VERSION ""

NS_ :

BS_:

BU_: AGSM BCM BSM CADM DMSM DTCM ECM EVCU2 GNMM HCP IPC RFHM SGW TCM
BO_ 1443 IPC_VEHICLE_SETUP: 48 IPC
 SG_ Act_Lane_Mgt : 91|2@0+ (1,0) [0|3] "-" BCM,CADM,SGW
 SG_ Act_Lane_Mgt_Strength : 123|2@0+ (1,0) [0|3] "-" BCM,CADM,SGW
 SG_ Active_Park_Mode : 219|1@0+ (1,0) [0|1] "" BCM,BSM,SGW
 SG_ Active_Park_Prox_Chime : 218|1@0+ (1,0) [0|1] "" BCM,SGW
 SG_ AmbientLightingLevel : 118|4@0+ (1,0) [0|15] "" SGW
 SG_ Auto_Fold_Mirr : 255|1@0+ (1,0) [0|1] "-" BCM,SGW
 SG_ AutoHighBeamEnable : 92|1@0+ (1,0) [0|1] "-" BCM,SGW
 SG_ AutoParkBrake : 103|1@0+ (1,0) [0|1] "" BCM,BSM,SGW
 SG_ AutoUnlockDoorExit : 162|1@0+ (1,0) [0|1] "-" BCM,SGW
 SG_ Backup_Cam_Delay : 173|1@0+ (1,0) [0|1] "-" BCM,SGW
 SG_ BSDEnable : 140|2@0+ (1,0) [0|3] "" BCM,CADM,SGW
 SG_ Consum_Unit : 238|3@0+ (1,0) [0|7] "" BCM,SGW
 SG_ CorneringEnable : 82|1@0+ (1,0) [0|1] "-" BCM,SGW
 SG_ CRC_IPCVS1 : 319|8@0+ (1,0) [0|255] "-" CADM
 SG_ Dist_Unit : 231|1@0+ (1,0) [0|1] "" BCM,ECM,SGW
 SG_ DRLEnable : 80|1@0+ (1,0) [0|1] "-" BCM,SGW
 SG_ Drowsy_Driver_Alert : 120|1@0+ (1,0) [0|1] "-" BCM,CADM,SGW
 SG_ DynamicGrid : 100|1@0+ (1,0) [0|1] "" BCM,SGW
 SG_ Easy_Exit_D : 174|1@0+ (1,0) [0|1] "-" BCM,SGW
 SG_ Eng_Off_Pwr_Delay : 187|2@0+ (1,0) [0|3] "-" BCM,SGW
 SG_ EPB_MaintenanceMode : 155|1@0+ (1,0) [0|1] "-" SGW
 SG_ FlashLightWLock : 159|1@0+ (1,0) [0|1] "-" BCM,SGW
 SG_ FOA_AppAlert_Disable_UserReq : 290|1@0+ (1,0) [0|1] "" BCM
 SG_ FSFCWPlusActivationMode : 149|2@0+ (1,0) [0|3] "-" BCM,CADM,SGW
 SG_ FSFCWPlusSetting : 143|3@0+ (1,0) [0|7] "-" BCM,CADM,SGW
 SG_ Fwrd_Cam_Guidelines : 189|1@0+ (1,0) [0|1] "-" BCM,SGW
 SG_ GreetingLightsEnable : 81|1@0+ (1,0) [0|1] "-" BCM,SGW
 SG_ HeadlightsOffDelay : 145|2@0+ (1,0) [0|3] "-" BCM,SGW
 SG_ HeadLightWipers : 167|1@0+ (1,0) [0|1] "-" BCM,SGW
 SG_ Hill_Start_Assist : 184|1@0+ (1,0) [0|1] "-" BCM,BSM,SGW
 SG_ HourMode : 87|1@0+ (1,0) [0|1] "-" BCM,SGW
 SG_ HP_Unit : 245|2@0+ (1,0) [0|3] "" BCM,SGW
 SG_ Illuminated_Approach : 68|2@0+ (1,0) [0|3] "-" BCM,SGW
 SG_ IPCProgrammed : 40|1@0+ (1,0) [0|1] "-" BCM,SGW
 SG_ LanguageSelection : 135|8@0+ (1,0) [0|255] "-" BCM,SGW
 SG_ LDW_Intensity : 154|2@0+ (1,0) [0|3] "-" BCM,CADM,SGW
 SG_ LDW_Sensibility : 147|2@0+ (1,0) [0|3] "-" BCM,CADM,SGW
 SG_ MessageCounter_IPCVS1 : 307|4@0+ (1,0) [0|15] "-" CADM
 SG_ NavRepetition : 105|1@0+ (1,0) [0|1] "" BCM,SGW
 SG_ New_Spd_Zone_Ind : 247|2@0+ (1,0) [0|3] "" BCM,SGW
 SG_ Paddle_Shifter : 188|1@0+ (1,0) [0|1] "-" BCM,SGW
 SG_ PamChimeVolumeFront : 107|2@0+ (1,0) [0|3] "" BCM,SGW
 SG_ PamChimeVolumeRear : 111|2@0+ (1,0) [0|3] "" BCM,SGW
 SG_ PassiveEntry : 101|1@0+ (1,0) [0|1] "" BCM,RFHM,SGW
 SG_ Ped_EM_Brk_Warn_Act : 175|1@0+ (1,0) [0|1] "-" BCM,SGW
 SG_ PhoneRepetition : 114|1@0+ (1,0) [0|1] "" BCM,SGW
 SG_ PLGAlert : 168|1@0+ (1,0) [0|1] "-" BCM,SGW
 SG_ Power_Side_Step : 220|1@0+ (1,0) [0|1] "" BCM,SGW
 SG_ Proximity_WU : 121|1@0+ (1,0) [0|1] "-" BCM,RFHM,SGW
 SG_ PwrLev : 7|3@0+ (1,0) [0|7] "" BCM,EVCU2,SGW
 SG_ RainSensorLevel : 93|1@0+ (1,0) [0|1] "-" BCM,SGW
 SG_ Rdy_To_Drive : 223|1@0+ (1,0) [0|1] "" SGW
 SG_ Rear_Brk_Asst : 190|1@0+ (1,0) [0|1] "" BCM,SGW
 SG_ RemoteDoorUnlock : 102|1@0+ (1,0) [0|1] "" BCM,SGW
 SG_ RemStNrmlStEnbl : 178|2@0+ (1,0) [0|3] "-" BCM,SGW
 SG_ RKEMemoryLinkEnable : 166|1@0+ (1,0) [0|1] "-" BCM,SGW
 SG_ SOC_Max_Lev : 308|1@0+ (1,0) [0|1] "" EVCU2
 SG_ SoundHornLock : 127|2@0+ (1,0) [0|3] "" BCM,SGW
 SG_ SoundHornRemoteStart : 104|1@0+ (1,0) [0|1] "" BCM,SGW
 SG_ Spaak : 289|1@0+ (1,0) [0|1] "-" BCM,RFHM,SGW
 SG_ Speed_Unit : 253|1@0+ (1,0) [0|1] "" BCM,CADM,SGW
 SG_ SpeedLockDoorEnable : 94|1@0+ (1,0) [0|1] "-" BCM,SGW
 SG_ StaticGrid : 99|1@0+ (1,0) [0|1] "" BCM,SGW
 SG_ Susp_Auto_Ent_Ext : 195|1@0+ (1,0) [0|1] "" BCM,SGW
 SG_ Susp_Aux_Mode : 212|2@0+ (1,0) [0|3] "" BCM,SGW
 SG_ Susp_Disp_Message : 207|1@0+ (1,0) [0|1] "" BCM,SGW
 SG_ Susp_Flsh_Lght_Low : 198|1@0+ (1,0) [0|1] "" BCM,SGW
 SG_ Susp_Sound_Hrn_Low : 199|1@0+ (1,0) [0|1] "" BCM,SGW
 SG_ Susp_Tire_Jack : 200|1@0+ (1,0) [0|1] "" BCM,SGW
 SG_ SVC_Delay : 192|1@0+ (1,0) [0|1] "" BCM,SGW
 SG_ SVC_Guidelines : 193|1@0+ (1,0) [0|1] "" BCM,SGW
 SG_ TelematicSetupACK : 97|2@0+ (1,0) [0|3] "-" BCM,SGW
 SG_ Temp_Unit : 239|1@0+ (1,0) [0|1] "" BCM,SGW
 SG_ Tilt_Mirr_Rev : 210|1@0+ (1,0) [0|1] "" BCM,SGW
 SG_ Tire_Fill_Alert : 215|1@0+ (1,0) [0|1] "" BCM,RFHM,SGW
 SG_ Torque_Unit : 254|1@0+ (1,0) [0|1] "" BCM,SGW
 SG_ Traffic_Sign_Info : 230|1@0+ (1,0) [0|1] "" BCM,CADM,SGW
 SG_ Traffic_Sign_Warn : 171|3@0+ (1,0) [0|3] "" BCM,SGW
 SG_ Trail_Brk_Type : 217|2@0+ (1,0) [0|3] "" BCM,SGW
 SG_ Trail_Name : 235|4@0+ (1,0) [0|16] "" BCM,SGW
 SG_ Trail_Num : 214|2@0+ (1,0) [0|3] "" BCM,SGW
 SG_ Trailer_detection_blind_spot : 310|1@0+ (1,0) [0|1] "-" BCM,CADM,SGW
 SG_ TyrePress_Unit : 243|2@0+ (1,0) [0|3] "" BCM,SGW

BO_ 1474 IPC_VEHICLE_SETUP2: 48 IPC
 SG_ AUX1_HLEnbl : 9|1@0+ (1,0) [0|1] "" BCM,SGW
 SG_ AUX1_PWRMD : 213|1@0+ (1,0) [0|1] "" BCM,SGW
 SG_ AUX1_TYPE : 13|1@0+ (1,0) [0|1] "" BCM,SGW
 SG_ AUX2_HLEnbl : 8|1@0+ (1,0) [0|1] "" BCM,SGW
 SG_ AUX2_PWRMD : 0|1@0+ (1,0) [0|1] "" BCM,SGW
 SG_ AUX2_TYPE : 12|1@0+ (1,0) [0|1] "" BCM,SGW
 SG_ AUX3_HLEnbl : 23|1@0+ (1,0) [0|1] "" BCM,SGW
 SG_ AUX3_PWRMD : 15|1@0+ (1,0) [0|1] "" BCM,SGW
 SG_ AUX3_TYPE : 11|1@0+ (1,0) [0|1] "" BCM,SGW
 SG_ AUX4_HLEnbl : 22|1@0+ (1,0) [0|1] "" BCM,SGW
 SG_ AUX4_PWRMD : 14|1@0+ (1,0) [0|1] "" BCM,SGW
 SG_ AUX4_TYPE : 10|1@0+ (1,0) [0|1] "" BCM,SGW
 SG_ AUX5_HLEnbl : 55|1@0+ (1,0) [0|1] "" BCM,SGW
 SG_ AUX5_PWRMD : 43|1@0+ (1,0) [0|1] "" BCM,SGW
 SG_ AUX5_TYPE : 41|1@0+ (1,0) [0|1] "" BCM,SGW
 SG_ AUX6_HLEnbl : 54|1@0+ (1,0) [0|1] "" BCM,SGW
 SG_ AUX6_PWRMD : 42|1@0+ (1,0) [0|1] "" BCM,SGW
 SG_ AUX6_TYPE : 40|1@0+ (1,0) [0|1] "" BCM,SGW
 SG_ Default_Ride_Height : 44|1@0+ (1,0) [0|1] "" BCM,SGW
 SG_ Display_Synch : 59|1@0+ (1,0) [0|1] "" SGW
 SG_ EPB_Service_Mode : 39|1@0+ (1,0) [0|1] "" BCM,SGW
 SG_ FOA_Alert_Type : 6|2@0+ (1,0) [0|3] "" BCM,SGW
 SG_ Fuel_Saver_Display : 26|1@0+ (1,0) [0|1] "" BCM,SGW
 SG_ ParkSenseSignalView : 37|1@0+ (1,0) [0|1] "" BCM,SGW
 SG_ PFTM_Alert : 95|1@0+ (1,0) [0|1] "" BCM,SGW
 SG_ PFTM_Enable : 94|1@0+ (1,0) [0|1] "" SGW
 SG_ Power_Tailgate_Enable : 53|1@0+ (1,0) [0|1] "" BCM,SGW
 SG_ Rear_G_LGT_with_Cargo_Lights : 47|1@0+ (1,0) [0|1] "" BCM,SGW
 SG_ Rear_Guidance_Light_Status : 62|1@0+ (1,0) [0|1] "" BCM,SGW
 SG_ Rear_Lights_with_Approach : 50|1@0+ (1,0) [0|1] "" BCM,SGW
 SG_ SignatureLightingEnable : 93|1@0+ (1,0) [0|1] "" BCM,SGW
 SG_ Trailer_Light_Check : 7|1@0+ (1,0) [0|1] "" BCM,SGW
 SG_ TSI_Offset_Kph : 31|4@0+ (1,0) [0|15] "" BCM,IPC,SGW
 SG_ TSI_Offset_Mph : 19|4@0+ (1,0) [0|15] "" BCM,IPC,SGW
 SG_ TurnSignalView : 34|2@0+ (1,0) [0|3] "" BCM,SGW
 SG_ WorksiteINVM_Audible_LFW : 61|1@0+ (1,0) [0|1] "" BCM,SGW
 SG_ WorksiteINVM_Visual_LFW : 60|1@0+ (1,0) [0|1] "" BCM,SGW

BO_ 753 LV_CHARGER1: 32 HCP
 SG_ CRC_LV_CHARGER1 : 191|8@0+ (1,0) [0|255] "-" ECM
 SG_ DCDC_OperationModeSts : 7|4@0+ (1,0) [0|0] "-" ECM,SGW
 SG_ HVDC_CurrentFeedback : 3|12@0+ (0.1,-149) [-149|150] "Amp" ECM
 SG_ HVDC_VoltageFeedback : 35|12@0+ (0.125,0) [0|510] "V" ECM
 SG_ LVDC_CurrentFeedback : 19|12@0+ (0.15,-299) [-299|299.5] "Amp" ECM
 SG_ MessageCounter_LV_CHARGER1 : 179|4@0+ (1,0) [0|15] "-" ECM

BO_ 125 MESS_TTPM1: 32 RFHM
 SG_ MESS_TTPM1 : 7|64@0+ (1,0) [0|0] "" SGW

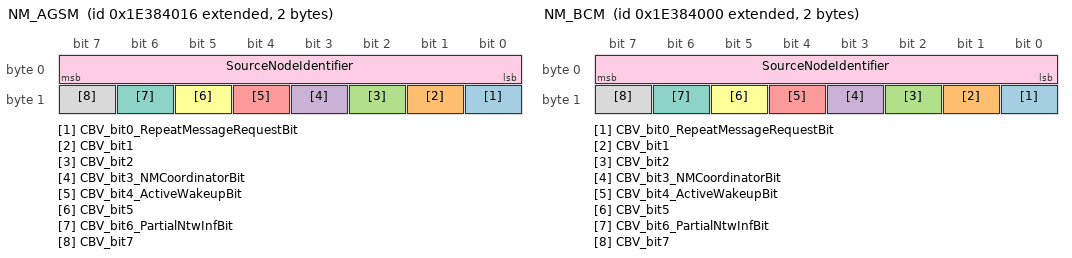
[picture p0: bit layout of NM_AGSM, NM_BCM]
BO_ 2654486550 NM_AGSM: 2 AGSM
 SG_ CBV_bit0_RepeatMessageRequestBit : 8|1@0+ (1,0) [0|1] "" BCM,BSM,CADM,DTCM,ECM,EVCU2,GNMM,HCP,IPC,RFHM,SGW,TCM
 SG_ CBV_bit1 : 9|1@0+ (1,0) [0|1] "" BCM,BSM,CADM,DTCM,ECM,EVCU2,GNMM,HCP,IPC,RFHM,SGW,TCM
 SG_ CBV_bit2 : 10|1@0+ (1,0) [0|1] "" BCM,BSM,CADM,DTCM,ECM,EVCU2,GNMM,HCP,IPC,RFHM,SGW,TCM
 SG_ CBV_bit3_NMCoordinatorBit : 11|1@0+ (1,0) [0|1] "" BCM,BSM,CADM,DTCM,ECM,EVCU2,GNMM,HCP,IPC,RFHM,SGW,TCM
 SG_ CBV_bit4_ActiveWakeupBit : 12|1@0+ (1,0) [0|1] "" BCM,BSM,CADM,DTCM,ECM,EVCU2,GNMM,HCP,IPC,RFHM,SGW,TCM
 SG_ CBV_bit5 : 13|1@0+ (1,0) [0|1] "" BCM,BSM,CADM,DTCM,ECM,EVCU2,GNMM,HCP,IPC,RFHM,SGW,TCM
 SG_ CBV_bit6_PartialNtwInfBit : 14|1@0+ (1,0) [0|1] "" BCM,BSM,CADM,DTCM,ECM,EVCU2,GNMM,HCP,IPC,RFHM,SGW,TCM
 SG_ CBV_bit7 : 15|1@0+ (1,0) [0|1] "" BCM,BSM,CADM,DTCM,ECM,EVCU2,GNMM,HCP,IPC,RFHM,SGW,TCM
 SG_ SourceNodeIdentifier : 7|8@0+ (1,0) [0|63] "-" BCM,BSM,CADM,DTCM,ECM,EVCU2,GNMM,HCP,IPC,RFHM,SGW,TCM

BO_ 2654486528 NM_BCM: 2 BCM
 SG_ CBV_bit0_RepeatMessageRequestBit : 8|1@0+ (1,0) [0|1] "" AGSM,BSM,CADM,DTCM,ECM,EVCU2,GNMM,HCP,IPC,RFHM,SGW,TCM
 SG_ CBV_bit1 : 9|1@0+ (1,0) [0|1] "" AGSM,BSM,CADM,DTCM,ECM,EVCU2,GNMM,HCP,IPC,RFHM,SGW,TCM
 SG_ CBV_bit2 : 10|1@0+ (1,0) [0|1] "" AGSM,BSM,CADM,DTCM,ECM,EVCU2,GNMM,HCP,IPC,RFHM,SGW,TCM
 SG_ CBV_bit3_NMCoordinatorBit : 11|1@0+ (1,0) [0|1] "" AGSM,BSM,CADM,DTCM,ECM,EVCU2,GNMM,HCP,IPC,RFHM,SGW,TCM
 SG_ CBV_bit4_ActiveWakeupBit : 12|1@0+ (1,0) [0|1] "" AGSM,BSM,CADM,DTCM,ECM,EVCU2,GNMM,HCP,IPC,RFHM,SGW,TCM
 SG_ CBV_bit5 : 13|1@0+ (1,0) [0|1] "" AGSM,BSM,CADM,DTCM,ECM,EVCU2,GNMM,HCP,IPC,RFHM,SGW,TCM
 SG_ CBV_bit6_PartialNtwInfBit : 14|1@0+ (1,0) [0|1] "" AGSM,BSM,CADM,DTCM,ECM,EVCU2,GNMM,HCP,IPC,RFHM,SGW,TCM
 SG_ CBV_bit7 : 15|1@0+ (1,0) [0|1] "" AGSM,BSM,CADM,DTCM,ECM,EVCU2,GNMM,HCP,IPC,RFHM,SGW,TCM
 SG_ SourceNodeIdentifier : 7|8@0+ (1,0) [0|255] "-" AGSM,BSM,CADM,DTCM,ECM,EVCU2,GNMM,HCP,IPC,RFHM,SGW,TCM

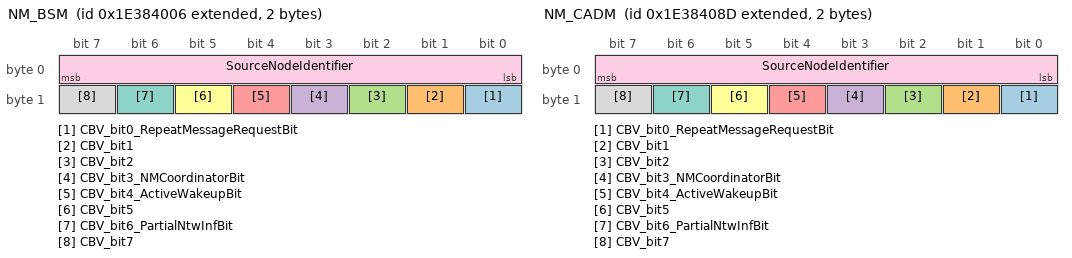
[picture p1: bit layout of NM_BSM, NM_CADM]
BO_ 2654486534 NM_BSM: 2 BSM
 SG_ CBV_bit0_RepeatMessageRequestBit : 8|1@0+ (1,0) [0|1] "" AGSM,BCM,CADM,DTCM,ECM,EVCU2,GNMM,HCP,IPC,RFHM,SGW,TCM
 SG_ CBV_bit1 : 9|1@0+ (1,0) [0|1] "" AGSM,BCM,CADM,DTCM,ECM,EVCU2,GNMM,HCP,IPC,RFHM,SGW,TCM
 SG_ CBV_bit2 : 10|1@0+ (1,0) [0|1] "" AGSM,BCM,CADM,DTCM,ECM,EVCU2,GNMM,HCP,IPC,RFHM,SGW,TCM
 SG_ CBV_bit3_NMCoordinatorBit : 11|1@0+ (1,0) [0|1] "" AGSM,BCM,CADM,DTCM,ECM,EVCU2,GNMM,HCP,IPC,RFHM,SGW,TCM
 SG_ CBV_bit4_ActiveWakeupBit : 12|1@0+ (1,0) [0|1] "" AGSM,BCM,CADM,DTCM,ECM,EVCU2,GNMM,HCP,IPC,RFHM,SGW,TCM
 SG_ CBV_bit5 : 13|1@0+ (1,0) [0|1] "" AGSM,BCM,CADM,DTCM,ECM,EVCU2,GNMM,HCP,IPC,RFHM,SGW,TCM
 SG_ CBV_bit6_PartialNtwInfBit : 14|1@0+ (1,0) [0|1] "" AGSM,BCM,CADM,DTCM,ECM,EVCU2,GNMM,HCP,IPC,RFHM,SGW,TCM
 SG_ CBV_bit7 : 15|1@0+ (1,0) [0|1] "" AGSM,BCM,CADM,DTCM,ECM,EVCU2,GNMM,HCP,IPC,RFHM,SGW,TCM
 SG_ SourceNodeIdentifier : 7|8@0+ (1,0) [0|255] "-" AGSM,BCM,CADM,DTCM,ECM,EVCU2,GNMM,HCP,IPC,RFHM,SGW,TCM

BO_ 2654486669 NM_CADM: 2 CADM
 SG_ CBV_bit0_RepeatMessageRequestBit : 8|1@0+ (1,0) [0|1] "" AGSM,BCM,BSM,DTCM,ECM,EVCU2,GNMM,HCP,IPC,RFHM,SGW,TCM
 SG_ CBV_bit1 : 9|1@0+ (1,0) [0|1] "" AGSM,BCM,BSM,DTCM,ECM,EVCU2,GNMM,HCP,IPC,RFHM,SGW,TCM
 SG_ CBV_bit2 : 10|1@0+ (1,0) [0|1] "" AGSM,BCM,BSM,DTCM,ECM,EVCU2,GNMM,HCP,IPC,RFHM,SGW,TCM
 SG_ CBV_bit3_NMCoordinatorBit : 11|1@0+ (1,0) [0|1] "" AGSM,BCM,BSM,DTCM,ECM,EVCU2,GNMM,HCP,IPC,RFHM,SGW,TCM
 SG_ CBV_bit4_ActiveWakeupBit : 12|1@0+ (1,0) [0|1] "" AGSM,BCM,BSM,DTCM,ECM,EVCU2,GNMM,HCP,IPC,RFHM,SGW,TCM
 SG_ CBV_bit5 : 13|1@0+ (1,0) [0|1] "" AGSM,BCM,BSM,DTCM,ECM,EVCU2,GNMM,HCP,IPC,RFHM,SGW,TCM
 SG_ CBV_bit6_PartialNtwInfBit : 14|1@0+ (1,0) [0|1] "" AGSM,BCM,BSM,DTCM,ECM,EVCU2,GNMM,HCP,IPC,RFHM,SGW,TCM
 SG_ CBV_bit7 : 15|1@0+ (1,0) [0|1] "" AGSM,BCM,BSM,DTCM,ECM,EVCU2,GNMM,HCP,IPC,RFHM,SGW,TCM
 SG_ SourceNodeIdentifier : 7|8@0+ (1,0) [0|255] "-" AGSM,BCM,BSM,DTCM,ECM,EVCU2,GNMM,HCP,IPC,RFHM,SGW,TCM

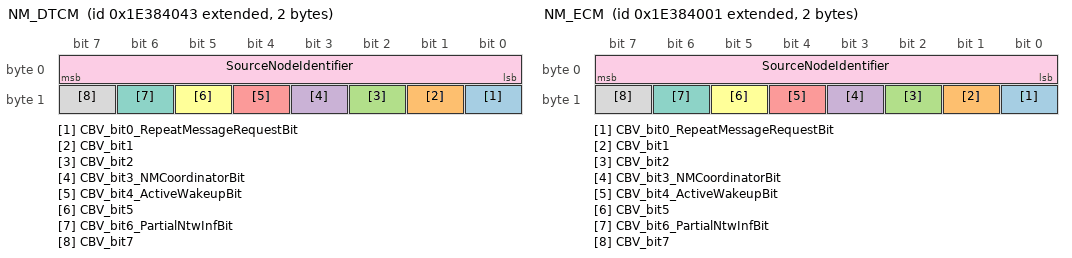
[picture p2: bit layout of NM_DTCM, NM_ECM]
BO_ 2654486595 NM_DTCM: 2 DTCM
 SG_ CBV_bit0_RepeatMessageRequestBit : 8|1@0+ (1,0) [0|1] "" AGSM,BCM,BSM,CADM,ECM,EVCU2,GNMM,HCP,IPC,RFHM,SGW,TCM
 SG_ CBV_bit1 : 9|1@0+ (1,0) [0|1] "" AGSM,BCM,BSM,CADM,ECM,EVCU2,GNMM,HCP,IPC,RFHM,SGW,TCM
 SG_ CBV_bit2 : 10|1@0+ (1,0) [0|1] "" AGSM,BCM,BSM,CADM,ECM,EVCU2,GNMM,HCP,IPC,RFHM,SGW,TCM
 SG_ CBV_bit3_NMCoordinatorBit : 11|1@0+ (1,0) [0|1] "" AGSM,BCM,BSM,CADM,ECM,EVCU2,GNMM,HCP,IPC,RFHM,SGW,TCM
 SG_ CBV_bit4_ActiveWakeupBit : 12|1@0+ (1,0) [0|1] "" AGSM,BCM,BSM,CADM,ECM,EVCU2,GNMM,HCP,IPC,RFHM,SGW,TCM
 SG_ CBV_bit5 : 13|1@0+ (1,0) [0|1] "" AGSM,BCM,BSM,CADM,ECM,EVCU2,GNMM,HCP,IPC,RFHM,SGW,TCM
 SG_ CBV_bit6_PartialNtwInfBit : 14|1@0+ (1,0) [0|1] "" AGSM,BCM,BSM,CADM,ECM,EVCU2,GNMM,HCP,IPC,RFHM,SGW,TCM
 SG_ CBV_bit7 : 15|1@0+ (1,0) [0|1] "" AGSM,BCM,BSM,CADM,ECM,EVCU2,GNMM,HCP,IPC,RFHM,SGW,TCM
 SG_ SourceNodeIdentifier : 7|8@0+ (1,0) [0|255] "-" AGSM,BCM,BSM,CADM,ECM,EVCU2,GNMM,HCP,IPC,RFHM,SGW,TCM

BO_ 2654486529 NM_ECM: 2 ECM
 SG_ CBV_bit0_RepeatMessageRequestBit : 8|1@0+ (1,0) [0|1] "" AGSM,BCM,BSM,CADM,DTCM,EVCU2,GNMM,HCP,IPC,RFHM,SGW,TCM
 SG_ CBV_bit1 : 9|1@0+ (1,0) [0|1] "" AGSM,BCM,BSM,CADM,DTCM,EVCU2,GNMM,HCP,IPC,RFHM,SGW,TCM
 SG_ CBV_bit2 : 10|1@0+ (1,0) [0|1] "" AGSM,BCM,BSM,CADM,DTCM,EVCU2,GNMM,HCP,IPC,RFHM,SGW,TCM
 SG_ CBV_bit3_NMCoordinatorBit : 11|1@0+ (1,0) [0|1] "" AGSM,BCM,BSM,CADM,DTCM,EVCU2,GNMM,HCP,IPC,RFHM,SGW,TCM
 SG_ CBV_bit4_ActiveWakeupBit : 12|1@0+ (1,0) [0|1] "" AGSM,BCM,BSM,CADM,DTCM,EVCU2,GNMM,HCP,IPC,RFHM,SGW,TCM
 SG_ CBV_bit5 : 13|1@0+ (1,0) [0|1] "" AGSM,BCM,BSM,CADM,DTCM,EVCU2,GNMM,HCP,IPC,RFHM,SGW,TCM
 SG_ CBV_bit6_PartialNtwInfBit : 14|1@0+ (1,0) [0|1] "" AGSM,BCM,BSM,CADM,DTCM,EVCU2,GNMM,HCP,IPC,RFHM,SGW,TCM
 SG_ CBV_bit7 : 15|1@0+ (1,0) [0|1] "" AGSM,BCM,BSM,CADM,DTCM,EVCU2,GNMM,HCP,IPC,RFHM,SGW,TCM
 SG_ SourceNodeIdentifier : 7|8@0+ (1,0) [0|255] "-" AGSM,BCM,BSM,CADM,DTCM,EVCU2,GNMM,HCP,IPC,RFHM,SGW,TCM

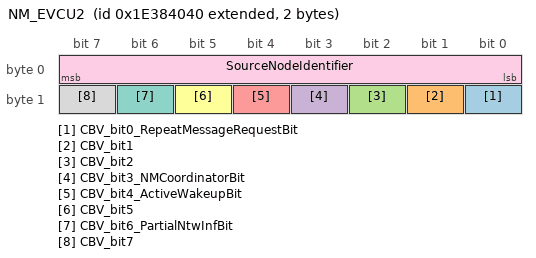
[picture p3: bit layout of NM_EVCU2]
BO_ 2654486592 NM_EVCU2: 2 EVCU2
 SG_ CBV_bit0_RepeatMessageRequestBit : 8|1@0+ (1,0) [0|1] "" AGSM,BCM,BSM,CADM,DTCM,ECM,GNMM,HCP,IPC,RFHM,SGW,TCM
 SG_ CBV_bit1 : 9|1@0+ (1,0) [0|1] "" AGSM,BCM,BSM,CADM,DTCM,ECM,GNMM,HCP,IPC,RFHM,SGW,TCM
 SG_ CBV_bit2 : 10|1@0+ (1,0) [0|1] "" AGSM,BCM,BSM,CADM,DTCM,ECM,GNMM,HCP,IPC,RFHM,SGW,TCM
 SG_ CBV_bit3_NMCoordinatorBit : 11|1@0+ (1,0) [0|1] "" AGSM,BCM,BSM,CADM,DTCM,ECM,GNMM,HCP,IPC,RFHM,SGW,TCM
 SG_ CBV_bit4_ActiveWakeupBit : 12|1@0+ (1,0) [0|1] "" AGSM,BCM,BSM,CADM,DTCM,ECM,GNMM,HCP,IPC,RFHM,SGW,TCM
 SG_ CBV_bit5 : 13|1@0+ (1,0) [0|1] "" AGSM,BCM,BSM,CADM,DTCM,ECM,GNMM,HCP,IPC,RFHM,SGW,TCM
 SG_ CBV_bit6_PartialNtwInfBit : 14|1@0+ (1,0) [0|1] "" AGSM,BCM,BSM,CADM,DTCM,ECM,GNMM,HCP,IPC,RFHM,SGW,TCM
 SG_ CBV_bit7 : 15|1@0+ (1,0) [0|1] "" AGSM,BCM,BSM,CADM,DTCM,ECM,GNMM,HCP,IPC,RFHM,SGW,TCM
 SG_ SourceNodeIdentifier : 7|8@0+ (1,0) [0|255] "-" AGSM,BCM,BSM,CADM,DTCM,ECM,GNMM,HCP,IPC,RFHM,SGW,TCM

CM_ SG_ 1443 Act_Lane_Mgt "Act Lane Mgt setting";
CM_ SG_ 1443 Act_Lane_Mgt_Strength "Act Lane Mgt Strength setting";
CM_ SG_ 1443 Active_Park_Mode "Active Parksense Mode setting";
CM_ SG_ 1443 Active_Park_Prox_Chime "Active Parksense Proximity Chime setting";
CM_ SG_ 1443 AmbientLightingLevel "This signal is used to give information about the Ambient Lighting Level selected";
CM_ SG_ 1443 Auto_Fold_Mirr "Auto Folding Mirror setting";
CM_ SG_ 1443 AutoHighBeamEnable "This signal is used to give information about the Auto High Beam feature selected";
CM_ SG_ 1443 AutoParkBrake "This signal is used to give information about the Auto Park Brake selected";
CM_ SG_ 1443 AutoUnlockDoorExit "This signal is used to give information about the Auto Unlock Door on Exit feature selected";
CM_ SG_ 1443 Backup_Cam_Delay "Backup Camera Delay setting";
CM_ SG_ 1443 BSDEnable "This signal is used to give information about the Blind Spot Alert feature selected";
CM_ SG_ 1443 Consum_Unit "Consumption Unit setting";
CM_ SG_ 1443 CorneringEnable "This signal is used to give information about the Cornering Lights selected";
CM_ SG_ 1443 CRC_IPCVS1 "CRC according to SAE J1850 standard at each frame transmission.";
CM_ SG_ 1443 Dist_Unit "Distance Unit setting";
CM_ SG_ 1443 DRLEnable "This signal is used to give information about the DRL feature selected";
CM_ SG_ 1443 Drowsy_Driver_Alert "Drowsy Driver Alert setting";
CM_ SG_ 1443 DynamicGrid "Rear View Camera Dynamic Gridlines request";
CM_ SG_ 1443 Easy_Exit_D "Driver Easy Exit Seat setting";
CM_ SG_ 1443 Eng_Off_Pwr_Delay "Engine Off Power Delay setting";
CM_ SG_ 1443 EPB_MaintenanceMode "This signal is used to give information about the Maintenance Mode feature selected";
CM_ SG_ 1443 FlashLightWLock "This signal is used to give information about the Flash Light With Lock selected";
CM_ SG_ 1443 FOA_AppAlert_Disable_UserReq "Forgotten Object Alert IPC disable request";
CM_ SG_ 1443 FSFCWPlusActivationMode "This signal is used to give information about the FSFCW Activation Mode setting";
CM_ SG_ 1443 FSFCWPlusSetting "This signal is used to give information about the FSFCW setting";
CM_ SG_ 1443 Fwrd_Cam_Guidelines "Forward Facing Camera Guidelines setting";
CM_ SG_ 1443 GreetingLightsEnable "This signal is used to give information about the Greeting Lights selected";
CM_ SG_ 1443 HeadlightsOffDelay "This signal is used to give information about the Headlights Off Delay selected";
CM_ SG_ 1443 HeadLightWipers "Setting to turn on/off headlights with wipers";
CM_ SG_ 1443 Hill_Start_Assist "Hill Start Assist setting";
CM_ SG_ 1443 HourMode "This signal is used to give information about the Hour Mode selected.";
CM_ SG_ 1443 HP_Unit "Horsepower Unit setting";
CM_ SG_ 1443 Illuminated_Approach "Illuminated Approach setting";
CM_ SG_ 1443 IPCProgrammed "IPC Settings Defaults Programmed Status";
CM_ SG_ 1443 LanguageSelection "This signal is used to give information about the Language selected";
CM_ SG_ 1443 LDW_Intensity "This signal is used to give information about the LDW Intensity selected";
CM_ SG_ 1443 LDW_Sensibility "This signal is used to give information about the LDW Sensibility selected";
CM_ SG_ 1443 MessageCounter_IPCVS1 "This signal is a counter used for safety checks strategies. This counter is incremented of 1 (one) unit at each frame transmission.";
CM_ SG_ 1443 NavRepetition "This signal is used to give information about the Navigation Repetition selected";
CM_ SG_ 1443 New_Spd_Zone_Ind "New Speed Zone Indication setting";
CM_ SG_ 1443 Paddle_Shifter "Paddle Shifter setting";
CM_ SG_ 1443 PamChimeVolumeFront "This signal is used to give information about the PAM  Chime Volume selected";
CM_ SG_ 1443 PamChimeVolumeRear "This signal is used to give information about the PAM 8Ch Chime Volume selected";
CM_ SG_ 1443 PassiveEntry "This signal is used to give information about the Passive Entry selected";
CM_ SG_ 1443 Ped_EM_Brk_Warn_Act "Pedestrian Emergency Braking Warning & Active Braking setting";
CM_ SG_ 1443 PhoneRepetition "This signal is used to give information about the Phone Repetition selected";
CM_ SG_ 1443 PLGAlert "Setting to turn on/off the power liftgate chime";
CM_ SG_ 1443 Power_Side_Step "Power side step setting";
CM_ SG_ 1443 Proximity_WU "Proximity Wakeup setting";
CM_ SG_ 1443 PwrLev "This signal is used to give information about the Power Level selected.";
CM_ SG_ 1443 RainSensorLevel "This signal is used to give information about the Rain Sensor Level selected";
CM_ SG_ 1443 Rdy_To_Drive "Ready to Driver Pop Up setting";
CM_ SG_ 1443 Rear_Brk_Asst "Rear Braking Assist setting";
CM_ SG_ 1443 RemoteDoorUnlock "This signal is used to give information about the Remote Door Unlock selected";
CM_ SG_ 1443 RemStNrmlStEnbl "Setting to allow seat heating and venting for all starts, remote starts, or none";
CM_ SG_ 1443 RKEMemoryLinkEnable "To enable or disable RKE linked to memory";
CM_ SG_ 1443 SOC_Max_Lev "Customer top of SOC selection.";
CM_ SG_ 1443 SoundHornLock "This signal is used to give information about the Sound Horn with Lock selected";
CM_ SG_ 1443 SoundHornRemoteStart "This signal is used to give information about the Sound Horn with Remote Start selected";
CM_ SG_ 1443 Spaak "Spaak";
CM_ SG_ 1443 Speed_Unit "Speed Unit setting";
CM_ SG_ 1443 SpeedLockDoorEnable "This signal is used to give information about the Autoclose feature selected";
CM_ SG_ 1443 StaticGrid "Rear View Camera Static Gridlines request";
CM_ SG_ 1443 Susp_Auto_Ent_Ext "Suspension Auto Entry/Exit setting";
CM_ SG_ 1443 Susp_Aux_Mode "Suspension Auxiliary Modes setting";
CM_ SG_ 1443 Susp_Disp_Message "Suspension Display Messages setting";
CM_ SG_ 1443 Susp_Flsh_Lght_Low "Suspension Flash Lights with Lower setting";
CM_ SG_ 1443 Susp_Sound_Hrn_Low "Suspension Sound Horn with Lower setting";
CM_ SG_ 1443 Susp_Tire_Jack "Suspension Tire/Jack Mode setting";
CM_ SG_ 1443 SVC_Delay "Surround View Camera Delay setting";
CM_ SG_ 1443 SVC_Guidelines "Surround View Camera Guidelines setting";
CM_ SG_ 1443 TelematicSetupACK "Used to give information about the acknowledge of the requested setup changes by telematic module.";
CM_ SG_ 1443 Temp_Unit "Temperature Unit setting";
CM_ SG_ 1443 Tilt_Mirr_Rev "Tilt Mirrors in Reverse setting";
CM_ SG_ 1443 Tire_Fill_Alert "Tire Fill Alert setting";
CM_ SG_ 1443 Torque_Unit "Torque Unit setting";
CM_ SG_ 1443 Traffic_Sign_Info "Traffic Sign Information setting";
CM_ SG_ 1443 Traffic_Sign_Warn "Traffic Sign Warning setting";
CM_ SG_ 1443 Trail_Brk_Type "Trailer Brake Type setting";
CM_ SG_ 1443 Trail_Name "Trailer Name setting";
CM_ SG_ 1443 Trail_Num "Trailer Number setting";
CM_ SG_ 1443 Trailer_detection_blind_spot "Trailer_detection_blind_spot";
CM_ SG_ 1443 TyrePress_Unit "Tyre Pressure setting";
CM_ SG_ 1474 AUX1_HLEnbl "AUX Switch 1 Hold Last State";
CM_ SG_ 1474 AUX1_PWRMD "AUX Switch 1 Power Mode";
CM_ SG_ 1474 AUX1_TYPE "AUX Switch 1 Switch Type";
CM_ SG_ 1474 AUX2_HLEnbl "AUX Switch 2 Hold Last State";
CM_ SG_ 1474 AUX2_PWRMD "AUX Switch 2 Power Mode";
CM_ SG_ 1474 AUX2_TYPE "AUX Switch 2 Switch Type";
CM_ SG_ 1474 AUX3_HLEnbl "AUX Switch 3 Hold Last State";
CM_ SG_ 1474 AUX3_PWRMD "AUX Switch 3 Power Mode";
CM_ SG_ 1474 AUX3_TYPE "AUX Switch 3 Switch Type";
CM_ SG_ 1474 AUX4_HLEnbl "AUX Switch 4 Hold Last State";
CM_ SG_ 1474 AUX4_PWRMD "AUX Switch 4 Power Mode";
CM_ SG_ 1474 AUX4_TYPE "AUX Switch 4 Switch Type";
CM_ SG_ 1474 AUX5_HLEnbl "Aux switch 5 enable holding last state; enabled = [1]";
CM_ SG_ 1474 AUX5_PWRMD "Aux switch 5 power mode; ignition = [0], battery = [1]";
CM_ SG_ 1474 AUX5_TYPE "Aux switch 5 behavior; Latching = [0], Momentary = [1]";
CM_ SG_ 1474 AUX6_HLEnbl "Aux switch 6 enable holding last state; enabled = [1]";
CM_ SG_ 1474 AUX6_PWRMD "Aux switch 6 power mode; ignition = [0], battery = [1]";
CM_ SG_ 1474 AUX6_TYPE "Aux switch 6 behavior; Latching = [0], Momentary = [1]";
CM_ SG_ 1474 Default_Ride_Height "Default Ride Height setting; Enable Default Ride Height mode = [1]";
CM_ SG_ 1474 Display_Synch "Display Synch Customer Setting; ON = [1]";
CM_ SG_ 1474 EPB_Service_Mode "EPB service mode; Service mode = [1";
CM_ SG_ 1474 FOA_Alert_Type "Forgotten Object Alert Type";
CM_ SG_ 1474 Fuel_Saver_Display "Fuel saver display indicator status (1=enabled)";
CM_ SG_ 1474 ParkSenseSignalView "ParkSense Based Camera Activation settings";
CM_ SG_ 1474 PFTM_Alert "Power Front Trunk Audible Alert Enable status, enabled =[1]";
CM_ SG_ 1474 PFTM_Enable "Power Front Trunk Enable status, enabled =[1]";
CM_ SG_ 1474 Power_Tailgate_Enable "Tailgate enable status; enabled = [1]";
CM_ SG_ 1474 Rear_G_LGT_with_Cargo_Lights "Rear Guidance Lights status information, Enable= 1";
CM_ SG_ 1474 Rear_Guidance_Light_Status "Rear Guidance Light Status Setting; ON = [1]";
CM_ SG_ 1474 Rear_Lights_with_Approach "Rear Guidance Lighting with approach setting; On with Approach = [1]";
CM_ SG_ 1474 SignatureLightingEnable "Signature Lighting Enable/Disable";
CM_ SG_ 1474 Trailer_Light_Check "Automatic trailer light sequence activation on connect";
CM_ SG_ 1474 TSI_Offset_Kph "TSI_Offset_Kph";
CM_ SG_ 1474 TSI_Offset_Mph "TSI_Offset_Mph";
CM_ SG_ 1474 TurnSignalView "Turn Signal Activated Blind Spot Camera View with and without Trailer Options";
CM_ SG_ 1474 WorksiteINVM_Audible_LFW "Worksite Inverter Low Fuel Warning audible setting; ON = [1]";
CM_ SG_ 1474 WorksiteINVM_Visual_LFW "Worksite Inverter Low Fuel Warning visual setting; ON = [1]";
CM_ SG_ 753 CRC_LV_CHARGER1 "CRC according to SAE J1850 standard at each frame transmission.";
CM_ SG_ 753 DCDC_OperationModeSts "APM Operation  mode  Status";
CM_ SG_ 753 HVDC_CurrentFeedback "High side current feedback";
CM_ SG_ 753 HVDC_VoltageFeedback "High side  voltage feedback";
CM_ SG_ 753 LVDC_CurrentFeedback "Low side current feedback";
CM_ SG_ 753 MessageCounter_LV_CHARGER1 "This signal is a counter used for safety checks strategies. This counter is incremented of 1 (one) unit at each frame transmission.";
CM_ SG_ 125 MESS_TTPM1 "Measurement data";
CM_ SG_ 2654486550 CBV_bit0_RepeatMessageRequestBit "Repeat Message Request Bit";
CM_ SG_ 2654486550 CBV_bit3_NMCoordinatorBit "NM Coordinator Sleep Bit";
CM_ SG_ 2654486550 CBV_bit4_ActiveWakeupBit "Active Wakeup Bit";
CM_ SG_ 2654486550 CBV_bit6_PartialNtwInfBit "Partial Network Information Bit (PNI)";
CM_ SG_ 2654486550 SourceNodeIdentifier "Source Node Identifier";
CM_ SG_ 2654486528 CBV_bit0_RepeatMessageRequestBit "Repeat Message Request Bit";
CM_ SG_ 2654486528 CBV_bit3_NMCoordinatorBit "NM Coordinator Sleep Bit";
CM_ SG_ 2654486528 CBV_bit4_ActiveWakeupBit "Active Wakeup Bit";
CM_ SG_ 2654486528 CBV_bit6_PartialNtwInfBit "Partial Network Information Bit (PNI)";
CM_ SG_ 2654486528 SourceNodeIdentifier "Source Node Identifier";
CM_ SG_ 2654486534 CBV_bit0_RepeatMessageRequestBit "Repeat Message Request Bit";
CM_ SG_ 2654486534 CBV_bit3_NMCoordinatorBit "NM Coordinator Sleep Bit";
CM_ SG_ 2654486534 CBV_bit4_ActiveWakeupBit "Active Wakeup Bit";
CM_ SG_ 2654486534 CBV_bit6_PartialNtwInfBit "Partial Network Information Bit (PNI)";
CM_ SG_ 2654486534 SourceNodeIdentifier "Source Node Identifier";
CM_ SG_ 2654486669 CBV_bit0_RepeatMessageRequestBit "Repeat Message Request Bit";
CM_ SG_ 2654486669 CBV_bit3_NMCoordinatorBit "NM Coordinator Sleep Bit";
CM_ SG_ 2654486669 CBV_bit4_ActiveWakeupBit "Active Wakeup Bit";
CM_ SG_ 2654486669 CBV_bit6_PartialNtwInfBit "Partial Network Information Bit (PNI)";
CM_ SG_ 2654486669 SourceNodeIdentifier "Source Node Identifier";
CM_ SG_ 2654486595 CBV_bit0_RepeatMessageRequestBit "Repeat Message Request Bit";
CM_ SG_ 2654486595 CBV_bit3_NMCoordinatorBit "NM Coordinator Sleep Bit";
CM_ SG_ 2654486595 CBV_bit4_ActiveWakeupBit "Active Wakeup Bit";
CM_ SG_ 2654486595 CBV_bit6_PartialNtwInfBit "Partial Network Information Bit (PNI)";
CM_ SG_ 2654486595 SourceNodeIdentifier "Source Node Identifier";
CM_ SG_ 2654486529 CBV_bit0_RepeatMessageRequestBit "Repeat Message Request Bit";
CM_ SG_ 2654486529 CBV_bit3_NMCoordinatorBit "NM Coordinator Sleep Bit";
CM_ SG_ 2654486529 CBV_bit4_ActiveWakeupBit "Active Wakeup Bit";
CM_ SG_ 2654486529 CBV_bit6_PartialNtwInfBit "Partial Network Information Bit (PNI)";
CM_ SG_ 2654486529 SourceNodeIdentifier "Source Node Identifier";

BA_DEF_ SG_ "GenSigStartValue" INT 0 2147483647;
BA_DEF_ SG_ "GenSigInactiveValue" INT 0 2147483647;
BA_DEF_ SG_ "GenSigSendType" ENUM "NotUsed","OnWrite","OnWriteWithRepetition","OnChange","OnChangeWithRepetition","IfActive","IfActiveWithRepetition","NoSigSendType";
BA_DEF_ SG_ "SystemSignalLongSymbol" STRING ;
BA_DEF_ SG_ "GenSigTimeoutTime_AGSM" INT 0 65535;
BA_DEF_ SG_ "GenSigTimeoutTime_BCM" INT 0 65535;
BA_DEF_ SG_ "GenSigTimeoutTime_BSM" INT 0 65535;
BA_DEF_ SG_ "GenSigTimeoutTime_CADM" INT 0 65535;
BA_DEF_ SG_ "GenSigTimeoutTime_DMSM" INT 0 65535;
BA_DEF_ SG_ "GenSigTimeoutTime_DTCM" INT 0 65535;
BA_DEF_ SG_ "GenSigTimeoutTime_ECM" INT 0 65535;
BA_DEF_ SG_ "GenSigTimeoutTime_EVCU2" INT 0 65535;
BA_DEF_ SG_ "GenSigTimeoutTime_GNMM" INT 0 65535;
BA_DEF_ SG_ "GenSigTimeoutTime_HCP" INT 0 65535;
BA_DEF_ SG_ "GenSigTimeoutTime_IPC" INT 0 65535;
BA_DEF_ SG_ "GenSigTimeoutTime_RFHM" INT 0 65535;
BA_DEF_ SG_ "GenSigTimeoutTime_SGW" INT 0 65535;
BA_DEF_ SG_ "GenSigTimeoutTime_TCM" INT 0 65535;
BA_DEF_ BO_ "DiagRequest" ENUM "No","Yes";
BA_DEF_ BO_ "Type" ENUM "P","C","PE","COC","PE_Cntrl","E","E_Cntrl","OC","S","BAF","DC","EM","MM","ISO-TP","-";
BA_DEF_ BO_ "DiagResponse" ENUM "No","Yes";
BA_DEF_ BO_ "NmMessage" ENUM "No","Yes";
BA_DEF_ BO_ "GenMsgSendType" ENUM "Cyclic","NotUsed","NotUsed","NotUsed","NotUsed","NotUsed","NotUsed","NotUsed","NoMsgSendType";
BA_DEF_ BO_ "GenMsgNrOfRepetition" INT 0 255;
BA_DEF_ BO_ "GenMsgILSupport" ENUM "No","Yes";
BA_DEF_ BO_ "GenMsgStartDelayTime" INT 0 65535;
BA_DEF_ BO_ "GenMsgCycleTimeFast" INT 0 65535;
BA_DEF_ BO_ "GenMsgCycleTime" INT 0 65535;
BA_DEF_ BO_ "GenMsgDelayTime" INT 0 65535;
BA_DEF_ BO_ "NmAsrMessage" ENUM "No","Yes";
BA_DEF_ BO_ "DiagState" ENUM "No","Yes";
BA_DEF_ BO_ "DiagConnection" HEX 0 65535;
BA_DEF_ BO_ "VFrameFormat" ENUM "StandardCAN","ExtendedCAN","reserved","reserved","reserved","reserved","reserved","reserved","reserved","reserved","reserved","reserved","reserved","reserved","StandardCAN_FD","ExtendedCAN_FD";
BA_DEF_ BO_ "CANFD_BRS" ENUM "No","Yes";
BA_DEF_DEF_ "DiagRequest" "No";
BA_DEF_DEF_ "Type" "-";
BA_DEF_DEF_ "DiagResponse" "No";
BA_DEF_DEF_ "NmMessage" "No";
BA_DEF_DEF_ "GenMsgSendType" "NoMsgSendType";
BA_DEF_DEF_ "GenMsgNrOfRepetition" 0;
BA_DEF_DEF_ "GenMsgILSupport" "No";
BA_DEF_DEF_ "GenMsgStartDelayTime" 0;
BA_DEF_DEF_ "GenMsgCycleTimeFast" 0;
BA_DEF_DEF_ "GenMsgCycleTime" 0;
BA_DEF_DEF_ "GenMsgDelayTime" 0;
BA_DEF_DEF_ "NmAsrMessage" "No";
BA_DEF_DEF_ "DiagState" "No";
BA_DEF_DEF_ "DiagConnection" 0;
BA_DEF_DEF_ "VFrameFormat" "StandardCAN_FD";
BA_DEF_DEF_ "CANFD_BRS" "No";
BA_DEF_DEF_ "GenSigStartValue" 0;
BA_DEF_DEF_ "GenSigInactiveValue" 0;
BA_DEF_DEF_ "GenSigSendType" "NoSigSendType";
BA_DEF_DEF_ "SystemSignalLongSymbol" "";
BA_DEF_DEF_ "GenSigTimeoutTime_AGSM" 2500;
BA_DEF_DEF_ "GenSigTimeoutTime_BCM" 2500;
BA_DEF_DEF_ "GenSigTimeoutTime_BSM" 2500;
BA_DEF_DEF_ "GenSigTimeoutTime_CADM" 2500;
BA_DEF_DEF_ "GenSigTimeoutTime_DMSM" 2500;
BA_DEF_DEF_ "GenSigTimeoutTime_DTCM" 2500;
BA_DEF_DEF_ "GenSigTimeoutTime_ECM" 2500;
BA_DEF_DEF_ "GenSigTimeoutTime_EVCU2" 2500;
BA_DEF_DEF_ "GenSigTimeoutTime_GNMM" 2500;
BA_DEF_DEF_ "GenSigTimeoutTime_HCP" 2500;
BA_DEF_DEF_ "GenSigTimeoutTime_IPC" 2500;
BA_DEF_DEF_ "GenSigTimeoutTime_RFHM" 2500;
BA_DEF_DEF_ "GenSigTimeoutTime_SGW" 2500;
BA_DEF_DEF_ "GenSigTimeoutTime_TCM" 2500;
BA_ "Type" BO_ 1443 3;
BA_ "GenMsgSendType" BO_ 1443 0;
BA_ "GenMsgNrOfRepetition" BO_ 1443 2;
BA_ "GenMsgILSupport" BO_ 1443 1;
BA_ "GenMsgCycleTimeFast" BO_ 1443 20;
BA_ "GenMsgCycleTime" BO_ 1443 1000;
BA_ "GenMsgDelayTime" BO_ 1443 20;
BA_ "CANFD_BRS" BO_ 1443 1;
BA_ "Type" BO_ 1474 3;
BA_ "GenMsgSendType" BO_ 1474 0;
BA_ "GenMsgNrOfRepetition" BO_ 1474 2;
BA_ "GenMsgILSupport" BO_ 1474 1;
BA_ "GenMsgCycleTimeFast" BO_ 1474 20;
BA_ "GenMsgCycleTime" BO_ 1474 1000;
BA_ "GenMsgDelayTime" BO_ 1474 20;
BA_ "CANFD_BRS" BO_ 1474 1;
BA_ "Type" BO_ 753 1;
BA_ "GenMsgSendType" BO_ 753 0;
BA_ "GenMsgILSupport" BO_ 753 1;
BA_ "GenMsgCycleTime" BO_ 753 50;
BA_ "CANFD_BRS" BO_ 753 1;
BA_ "Type" BO_ 125 8;
BA_ "GenMsgNrOfRepetition" BO_ 125 2;
BA_ "GenMsgILSupport" BO_ 125 1;
BA_ "GenMsgCycleTimeFast" BO_ 125 20;
BA_ "GenMsgDelayTime" BO_ 125 20;
BA_ "CANFD_BRS" BO_ 125 1;
BA_ "Type" BO_ 2654486550 8;
BA_ "NmMessage" BO_ 2654486550 1;
BA_ "NmAsrMessage" BO_ 2654486550 1;
BA_ "VFrameFormat" BO_ 2654486550 15;
BA_ "CANFD_BRS" BO_ 2654486550 1;
BA_ "Type" BO_ 2654486528 8;
BA_ "NmMessage" BO_ 2654486528 1;
BA_ "NmAsrMessage" BO_ 2654486528 1;
BA_ "VFrameFormat" BO_ 2654486528 15;
BA_ "CANFD_BRS" BO_ 2654486528 1;
BA_ "Type" BO_ 2654486534 8;
BA_ "NmMessage" BO_ 2654486534 1;
BA_ "NmAsrMessage" BO_ 2654486534 1;
BA_ "VFrameFormat" BO_ 2654486534 15;
BA_ "CANFD_BRS" BO_ 2654486534 1;
BA_ "Type" BO_ 2654486669 8;
BA_ "NmMessage" BO_ 2654486669 1;
BA_ "NmAsrMessage" BO_ 2654486669 1;
BA_ "VFrameFormat" BO_ 2654486669 15;
BA_ "CANFD_BRS" BO_ 2654486669 1;
BA_ "Type" BO_ 2654486595 8;
BA_ "NmMessage" BO_ 2654486595 1;
BA_ "NmAsrMessage" BO_ 2654486595 1;
BA_ "VFrameFormat" BO_ 2654486595 15;
BA_ "CANFD_BRS" BO_ 2654486595 1;
BA_ "Type" BO_ 2654486529 8;
BA_ "NmMessage" BO_ 2654486529 1;
BA_ "NmAsrMessage" BO_ 2654486529 1;
BA_ "VFrameFormat" BO_ 2654486529 15;
BA_ "CANFD_BRS" BO_ 2654486529 1;
BA_ "Type" BO_ 2654486592 8;
BA_ "NmMessage" BO_ 2654486592 1;
BA_ "NmAsrMessage" BO_ 2654486592 1;
BA_ "VFrameFormat" BO_ 2654486592 15;
BA_ "CANFD_BRS" BO_ 2654486592 1;
BA_ "GenSigSendType" SG_ 1443 Act_Lane_Mgt 3;
BA_ "GenSigTimeoutTime_AGSM" SG_ 1443 Act_Lane_Mgt 0;
BA_ "GenSigTimeoutTime_BSM" SG_ 1443 Act_Lane_Mgt 0;
BA_ "GenSigTimeoutTime_DMSM" SG_ 1443 Act_Lane_Mgt 0;
BA_ "GenSigTimeoutTime_DTCM" SG_ 1443 Act_Lane_Mgt 0;
BA_ "GenSigTimeoutTime_ECM" SG_ 1443 Act_Lane_Mgt 0;
BA_ "GenSigTimeoutTime_EVCU2" SG_ 1443 Act_Lane_Mgt 0;
BA_ "GenSigTimeoutTime_GNMM" SG_ 1443 Act_Lane_Mgt 0;
BA_ "GenSigTimeoutTime_HCP" SG_ 1443 Act_Lane_Mgt 0;
BA_ "GenSigTimeoutTime_IPC" SG_ 1443 Act_Lane_Mgt 0;
BA_ "GenSigTimeoutTime_RFHM" SG_ 1443 Act_Lane_Mgt 0;
BA_ "GenSigTimeoutTime_TCM" SG_ 1443 Act_Lane_Mgt 0;
BA_ "GenSigSendType" SG_ 1443 Act_Lane_Mgt_Strength 3;
BA_ "GenSigTimeoutTime_AGSM" SG_ 1443 Act_Lane_Mgt_Strength 0;
BA_ "GenSigTimeoutTime_BSM" SG_ 1443 Act_Lane_Mgt_Strength 0;
BA_ "GenSigTimeoutTime_DMSM" SG_ 1443 Act_Lane_Mgt_Strength 0;
BA_ "GenSigTimeoutTime_DTCM" SG_ 1443 Act_Lane_Mgt_Strength 0;
BA_ "GenSigTimeoutTime_ECM" SG_ 1443 Act_Lane_Mgt_Strength 0;
BA_ "GenSigTimeoutTime_EVCU2" SG_ 1443 Act_Lane_Mgt_Strength 0;
BA_ "GenSigTimeoutTime_GNMM" SG_ 1443 Act_Lane_Mgt_Strength 0;
BA_ "GenSigTimeoutTime_HCP" SG_ 1443 Act_Lane_Mgt_Strength 0;
BA_ "GenSigTimeoutTime_IPC" SG_ 1443 Act_Lane_Mgt_Strength 0;
BA_ "GenSigTimeoutTime_RFHM" SG_ 1443 Act_Lane_Mgt_Strength 0;
BA_ "GenSigTimeoutTime_TCM" SG_ 1443 Act_Lane_Mgt_Strength 0;
BA_ "GenSigSendType" SG_ 1443 Active_Park_Mode 3;
BA_ "GenSigTimeoutTime_AGSM" SG_ 1443 Active_Park_Mode 0;
BA_ "GenSigTimeoutTime_CADM" SG_ 1443 Active_Park_Mode 0;
BA_ "GenSigTimeoutTime_DMSM" SG_ 1443 Active_Park_Mode 0;
BA_ "GenSigTimeoutTime_DTCM" SG_ 1443 Active_Park_Mode 0;
BA_ "GenSigTimeoutTime_ECM" SG_ 1443 Active_Park_Mode 0;
BA_ "GenSigTimeoutTime_EVCU2" SG_ 1443 Active_Park_Mode 0;
BA_ "GenSigTimeoutTime_GNMM" SG_ 1443 Active_Park_Mode 0;
BA_ "GenSigTimeoutTime_HCP" SG_ 1443 Active_Park_Mode 0;
BA_ "GenSigTimeoutTime_IPC" SG_ 1443 Active_Park_Mode 0;
BA_ "GenSigTimeoutTime_RFHM" SG_ 1443 Active_Park_Mode 0;
BA_ "GenSigTimeoutTime_TCM" SG_ 1443 Active_Park_Mode 0;
BA_ "GenSigSendType" SG_ 1443 Active_Park_Prox_Chime 3;
BA_ "GenSigTimeoutTime_AGSM" SG_ 1443 Active_Park_Prox_Chime 0;
BA_ "GenSigTimeoutTime_BSM" SG_ 1443 Active_Park_Prox_Chime 0;
BA_ "GenSigTimeoutTime_CADM" SG_ 1443 Active_Park_Prox_Chime 0;
BA_ "GenSigTimeoutTime_DMSM" SG_ 1443 Active_Park_Prox_Chime 0;
BA_ "GenSigTimeoutTime_DTCM" SG_ 1443 Active_Park_Prox_Chime 0;
BA_ "GenSigTimeoutTime_ECM" SG_ 1443 Active_Park_Prox_Chime 0;
BA_ "GenSigTimeoutTime_EVCU2" SG_ 1443 Active_Park_Prox_Chime 0;
BA_ "GenSigTimeoutTime_GNMM" SG_ 1443 Active_Park_Prox_Chime 0;
BA_ "GenSigTimeoutTime_HCP" SG_ 1443 Active_Park_Prox_Chime 0;
BA_ "GenSigTimeoutTime_IPC" SG_ 1443 Active_Park_Prox_Chime 0;
BA_ "GenSigTimeoutTime_RFHM" SG_ 1443 Active_Park_Prox_Chime 0;
BA_ "GenSigTimeoutTime_TCM" SG_ 1443 Active_Park_Prox_Chime 0;
BA_ "GenSigStartValue" SG_ 1443 AmbientLightingLevel 4;
BA_ "GenSigSendType" SG_ 1443 AmbientLightingLevel 3;
BA_ "GenSigTimeoutTime_AGSM" SG_ 1443 AmbientLightingLevel 0;
BA_ "GenSigTimeoutTime_BCM" SG_ 1443 AmbientLightingLevel 0;
BA_ "GenSigTimeoutTime_BSM" SG_ 1443 AmbientLightingLevel 0;
BA_ "GenSigTimeoutTime_CADM" SG_ 1443 AmbientLightingLevel 0;
BA_ "GenSigTimeoutTime_DMSM" SG_ 1443 AmbientLightingLevel 0;
BA_ "GenSigTimeoutTime_DTCM" SG_ 1443 AmbientLightingLevel 0;
BA_ "GenSigTimeoutTime_ECM" SG_ 1443 AmbientLightingLevel 0;
BA_ "GenSigTimeoutTime_EVCU2" SG_ 1443 AmbientLightingLevel 0;
BA_ "GenSigTimeoutTime_GNMM" SG_ 1443 AmbientLightingLevel 0;
BA_ "GenSigTimeoutTime_HCP" SG_ 1443 AmbientLightingLevel 0;
BA_ "GenSigTimeoutTime_IPC" SG_ 1443 AmbientLightingLevel 0;
BA_ "GenSigTimeoutTime_RFHM" SG_ 1443 AmbientLightingLevel 0;
BA_ "GenSigTimeoutTime_TCM" SG_ 1443 AmbientLightingLevel 0;
BA_ "GenSigSendType" SG_ 1443 Auto_Fold_Mirr 3;
BA_ "GenSigTimeoutTime_AGSM" SG_ 1443 Auto_Fold_Mirr 0;
BA_ "GenSigTimeoutTime_BSM" SG_ 1443 Auto_Fold_Mirr 0;
BA_ "GenSigTimeoutTime_CADM" SG_ 1443 Auto_Fold_Mirr 0;
BA_ "GenSigTimeoutTime_DMSM" SG_ 1443 Auto_Fold_Mirr 0;
BA_ "GenSigTimeoutTime_DTCM" SG_ 1443 Auto_Fold_Mirr 0;
BA_ "GenSigTimeoutTime_ECM" SG_ 1443 Auto_Fold_Mirr 0;
BA_ "GenSigTimeoutTime_EVCU2" SG_ 1443 Auto_Fold_Mirr 0;
BA_ "GenSigTimeoutTime_GNMM" SG_ 1443 Auto_Fold_Mirr 0;
BA_ "GenSigTimeoutTime_HCP" SG_ 1443 Auto_Fold_Mirr 0;
BA_ "GenSigTimeoutTime_IPC" SG_ 1443 Auto_Fold_Mirr 0;
BA_ "GenSigTimeoutTime_RFHM" SG_ 1443 Auto_Fold_Mirr 0;
BA_ "GenSigTimeoutTime_TCM" SG_ 1443 Auto_Fold_Mirr 0;
BA_ "GenSigStartValue" SG_ 1443 AutoHighBeamEnable 1;
BA_ "GenSigSendType" SG_ 1443 AutoHighBeamEnable 3;
BA_ "GenSigTimeoutTime_AGSM" SG_ 1443 AutoHighBeamEnable 0;
BA_ "GenSigTimeoutTime_BSM" SG_ 1443 AutoHighBeamEnable 0;
BA_ "GenSigTimeoutTime_CADM" SG_ 1443 AutoHighBeamEnable 0;
BA_ "GenSigTimeoutTime_DMSM" SG_ 1443 AutoHighBeamEnable 0;
BA_ "GenSigTimeoutTime_DTCM" SG_ 1443 AutoHighBeamEnable 0;
BA_ "GenSigTimeoutTime_ECM" SG_ 1443 AutoHighBeamEnable 0;
BA_ "GenSigTimeoutTime_EVCU2" SG_ 1443 AutoHighBeamEnable 0;
BA_ "GenSigTimeoutTime_GNMM" SG_ 1443 AutoHighBeamEnable 0;
BA_ "GenSigTimeoutTime_HCP" SG_ 1443 AutoHighBeamEnable 0;
BA_ "GenSigTimeoutTime_IPC" SG_ 1443 AutoHighBeamEnable 0;
BA_ "GenSigTimeoutTime_RFHM" SG_ 1443 AutoHighBeamEnable 0;
BA_ "GenSigTimeoutTime_TCM" SG_ 1443 AutoHighBeamEnable 0;
BA_ "GenSigSendType" SG_ 1443 AutoParkBrake 3;
BA_ "GenSigTimeoutTime_AGSM" SG_ 1443 AutoParkBrake 0;
BA_ "GenSigTimeoutTime_CADM" SG_ 1443 AutoParkBrake 0;
BA_ "GenSigTimeoutTime_DMSM" SG_ 1443 AutoParkBrake 0;
BA_ "GenSigTimeoutTime_DTCM" SG_ 1443 AutoParkBrake 0;
BA_ "GenSigTimeoutTime_ECM" SG_ 1443 AutoParkBrake 0;
BA_ "GenSigTimeoutTime_EVCU2" SG_ 1443 AutoParkBrake 0;
BA_ "GenSigTimeoutTime_GNMM" SG_ 1443 AutoParkBrake 0;
BA_ "GenSigTimeoutTime_HCP" SG_ 1443 AutoParkBrake 0;
BA_ "GenSigTimeoutTime_IPC" SG_ 1443 AutoParkBrake 0;
BA_ "GenSigTimeoutTime_RFHM" SG_ 1443 AutoParkBrake 0;
BA_ "GenSigTimeoutTime_TCM" SG_ 1443 AutoParkBrake 0;
BA_ "GenSigStartValue" SG_ 1443 AutoUnlockDoorExit 1;
BA_ "GenSigSendType" SG_ 1443 AutoUnlockDoorExit 3;
BA_ "GenSigTimeoutTime_AGSM" SG_ 1443 AutoUnlockDoorExit 0;
BA_ "GenSigTimeoutTime_BSM" SG_ 1443 AutoUnlockDoorExit 0;
BA_ "GenSigTimeoutTime_CADM" SG_ 1443 AutoUnlockDoorExit 0;
BA_ "GenSigTimeoutTime_DMSM" SG_ 1443 AutoUnlockDoorExit 0;
BA_ "GenSigTimeoutTime_DTCM" SG_ 1443 AutoUnlockDoorExit 0;
BA_ "GenSigTimeoutTime_ECM" SG_ 1443 AutoUnlockDoorExit 0;
BA_ "GenSigTimeoutTime_EVCU2" SG_ 1443 AutoUnlockDoorExit 0;
BA_ "GenSigTimeoutTime_GNMM" SG_ 1443 AutoUnlockDoorExit 0;
BA_ "GenSigTimeoutTime_HCP" SG_ 1443 AutoUnlockDoorExit 0;
BA_ "GenSigTimeoutTime_IPC" SG_ 1443 AutoUnlockDoorExit 0;
BA_ "GenSigTimeoutTime_RFHM" SG_ 1443 AutoUnlockDoorExit 0;
BA_ "GenSigTimeoutTime_TCM" SG_ 1443 AutoUnlockDoorExit 0;
BA_ "GenSigSendType" SG_ 1443 Backup_Cam_Delay 3;
BA_ "GenSigTimeoutTime_AGSM" SG_ 1443 Backup_Cam_Delay 0;
BA_ "GenSigTimeoutTime_BSM" SG_ 1443 Backup_Cam_Delay 0;
BA_ "GenSigTimeoutTime_CADM" SG_ 1443 Backup_Cam_Delay 0;
BA_ "GenSigTimeoutTime_DMSM" SG_ 1443 Backup_Cam_Delay 0;
BA_ "GenSigTimeoutTime_DTCM" SG_ 1443 Backup_Cam_Delay 0;
BA_ "GenSigTimeoutTime_ECM" SG_ 1443 Backup_Cam_Delay 0;
BA_ "GenSigTimeoutTime_EVCU2" SG_ 1443 Backup_Cam_Delay 0;
BA_ "GenSigTimeoutTime_GNMM" SG_ 1443 Backup_Cam_Delay 0;
BA_ "GenSigTimeoutTime_HCP" SG_ 1443 Backup_Cam_Delay 0;
BA_ "GenSigTimeoutTime_IPC" SG_ 1443 Backup_Cam_Delay 0;
BA_ "GenSigTimeoutTime_RFHM" SG_ 1443 Backup_Cam_Delay 0;
BA_ "GenSigTimeoutTime_TCM" SG_ 1443 Backup_Cam_Delay 0;
BA_ "GenSigStartValue" SG_ 1443 BSDEnable 2;
BA_ "GenSigSendType" SG_ 1443 BSDEnable 3;
BA_ "GenSigTimeoutTime_AGSM" SG_ 1443 BSDEnable 0;
BA_ "GenSigTimeoutTime_BSM" SG_ 1443 BSDEnable 0;
BA_ "GenSigTimeoutTime_DMSM" SG_ 1443 BSDEnable 0;
BA_ "GenSigTimeoutTime_DTCM" SG_ 1443 BSDEnable 0;
BA_ "GenSigTimeoutTime_ECM" SG_ 1443 BSDEnable 0;
BA_ "GenSigTimeoutTime_EVCU2" SG_ 1443 BSDEnable 0;
BA_ "GenSigTimeoutTime_GNMM" SG_ 1443 BSDEnable 0;
BA_ "GenSigTimeoutTime_HCP" SG_ 1443 BSDEnable 0;
BA_ "GenSigTimeoutTime_IPC" SG_ 1443 BSDEnable 0;
BA_ "GenSigTimeoutTime_RFHM" SG_ 1443 BSDEnable 0;
BA_ "GenSigTimeoutTime_TCM" SG_ 1443 BSDEnable 0;
BA_ "GenSigSendType" SG_ 1443 Consum_Unit 3;
BA_ "GenSigTimeoutTime_AGSM" SG_ 1443 Consum_Unit 0;
BA_ "GenSigTimeoutTime_BSM" SG_ 1443 Consum_Unit 0;
BA_ "GenSigTimeoutTime_CADM" SG_ 1443 Consum_Unit 0;
BA_ "GenSigTimeoutTime_DMSM" SG_ 1443 Consum_Unit 0;
BA_ "GenSigTimeoutTime_DTCM" SG_ 1443 Consum_Unit 0;
BA_ "GenSigTimeoutTime_ECM" SG_ 1443 Consum_Unit 0;
BA_ "GenSigTimeoutTime_EVCU2" SG_ 1443 Consum_Unit 0;
BA_ "GenSigTimeoutTime_GNMM" SG_ 1443 Consum_Unit 0;
BA_ "GenSigTimeoutTime_HCP" SG_ 1443 Consum_Unit 0;
BA_ "GenSigTimeoutTime_IPC" SG_ 1443 Consum_Unit 0;
BA_ "GenSigTimeoutTime_RFHM" SG_ 1443 Consum_Unit 0;
BA_ "GenSigTimeoutTime_TCM" SG_ 1443 Consum_Unit 0;
BA_ "GenSigSendType" SG_ 1443 CorneringEnable 3;
BA_ "GenSigTimeoutTime_AGSM" SG_ 1443 CorneringEnable 0;
BA_ "GenSigTimeoutTime_BSM" SG_ 1443 CorneringEnable 0;
BA_ "GenSigTimeoutTime_CADM" SG_ 1443 CorneringEnable 0;
BA_ "GenSigTimeoutTime_DMSM" SG_ 1443 CorneringEnable 0;
BA_ "GenSigTimeoutTime_DTCM" SG_ 1443 CorneringEnable 0;
BA_ "GenSigTimeoutTime_ECM" SG_ 1443 CorneringEnable 0;
BA_ "GenSigTimeoutTime_EVCU2" SG_ 1443 CorneringEnable 0;
BA_ "GenSigTimeoutTime_GNMM" SG_ 1443 CorneringEnable 0;
BA_ "GenSigTimeoutTime_HCP" SG_ 1443 CorneringEnable 0;
BA_ "GenSigTimeoutTime_IPC" SG_ 1443 CorneringEnable 0;
BA_ "GenSigTimeoutTime_RFHM" SG_ 1443 CorneringEnable 0;
BA_ "GenSigTimeoutTime_TCM" SG_ 1443 CorneringEnable 0;
BA_ "GenSigTimeoutTime_AGSM" SG_ 1443 CRC_IPCVS1 0;
BA_ "GenSigTimeoutTime_BCM" SG_ 1443 CRC_IPCVS1 0;
BA_ "GenSigTimeoutTime_BSM" SG_ 1443 CRC_IPCVS1 0;
BA_ "GenSigTimeoutTime_DMSM" SG_ 1443 CRC_IPCVS1 0;
BA_ "GenSigTimeoutTime_DTCM" SG_ 1443 CRC_IPCVS1 0;
BA_ "GenSigTimeoutTime_ECM" SG_ 1443 CRC_IPCVS1 0;
BA_ "GenSigTimeoutTime_EVCU2" SG_ 1443 CRC_IPCVS1 0;
BA_ "GenSigTimeoutTime_GNMM" SG_ 1443 CRC_IPCVS1 0;
BA_ "GenSigTimeoutTime_HCP" SG_ 1443 CRC_IPCVS1 0;
BA_ "GenSigTimeoutTime_IPC" SG_ 1443 CRC_IPCVS1 0;
BA_ "GenSigTimeoutTime_RFHM" SG_ 1443 CRC_IPCVS1 0;
BA_ "GenSigTimeoutTime_SGW" SG_ 1443 CRC_IPCVS1 0;
BA_ "GenSigTimeoutTime_TCM" SG_ 1443 CRC_IPCVS1 0;
BA_ "GenSigSendType" SG_ 1443 Dist_Unit 3;
BA_ "GenSigTimeoutTime_AGSM" SG_ 1443 Dist_Unit 0;
BA_ "GenSigTimeoutTime_BSM" SG_ 1443 Dist_Unit 0;
BA_ "GenSigTimeoutTime_CADM" SG_ 1443 Dist_Unit 0;
BA_ "GenSigTimeoutTime_DMSM" SG_ 1443 Dist_Unit 0;
BA_ "GenSigTimeoutTime_DTCM" SG_ 1443 Dist_Unit 0;
BA_ "GenSigTimeoutTime_EVCU2" SG_ 1443 Dist_Unit 0;
BA_ "GenSigTimeoutTime_GNMM" SG_ 1443 Dist_Unit 0;
BA_ "GenSigTimeoutTime_HCP" SG_ 1443 Dist_Unit 0;
BA_ "GenSigTimeoutTime_IPC" SG_ 1443 Dist_Unit 0;
BA_ "GenSigTimeoutTime_RFHM" SG_ 1443 Dist_Unit 0;
BA_ "GenSigTimeoutTime_TCM" SG_ 1443 Dist_Unit 0;
BA_ "GenSigSendType" SG_ 1443 DRLEnable 3;
BA_ "GenSigTimeoutTime_AGSM" SG_ 1443 DRLEnable 0;
BA_ "GenSigTimeoutTime_BSM" SG_ 1443 DRLEnable 0;
BA_ "GenSigTimeoutTime_CADM" SG_ 1443 DRLEnable 0;
BA_ "GenSigTimeoutTime_DMSM" SG_ 1443 DRLEnable 0;
BA_ "GenSigTimeoutTime_DTCM" SG_ 1443 DRLEnable 0;
BA_ "GenSigTimeoutTime_ECM" SG_ 1443 DRLEnable 0;
BA_ "GenSigTimeoutTime_EVCU2" SG_ 1443 DRLEnable 0;
BA_ "GenSigTimeoutTime_GNMM" SG_ 1443 DRLEnable 0;
BA_ "GenSigTimeoutTime_HCP" SG_ 1443 DRLEnable 0;
BA_ "GenSigTimeoutTime_IPC" SG_ 1443 DRLEnable 0;
BA_ "GenSigTimeoutTime_RFHM" SG_ 1443 DRLEnable 0;
BA_ "GenSigTimeoutTime_TCM" SG_ 1443 DRLEnable 0;
BA_ "GenSigSendType" SG_ 1443 Drowsy_Driver_Alert 3;
BA_ "GenSigTimeoutTime_AGSM" SG_ 1443 Drowsy_Driver_Alert 0;
BA_ "GenSigTimeoutTime_BSM" SG_ 1443 Drowsy_Driver_Alert 0;
BA_ "GenSigTimeoutTime_DMSM" SG_ 1443 Drowsy_Driver_Alert 0;
BA_ "GenSigTimeoutTime_DTCM" SG_ 1443 Drowsy_Driver_Alert 0;
BA_ "GenSigTimeoutTime_ECM" SG_ 1443 Drowsy_Driver_Alert 0;
BA_ "GenSigTimeoutTime_EVCU2" SG_ 1443 Drowsy_Driver_Alert 0;
BA_ "GenSigTimeoutTime_GNMM" SG_ 1443 Drowsy_Driver_Alert 0;
BA_ "GenSigTimeoutTime_HCP" SG_ 1443 Drowsy_Driver_Alert 0;
BA_ "GenSigTimeoutTime_IPC" SG_ 1443 Drowsy_Driver_Alert 0;
BA_ "GenSigTimeoutTime_RFHM" SG_ 1443 Drowsy_Driver_Alert 0;
BA_ "GenSigTimeoutTime_TCM" SG_ 1443 Drowsy_Driver_Alert 0;
BA_ "GenSigStartValue" SG_ 1443 DynamicGrid 1;
BA_ "GenSigSendType" SG_ 1443 DynamicGrid 1;
BA_ "GenSigTimeoutTime_AGSM" SG_ 1443 DynamicGrid 0;
BA_ "GenSigTimeoutTime_BSM" SG_ 1443 DynamicGrid 0;
BA_ "GenSigTimeoutTime_CADM" SG_ 1443 DynamicGrid 0;
BA_ "GenSigTimeoutTime_DMSM" SG_ 1443 DynamicGrid 0;
BA_ "GenSigTimeoutTime_DTCM" SG_ 1443 DynamicGrid 0;
BA_ "GenSigTimeoutTime_ECM" SG_ 1443 DynamicGrid 0;
BA_ "GenSigTimeoutTime_EVCU2" SG_ 1443 DynamicGrid 0;
BA_ "GenSigTimeoutTime_GNMM" SG_ 1443 DynamicGrid 0;
BA_ "GenSigTimeoutTime_HCP" SG_ 1443 DynamicGrid 0;
BA_ "GenSigTimeoutTime_IPC" SG_ 1443 DynamicGrid 0;
BA_ "GenSigTimeoutTime_RFHM" SG_ 1443 DynamicGrid 0;
BA_ "GenSigTimeoutTime_TCM" SG_ 1443 DynamicGrid 0;
BA_ "GenSigSendType" SG_ 1443 Easy_Exit_D 3;
BA_ "GenSigTimeoutTime_AGSM" SG_ 1443 Easy_Exit_D 0;
BA_ "GenSigTimeoutTime_BSM" SG_ 1443 Easy_Exit_D 0;
BA_ "GenSigTimeoutTime_CADM" SG_ 1443 Easy_Exit_D 0;
BA_ "GenSigTimeoutTime_DMSM" SG_ 1443 Easy_Exit_D 0;
BA_ "GenSigTimeoutTime_DTCM" SG_ 1443 Easy_Exit_D 0;
BA_ "GenSigTimeoutTime_ECM" SG_ 1443 Easy_Exit_D 0;
BA_ "GenSigTimeoutTime_EVCU2" SG_ 1443 Easy_Exit_D 0;
BA_ "GenSigTimeoutTime_GNMM" SG_ 1443 Easy_Exit_D 0;
BA_ "GenSigTimeoutTime_HCP" SG_ 1443 Easy_Exit_D 0;
BA_ "GenSigTimeoutTime_IPC" SG_ 1443 Easy_Exit_D 0;
BA_ "GenSigTimeoutTime_RFHM" SG_ 1443 Easy_Exit_D 0;
BA_ "GenSigTimeoutTime_TCM" SG_ 1443 Easy_Exit_D 0;
BA_ "GenSigSendType" SG_ 1443 Eng_Off_Pwr_Delay 3;
BA_ "GenSigTimeoutTime_AGSM" SG_ 1443 Eng_Off_Pwr_Delay 0;
BA_ "GenSigTimeoutTime_BSM" SG_ 1443 Eng_Off_Pwr_Delay 0;
BA_ "GenSigTimeoutTime_CADM" SG_ 1443 Eng_Off_Pwr_Delay 0;
BA_ "GenSigTimeoutTime_DMSM" SG_ 1443 Eng_Off_Pwr_Delay 0;
BA_ "GenSigTimeoutTime_DTCM" SG_ 1443 Eng_Off_Pwr_Delay 0;
BA_ "GenSigTimeoutTime_ECM" SG_ 1443 Eng_Off_Pwr_Delay 0;
BA_ "GenSigTimeoutTime_EVCU2" SG_ 1443 Eng_Off_Pwr_Delay 0;
BA_ "GenSigTimeoutTime_GNMM" SG_ 1443 Eng_Off_Pwr_Delay 0;
BA_ "GenSigTimeoutTime_HCP" SG_ 1443 Eng_Off_Pwr_Delay 0;
BA_ "GenSigTimeoutTime_IPC" SG_ 1443 Eng_Off_Pwr_Delay 0;
BA_ "GenSigTimeoutTime_RFHM" SG_ 1443 Eng_Off_Pwr_Delay 0;
BA_ "GenSigTimeoutTime_TCM" SG_ 1443 Eng_Off_Pwr_Delay 0;
BA_ "GenSigSendType" SG_ 1443 EPB_MaintenanceMode 3;
BA_ "GenSigTimeoutTime_AGSM" SG_ 1443 EPB_MaintenanceMode 0;
BA_ "GenSigTimeoutTime_BCM" SG_ 1443 EPB_MaintenanceMode 0;
BA_ "GenSigTimeoutTime_BSM" SG_ 1443 EPB_MaintenanceMode 0;
BA_ "GenSigTimeoutTime_CADM" SG_ 1443 EPB_MaintenanceMode 0;
BA_ "GenSigTimeoutTime_DMSM" SG_ 1443 EPB_MaintenanceMode 0;
BA_ "GenSigTimeoutTime_DTCM" SG_ 1443 EPB_MaintenanceMode 0;
BA_ "GenSigTimeoutTime_ECM" SG_ 1443 EPB_MaintenanceMode 0;
BA_ "GenSigTimeoutTime_EVCU2" SG_ 1443 EPB_MaintenanceMode 0;
BA_ "GenSigTimeoutTime_GNMM" SG_ 1443 EPB_MaintenanceMode 0;
BA_ "GenSigTimeoutTime_HCP" SG_ 1443 EPB_MaintenanceMode 0;
BA_ "GenSigTimeoutTime_IPC" SG_ 1443 EPB_MaintenanceMode 0;
BA_ "GenSigTimeoutTime_RFHM" SG_ 1443 EPB_MaintenanceMode 0;
BA_ "GenSigTimeoutTime_TCM" SG_ 1443 EPB_MaintenanceMode 0;
BA_ "GenSigStartValue" SG_ 1443 FlashLightWLock 1;
BA_ "GenSigSendType" SG_ 1443 FlashLightWLock 3;
BA_ "GenSigTimeoutTime_AGSM" SG_ 1443 FlashLightWLock 0;
BA_ "GenSigTimeoutTime_BSM" SG_ 1443 FlashLightWLock 0;
BA_ "GenSigTimeoutTime_CADM" SG_ 1443 FlashLightWLock 0;
BA_ "GenSigTimeoutTime_DMSM" SG_ 1443 FlashLightWLock 0;
BA_ "GenSigTimeoutTime_DTCM" SG_ 1443 FlashLightWLock 0;
BA_ "GenSigTimeoutTime_ECM" SG_ 1443 FlashLightWLock 0;
BA_ "GenSigTimeoutTime_EVCU2" SG_ 1443 FlashLightWLock 0;
BA_ "GenSigTimeoutTime_GNMM" SG_ 1443 FlashLightWLock 0;
BA_ "GenSigTimeoutTime_HCP" SG_ 1443 FlashLightWLock 0;
BA_ "GenSigTimeoutTime_IPC" SG_ 1443 FlashLightWLock 0;
BA_ "GenSigTimeoutTime_RFHM" SG_ 1443 FlashLightWLock 0;
BA_ "GenSigTimeoutTime_TCM" SG_ 1443 FlashLightWLock 0;
BA_ "GenSigSendType" SG_ 1443 FOA_AppAlert_Disable_UserReq 3;
BA_ "GenSigTimeoutTime_AGSM" SG_ 1443 FOA_AppAlert_Disable_UserReq 0;
BA_ "GenSigTimeoutTime_BSM" SG_ 1443 FOA_AppAlert_Disable_UserReq 0;
BA_ "GenSigTimeoutTime_CADM" SG_ 1443 FOA_AppAlert_Disable_UserReq 0;
BA_ "GenSigTimeoutTime_DMSM" SG_ 1443 FOA_AppAlert_Disable_UserReq 0;
BA_ "GenSigTimeoutTime_DTCM" SG_ 1443 FOA_AppAlert_Disable_UserReq 0;
BA_ "GenSigTimeoutTime_ECM" SG_ 1443 FOA_AppAlert_Disable_UserReq 0;
BA_ "GenSigTimeoutTime_EVCU2" SG_ 1443 FOA_AppAlert_Disable_UserReq 0;
BA_ "GenSigTimeoutTime_GNMM" SG_ 1443 FOA_AppAlert_Disable_UserReq 0;
BA_ "GenSigTimeoutTime_HCP" SG_ 1443 FOA_AppAlert_Disable_UserReq 0;
BA_ "GenSigTimeoutTime_IPC" SG_ 1443 FOA_AppAlert_Disable_UserReq 0;
BA_ "GenSigTimeoutTime_RFHM" SG_ 1443 FOA_AppAlert_Disable_UserReq 0;
BA_ "GenSigTimeoutTime_SGW" SG_ 1443 FOA_AppAlert_Disable_UserReq 0;
BA_ "GenSigTimeoutTime_TCM" SG_ 1443 FOA_AppAlert_Disable_UserReq 0;
BA_ "GenSigStartValue" SG_ 1443 FSFCWPlusActivationMode 1;
BA_ "GenSigSendType" SG_ 1443 FSFCWPlusActivationMode 3;
BA_ "GenSigTimeoutTime_AGSM" SG_ 1443 FSFCWPlusActivationMode 0;
BA_ "GenSigTimeoutTime_BSM" SG_ 1443 FSFCWPlusActivationMode 0;
BA_ "GenSigTimeoutTime_DMSM" SG_ 1443 FSFCWPlusActivationMode 0;
BA_ "GenSigTimeoutTime_DTCM" SG_ 1443 FSFCWPlusActivationMode 0;
BA_ "GenSigTimeoutTime_ECM" SG_ 1443 FSFCWPlusActivationMode 0;
BA_ "GenSigTimeoutTime_EVCU2" SG_ 1443 FSFCWPlusActivationMode 0;
BA_ "GenSigTimeoutTime_GNMM" SG_ 1443 FSFCWPlusActivationMode 0;
BA_ "GenSigTimeoutTime_HCP" SG_ 1443 FSFCWPlusActivationMode 0;
BA_ "GenSigTimeoutTime_IPC" SG_ 1443 FSFCWPlusActivationMode 0;
BA_ "GenSigTimeoutTime_RFHM" SG_ 1443 FSFCWPlusActivationMode 0;
BA_ "GenSigTimeoutTime_TCM" SG_ 1443 FSFCWPlusActivationMode 0;
BA_ "GenSigStartValue" SG_ 1443 FSFCWPlusSetting 3;
BA_ "GenSigSendType" SG_ 1443 FSFCWPlusSetting 3;
BA_ "GenSigTimeoutTime_AGSM" SG_ 1443 FSFCWPlusSetting 0;
BA_ "GenSigTimeoutTime_BSM" SG_ 1443 FSFCWPlusSetting 0;
BA_ "GenSigTimeoutTime_DMSM" SG_ 1443 FSFCWPlusSetting 0;
BA_ "GenSigTimeoutTime_DTCM" SG_ 1443 FSFCWPlusSetting 0;
BA_ "GenSigTimeoutTime_ECM" SG_ 1443 FSFCWPlusSetting 0;
BA_ "GenSigTimeoutTime_EVCU2" SG_ 1443 FSFCWPlusSetting 0;
BA_ "GenSigTimeoutTime_GNMM" SG_ 1443 FSFCWPlusSetting 0;
BA_ "GenSigTimeoutTime_HCP" SG_ 1443 FSFCWPlusSetting 0;
BA_ "GenSigTimeoutTime_IPC" SG_ 1443 FSFCWPlusSetting 0;
BA_ "GenSigTimeoutTime_RFHM" SG_ 1443 FSFCWPlusSetting 0;
BA_ "GenSigTimeoutTime_TCM" SG_ 1443 FSFCWPlusSetting 0;
BA_ "GenSigSendType" SG_ 1443 Fwrd_Cam_Guidelines 3;
BA_ "GenSigTimeoutTime_AGSM" SG_ 1443 Fwrd_Cam_Guidelines 0;
BA_ "GenSigTimeoutTime_BSM" SG_ 1443 Fwrd_Cam_Guidelines 0;
BA_ "GenSigTimeoutTime_CADM" SG_ 1443 Fwrd_Cam_Guidelines 0;
BA_ "GenSigTimeoutTime_DMSM" SG_ 1443 Fwrd_Cam_Guidelines 0;
BA_ "GenSigTimeoutTime_DTCM" SG_ 1443 Fwrd_Cam_Guidelines 0;
BA_ "GenSigTimeoutTime_ECM" SG_ 1443 Fwrd_Cam_Guidelines 0;
BA_ "GenSigTimeoutTime_EVCU2" SG_ 1443 Fwrd_Cam_Guidelines 0;
BA_ "GenSigTimeoutTime_GNMM" SG_ 1443 Fwrd_Cam_Guidelines 0;
BA_ "GenSigTimeoutTime_HCP" SG_ 1443 Fwrd_Cam_Guidelines 0;
BA_ "GenSigTimeoutTime_IPC" SG_ 1443 Fwrd_Cam_Guidelines 0;
BA_ "GenSigTimeoutTime_RFHM" SG_ 1443 Fwrd_Cam_Guidelines 0;
BA_ "GenSigTimeoutTime_TCM" SG_ 1443 Fwrd_Cam_Guidelines 0;
BA_ "GenSigSendType" SG_ 1443 GreetingLightsEnable 3;
BA_ "GenSigTimeoutTime_AGSM" SG_ 1443 GreetingLightsEnable 0;
BA_ "GenSigTimeoutTime_BSM" SG_ 1443 GreetingLightsEnable 0;
BA_ "GenSigTimeoutTime_CADM" SG_ 1443 GreetingLightsEnable 0;
BA_ "GenSigTimeoutTime_DMSM" SG_ 1443 GreetingLightsEnable 0;
BA_ "GenSigTimeoutTime_DTCM" SG_ 1443 GreetingLightsEnable 0;
BA_ "GenSigTimeoutTime_ECM" SG_ 1443 GreetingLightsEnable 0;
BA_ "GenSigTimeoutTime_EVCU2" SG_ 1443 GreetingLightsEnable 0;
BA_ "GenSigTimeoutTime_GNMM" SG_ 1443 GreetingLightsEnable 0;
BA_ "GenSigTimeoutTime_HCP" SG_ 1443 GreetingLightsEnable 0;
BA_ "GenSigTimeoutTime_IPC" SG_ 1443 GreetingLightsEnable 0;
BA_ "GenSigTimeoutTime_RFHM" SG_ 1443 GreetingLightsEnable 0;
BA_ "GenSigTimeoutTime_TCM" SG_ 1443 GreetingLightsEnable 0;
BA_ "GenSigSendType" SG_ 1443 HeadlightsOffDelay 3;
BA_ "GenSigTimeoutTime_AGSM" SG_ 1443 HeadlightsOffDelay 0;
BA_ "GenSigTimeoutTime_BSM" SG_ 1443 HeadlightsOffDelay 0;
BA_ "GenSigTimeoutTime_CADM" SG_ 1443 HeadlightsOffDelay 0;
BA_ "GenSigTimeoutTime_DMSM" SG_ 1443 HeadlightsOffDelay 0;
BA_ "GenSigTimeoutTime_DTCM" SG_ 1443 HeadlightsOffDelay 0;
BA_ "GenSigTimeoutTime_ECM" SG_ 1443 HeadlightsOffDelay 0;
BA_ "GenSigTimeoutTime_EVCU2" SG_ 1443 HeadlightsOffDelay 0;
BA_ "GenSigTimeoutTime_GNMM" SG_ 1443 HeadlightsOffDelay 0;
BA_ "GenSigTimeoutTime_HCP" SG_ 1443 HeadlightsOffDelay 0;
BA_ "GenSigTimeoutTime_IPC" SG_ 1443 HeadlightsOffDelay 0;
BA_ "GenSigTimeoutTime_RFHM" SG_ 1443 HeadlightsOffDelay 0;
BA_ "GenSigTimeoutTime_TCM" SG_ 1443 HeadlightsOffDelay 0;
BA_ "GenSigStartValue" SG_ 1443 HeadLightWipers 1;
BA_ "GenSigSendType" SG_ 1443 HeadLightWipers 3;
BA_ "GenSigTimeoutTime_AGSM" SG_ 1443 HeadLightWipers 0;
BA_ "GenSigTimeoutTime_BSM" SG_ 1443 HeadLightWipers 0;
BA_ "GenSigTimeoutTime_CADM" SG_ 1443 HeadLightWipers 0;
BA_ "GenSigTimeoutTime_DMSM" SG_ 1443 HeadLightWipers 0;
BA_ "GenSigTimeoutTime_DTCM" SG_ 1443 HeadLightWipers 0;
BA_ "GenSigTimeoutTime_ECM" SG_ 1443 HeadLightWipers 0;
BA_ "GenSigTimeoutTime_EVCU2" SG_ 1443 HeadLightWipers 0;
BA_ "GenSigTimeoutTime_GNMM" SG_ 1443 HeadLightWipers 0;
BA_ "GenSigTimeoutTime_HCP" SG_ 1443 HeadLightWipers 0;
BA_ "GenSigTimeoutTime_IPC" SG_ 1443 HeadLightWipers 0;
BA_ "GenSigTimeoutTime_RFHM" SG_ 1443 HeadLightWipers 0;
BA_ "GenSigTimeoutTime_TCM" SG_ 1443 HeadLightWipers 0;
BA_ "GenSigSendType" SG_ 1443 Hill_Start_Assist 3;
BA_ "GenSigTimeoutTime_AGSM" SG_ 1443 Hill_Start_Assist 0;
BA_ "GenSigTimeoutTime_CADM" SG_ 1443 Hill_Start_Assist 0;
BA_ "GenSigTimeoutTime_DMSM" SG_ 1443 Hill_Start_Assist 0;
BA_ "GenSigTimeoutTime_DTCM" SG_ 1443 Hill_Start_Assist 0;
BA_ "GenSigTimeoutTime_ECM" SG_ 1443 Hill_Start_Assist 0;
BA_ "GenSigTimeoutTime_EVCU2" SG_ 1443 Hill_Start_Assist 0;
BA_ "GenSigTimeoutTime_GNMM" SG_ 1443 Hill_Start_Assist 0;
BA_ "GenSigTimeoutTime_HCP" SG_ 1443 Hill_Start_Assist 0;
BA_ "GenSigTimeoutTime_IPC" SG_ 1443 Hill_Start_Assist 0;
BA_ "GenSigTimeoutTime_RFHM" SG_ 1443 Hill_Start_Assist 0;
BA_ "GenSigTimeoutTime_TCM" SG_ 1443 Hill_Start_Assist 0;
BA_ "GenSigSendType" SG_ 1443 HourMode 3;
BA_ "GenSigTimeoutTime_AGSM" SG_ 1443 HourMode 0;
BA_ "GenSigTimeoutTime_BSM" SG_ 1443 HourMode 0;
BA_ "GenSigTimeoutTime_CADM" SG_ 1443 HourMode 0;
BA_ "GenSigTimeoutTime_DMSM" SG_ 1443 HourMode 0;
BA_ "GenSigTimeoutTime_DTCM" SG_ 1443 HourMode 0;
BA_ "GenSigTimeoutTime_ECM" SG_ 1443 HourMode 0;
BA_ "GenSigTimeoutTime_EVCU2" SG_ 1443 HourMode 0;
BA_ "GenSigTimeoutTime_GNMM" SG_ 1443 HourMode 0;
BA_ "GenSigTimeoutTime_HCP" SG_ 1443 HourMode 0;
BA_ "GenSigTimeoutTime_IPC" SG_ 1443 HourMode 0;
BA_ "GenSigTimeoutTime_RFHM" SG_ 1443 HourMode 0;
BA_ "GenSigTimeoutTime_TCM" SG_ 1443 HourMode 0;
BA_ "GenSigSendType" SG_ 1443 HP_Unit 3;
BA_ "GenSigTimeoutTime_AGSM" SG_ 1443 HP_Unit 0;
BA_ "GenSigTimeoutTime_BSM" SG_ 1443 HP_Unit 0;
BA_ "GenSigTimeoutTime_CADM" SG_ 1443 HP_Unit 0;
BA_ "GenSigTimeoutTime_DMSM" SG_ 1443 HP_Unit 0;
BA_ "GenSigTimeoutTime_DTCM" SG_ 1443 HP_Unit 0;
BA_ "GenSigTimeoutTime_ECM" SG_ 1443 HP_Unit 0;
BA_ "GenSigTimeoutTime_EVCU2" SG_ 1443 HP_Unit 0;
BA_ "GenSigTimeoutTime_GNMM" SG_ 1443 HP_Unit 0;
BA_ "GenSigTimeoutTime_HCP" SG_ 1443 HP_Unit 0;
BA_ "GenSigTimeoutTime_IPC" SG_ 1443 HP_Unit 0;
BA_ "GenSigTimeoutTime_RFHM" SG_ 1443 HP_Unit 0;
BA_ "GenSigTimeoutTime_TCM" SG_ 1443 HP_Unit 0;
BA_ "GenSigSendType" SG_ 1443 Illuminated_Approach 3;
BA_ "GenSigTimeoutTime_AGSM" SG_ 1443 Illuminated_Approach 0;
BA_ "GenSigTimeoutTime_BSM" SG_ 1443 Illuminated_Approach 0;
BA_ "GenSigTimeoutTime_CADM" SG_ 1443 Illuminated_Approach 0;
BA_ "GenSigTimeoutTime_DMSM" SG_ 1443 Illuminated_Approach 0;
BA_ "GenSigTimeoutTime_DTCM" SG_ 1443 Illuminated_Approach 0;
BA_ "GenSigTimeoutTime_ECM" SG_ 1443 Illuminated_Approach 0;
BA_ "GenSigTimeoutTime_EVCU2" SG_ 1443 Illuminated_Approach 0;
BA_ "GenSigTimeoutTime_GNMM" SG_ 1443 Illuminated_Approach 0;
BA_ "GenSigTimeoutTime_HCP" SG_ 1443 Illuminated_Approach 0;
BA_ "GenSigTimeoutTime_IPC" SG_ 1443 Illuminated_Approach 0;
BA_ "GenSigTimeoutTime_RFHM" SG_ 1443 Illuminated_Approach 0;
BA_ "GenSigTimeoutTime_TCM" SG_ 1443 Illuminated_Approach 0;
BA_ "GenSigSendType" SG_ 1443 IPCProgrammed 3;
BA_ "GenSigTimeoutTime_AGSM" SG_ 1443 IPCProgrammed 0;
BA_ "GenSigTimeoutTime_BSM" SG_ 1443 IPCProgrammed 0;
BA_ "GenSigTimeoutTime_CADM" SG_ 1443 IPCProgrammed 0;
BA_ "GenSigTimeoutTime_DMSM" SG_ 1443 IPCProgrammed 0;
BA_ "GenSigTimeoutTime_DTCM" SG_ 1443 IPCProgrammed 0;
BA_ "GenSigTimeoutTime_ECM" SG_ 1443 IPCProgrammed 0;
BA_ "GenSigTimeoutTime_EVCU2" SG_ 1443 IPCProgrammed 0;
BA_ "GenSigTimeoutTime_GNMM" SG_ 1443 IPCProgrammed 0;
BA_ "GenSigTimeoutTime_HCP" SG_ 1443 IPCProgrammed 0;
BA_ "GenSigTimeoutTime_IPC" SG_ 1443 IPCProgrammed 0;
BA_ "GenSigTimeoutTime_RFHM" SG_ 1443 IPCProgrammed 0;
BA_ "GenSigTimeoutTime_TCM" SG_ 1443 IPCProgrammed 0;
BA_ "GenSigSendType" SG_ 1443 LanguageSelection 3;
BA_ "GenSigTimeoutTime_AGSM" SG_ 1443 LanguageSelection 0;
BA_ "GenSigTimeoutTime_BSM" SG_ 1443 LanguageSelection 0;
BA_ "GenSigTimeoutTime_CADM" SG_ 1443 LanguageSelection 0;
BA_ "GenSigTimeoutTime_DMSM" SG_ 1443 LanguageSelection 0;
BA_ "GenSigTimeoutTime_DTCM" SG_ 1443 LanguageSelection 0;
BA_ "GenSigTimeoutTime_ECM" SG_ 1443 LanguageSelection 0;
BA_ "GenSigTimeoutTime_EVCU2" SG_ 1443 LanguageSelection 0;
BA_ "GenSigTimeoutTime_GNMM" SG_ 1443 LanguageSelection 0;
BA_ "GenSigTimeoutTime_HCP" SG_ 1443 LanguageSelection 0;
BA_ "GenSigTimeoutTime_IPC" SG_ 1443 LanguageSelection 0;
BA_ "GenSigTimeoutTime_RFHM" SG_ 1443 LanguageSelection 0;
BA_ "GenSigTimeoutTime_TCM" SG_ 1443 LanguageSelection 0;
BA_ "GenSigStartValue" SG_ 1443 LDW_Intensity 2;
BA_ "GenSigSendType" SG_ 1443 LDW_Intensity 3;
BA_ "GenSigTimeoutTime_AGSM" SG_ 1443 LDW_Intensity 0;
BA_ "GenSigTimeoutTime_BSM" SG_ 1443 LDW_Intensity 0;
BA_ "GenSigTimeoutTime_DMSM" SG_ 1443 LDW_Intensity 0;
BA_ "GenSigTimeoutTime_DTCM" SG_ 1443 LDW_Intensity 0;
BA_ "GenSigTimeoutTime_ECM" SG_ 1443 LDW_Intensity 0;
BA_ "GenSigTimeoutTime_EVCU2" SG_ 1443 LDW_Intensity 0;
BA_ "GenSigTimeoutTime_GNMM" SG_ 1443 LDW_Intensity 0;
BA_ "GenSigTimeoutTime_HCP" SG_ 1443 LDW_Intensity 0;
BA_ "GenSigTimeoutTime_IPC" SG_ 1443 LDW_Intensity 0;
BA_ "GenSigTimeoutTime_RFHM" SG_ 1443 LDW_Intensity 0;
BA_ "GenSigTimeoutTime_TCM" SG_ 1443 LDW_Intensity 0;
BA_ "GenSigStartValue" SG_ 1443 LDW_Sensibility 2;
BA_ "GenSigSendType" SG_ 1443 LDW_Sensibility 3;
BA_ "GenSigTimeoutTime_AGSM" SG_ 1443 LDW_Sensibility 0;
BA_ "GenSigTimeoutTime_BSM" SG_ 1443 LDW_Sensibility 0;
BA_ "GenSigTimeoutTime_DMSM" SG_ 1443 LDW_Sensibility 0;
BA_ "GenSigTimeoutTime_DTCM" SG_ 1443 LDW_Sensibility 0;
BA_ "GenSigTimeoutTime_ECM" SG_ 1443 LDW_Sensibility 0;
BA_ "GenSigTimeoutTime_EVCU2" SG_ 1443 LDW_Sensibility 0;
BA_ "GenSigTimeoutTime_GNMM" SG_ 1443 LDW_Sensibility 0;
BA_ "GenSigTimeoutTime_HCP" SG_ 1443 LDW_Sensibility 0;
BA_ "GenSigTimeoutTime_IPC" SG_ 1443 LDW_Sensibility 0;
BA_ "GenSigTimeoutTime_RFHM" SG_ 1443 LDW_Sensibility 0;
BA_ "GenSigTimeoutTime_TCM" SG_ 1443 LDW_Sensibility 0;
BA_ "GenSigTimeoutTime_AGSM" SG_ 1443 MessageCounter_IPCVS1 0;
BA_ "GenSigTimeoutTime_BCM" SG_ 1443 MessageCounter_IPCVS1 0;
BA_ "GenSigTimeoutTime_BSM" SG_ 1443 MessageCounter_IPCVS1 0;
BA_ "GenSigTimeoutTime_DMSM" SG_ 1443 MessageCounter_IPCVS1 0;
BA_ "GenSigTimeoutTime_DTCM" SG_ 1443 MessageCounter_IPCVS1 0;
BA_ "GenSigTimeoutTime_ECM" SG_ 1443 MessageCounter_IPCVS1 0;
BA_ "GenSigTimeoutTime_EVCU2" SG_ 1443 MessageCounter_IPCVS1 0;
BA_ "GenSigTimeoutTime_GNMM" SG_ 1443 MessageCounter_IPCVS1 0;
BA_ "GenSigTimeoutTime_HCP" SG_ 1443 MessageCounter_IPCVS1 0;
BA_ "GenSigTimeoutTime_IPC" SG_ 1443 MessageCounter_IPCVS1 0;
BA_ "GenSigTimeoutTime_RFHM" SG_ 1443 MessageCounter_IPCVS1 0;
BA_ "GenSigTimeoutTime_SGW" SG_ 1443 MessageCounter_IPCVS1 0;
BA_ "GenSigTimeoutTime_TCM" SG_ 1443 MessageCounter_IPCVS1 0;
BA_ "GenSigSendType" SG_ 1443 NavRepetition 3;
BA_ "GenSigTimeoutTime_AGSM" SG_ 1443 NavRepetition 0;
BA_ "GenSigTimeoutTime_BSM" SG_ 1443 NavRepetition 0;
BA_ "GenSigTimeoutTime_CADM" SG_ 1443 NavRepetition 0;
BA_ "GenSigTimeoutTime_DMSM" SG_ 1443 NavRepetition 0;
BA_ "GenSigTimeoutTime_DTCM" SG_ 1443 NavRepetition 0;
BA_ "GenSigTimeoutTime_ECM" SG_ 1443 NavRepetition 0;
BA_ "GenSigTimeoutTime_EVCU2" SG_ 1443 NavRepetition 0;
BA_ "GenSigTimeoutTime_GNMM" SG_ 1443 NavRepetition 0;
BA_ "GenSigTimeoutTime_HCP" SG_ 1443 NavRepetition 0;
BA_ "GenSigTimeoutTime_IPC" SG_ 1443 NavRepetition 0;
BA_ "GenSigTimeoutTime_RFHM" SG_ 1443 NavRepetition 0;
BA_ "GenSigTimeoutTime_TCM" SG_ 1443 NavRepetition 0;
BA_ "GenSigSendType" SG_ 1443 New_Spd_Zone_Ind 3;
BA_ "GenSigTimeoutTime_AGSM" SG_ 1443 New_Spd_Zone_Ind 0;
BA_ "GenSigTimeoutTime_BSM" SG_ 1443 New_Spd_Zone_Ind 0;
BA_ "GenSigTimeoutTime_CADM" SG_ 1443 New_Spd_Zone_Ind 0;
BA_ "GenSigTimeoutTime_DMSM" SG_ 1443 New_Spd_Zone_Ind 0;
BA_ "GenSigTimeoutTime_DTCM" SG_ 1443 New_Spd_Zone_Ind 0;
BA_ "GenSigTimeoutTime_ECM" SG_ 1443 New_Spd_Zone_Ind 0;
BA_ "GenSigTimeoutTime_EVCU2" SG_ 1443 New_Spd_Zone_Ind 0;
BA_ "GenSigTimeoutTime_GNMM" SG_ 1443 New_Spd_Zone_Ind 0;
BA_ "GenSigTimeoutTime_HCP" SG_ 1443 New_Spd_Zone_Ind 0;
BA_ "GenSigTimeoutTime_IPC" SG_ 1443 New_Spd_Zone_Ind 0;
BA_ "GenSigTimeoutTime_RFHM" SG_ 1443 New_Spd_Zone_Ind 0;
BA_ "GenSigTimeoutTime_TCM" SG_ 1443 New_Spd_Zone_Ind 0;
BA_ "GenSigSendType" SG_ 1443 Paddle_Shifter 3;
BA_ "GenSigTimeoutTime_AGSM" SG_ 1443 Paddle_Shifter 0;
BA_ "GenSigTimeoutTime_BSM" SG_ 1443 Paddle_Shifter 0;
BA_ "GenSigTimeoutTime_CADM" SG_ 1443 Paddle_Shifter 0;
BA_ "GenSigTimeoutTime_DMSM" SG_ 1443 Paddle_Shifter 0;
BA_ "GenSigTimeoutTime_DTCM" SG_ 1443 Paddle_Shifter 0;
BA_ "GenSigTimeoutTime_ECM" SG_ 1443 Paddle_Shifter 0;
BA_ "GenSigTimeoutTime_EVCU2" SG_ 1443 Paddle_Shifter 0;
BA_ "GenSigTimeoutTime_GNMM" SG_ 1443 Paddle_Shifter 0;
BA_ "GenSigTimeoutTime_HCP" SG_ 1443 Paddle_Shifter 0;
BA_ "GenSigTimeoutTime_IPC" SG_ 1443 Paddle_Shifter 0;
BA_ "GenSigTimeoutTime_RFHM" SG_ 1443 Paddle_Shifter 0;
BA_ "GenSigTimeoutTime_TCM" SG_ 1443 Paddle_Shifter 0;
BA_ "GenSigStartValue" SG_ 1443 PamChimeVolumeFront 1;
BA_ "GenSigSendType" SG_ 1443 PamChimeVolumeFront 3;
BA_ "GenSigTimeoutTime_AGSM" SG_ 1443 PamChimeVolumeFront 0;
BA_ "GenSigTimeoutTime_BSM" SG_ 1443 PamChimeVolumeFront 0;
BA_ "GenSigTimeoutTime_CADM" SG_ 1443 PamChimeVolumeFront 0;
BA_ "GenSigTimeoutTime_DMSM" SG_ 1443 PamChimeVolumeFront 0;
BA_ "GenSigTimeoutTime_DTCM" SG_ 1443 PamChimeVolumeFront 0;
BA_ "GenSigTimeoutTime_ECM" SG_ 1443 PamChimeVolumeFront 0;
BA_ "GenSigTimeoutTime_EVCU2" SG_ 1443 PamChimeVolumeFront 0;
BA_ "GenSigTimeoutTime_GNMM" SG_ 1443 PamChimeVolumeFront 0;
BA_ "GenSigTimeoutTime_HCP" SG_ 1443 PamChimeVolumeFront 0;
BA_ "GenSigTimeoutTime_IPC" SG_ 1443 PamChimeVolumeFront 0;
BA_ "GenSigTimeoutTime_RFHM" SG_ 1443 PamChimeVolumeFront 0;
BA_ "GenSigTimeoutTime_TCM" SG_ 1443 PamChimeVolumeFront 0;
BA_ "GenSigStartValue" SG_ 1443 PamChimeVolumeRear 1;
BA_ "GenSigSendType" SG_ 1443 PamChimeVolumeRear 3;
BA_ "GenSigTimeoutTime_AGSM" SG_ 1443 PamChimeVolumeRear 0;
BA_ "GenSigTimeoutTime_BSM" SG_ 1443 PamChimeVolumeRear 0;
BA_ "GenSigTimeoutTime_CADM" SG_ 1443 PamChimeVolumeRear 0;
BA_ "GenSigTimeoutTime_DMSM" SG_ 1443 PamChimeVolumeRear 0;
BA_ "GenSigTimeoutTime_DTCM" SG_ 1443 PamChimeVolumeRear 0;
BA_ "GenSigTimeoutTime_ECM" SG_ 1443 PamChimeVolumeRear 0;
BA_ "GenSigTimeoutTime_EVCU2" SG_ 1443 PamChimeVolumeRear 0;
BA_ "GenSigTimeoutTime_GNMM" SG_ 1443 PamChimeVolumeRear 0;
BA_ "GenSigTimeoutTime_HCP" SG_ 1443 PamChimeVolumeRear 0;
BA_ "GenSigTimeoutTime_IPC" SG_ 1443 PamChimeVolumeRear 0;
BA_ "GenSigTimeoutTime_RFHM" SG_ 1443 PamChimeVolumeRear 0;
BA_ "GenSigTimeoutTime_TCM" SG_ 1443 PamChimeVolumeRear 0;
BA_ "GenSigSendType" SG_ 1443 PassiveEntry 3;
BA_ "GenSigTimeoutTime_AGSM" SG_ 1443 PassiveEntry 0;
BA_ "GenSigTimeoutTime_BSM" SG_ 1443 PassiveEntry 0;
BA_ "GenSigTimeoutTime_CADM" SG_ 1443 PassiveEntry 0;
BA_ "GenSigTimeoutTime_DMSM" SG_ 1443 PassiveEntry 0;
BA_ "GenSigTimeoutTime_DTCM" SG_ 1443 PassiveEntry 0;
BA_ "GenSigTimeoutTime_ECM" SG_ 1443 PassiveEntry 0;
BA_ "GenSigTimeoutTime_EVCU2" SG_ 1443 PassiveEntry 0;
BA_ "GenSigTimeoutTime_GNMM" SG_ 1443 PassiveEntry 0;
BA_ "GenSigTimeoutTime_HCP" SG_ 1443 PassiveEntry 0;
BA_ "GenSigTimeoutTime_IPC" SG_ 1443 PassiveEntry 0;
BA_ "GenSigTimeoutTime_TCM" SG_ 1443 PassiveEntry 0;
BA_ "GenSigSendType" SG_ 1443 Ped_EM_Brk_Warn_Act 3;
BA_ "GenSigTimeoutTime_AGSM" SG_ 1443 Ped_EM_Brk_Warn_Act 0;
BA_ "GenSigTimeoutTime_BSM" SG_ 1443 Ped_EM_Brk_Warn_Act 0;
BA_ "GenSigTimeoutTime_CADM" SG_ 1443 Ped_EM_Brk_Warn_Act 0;
BA_ "GenSigTimeoutTime_DMSM" SG_ 1443 Ped_EM_Brk_Warn_Act 0;
BA_ "GenSigTimeoutTime_DTCM" SG_ 1443 Ped_EM_Brk_Warn_Act 0;
BA_ "GenSigTimeoutTime_ECM" SG_ 1443 Ped_EM_Brk_Warn_Act 0;
BA_ "GenSigTimeoutTime_EVCU2" SG_ 1443 Ped_EM_Brk_Warn_Act 0;
BA_ "GenSigTimeoutTime_GNMM" SG_ 1443 Ped_EM_Brk_Warn_Act 0;
BA_ "GenSigTimeoutTime_HCP" SG_ 1443 Ped_EM_Brk_Warn_Act 0;
BA_ "GenSigTimeoutTime_IPC" SG_ 1443 Ped_EM_Brk_Warn_Act 0;
BA_ "GenSigTimeoutTime_RFHM" SG_ 1443 Ped_EM_Brk_Warn_Act 0;
BA_ "GenSigTimeoutTime_TCM" SG_ 1443 Ped_EM_Brk_Warn_Act 0;
BA_ "GenSigSendType" SG_ 1443 PhoneRepetition 3;
BA_ "GenSigTimeoutTime_AGSM" SG_ 1443 PhoneRepetition 0;
BA_ "GenSigTimeoutTime_BSM" SG_ 1443 PhoneRepetition 0;
BA_ "GenSigTimeoutTime_CADM" SG_ 1443 PhoneRepetition 0;
BA_ "GenSigTimeoutTime_DMSM" SG_ 1443 PhoneRepetition 0;
BA_ "GenSigTimeoutTime_DTCM" SG_ 1443 PhoneRepetition 0;
BA_ "GenSigTimeoutTime_ECM" SG_ 1443 PhoneRepetition 0;
BA_ "GenSigTimeoutTime_EVCU2" SG_ 1443 PhoneRepetition 0;
BA_ "GenSigTimeoutTime_GNMM" SG_ 1443 PhoneRepetition 0;
BA_ "GenSigTimeoutTime_HCP" SG_ 1443 PhoneRepetition 0;
BA_ "GenSigTimeoutTime_IPC" SG_ 1443 PhoneRepetition 0;
BA_ "GenSigTimeoutTime_RFHM" SG_ 1443 PhoneRepetition 0;
BA_ "GenSigTimeoutTime_TCM" SG_ 1443 PhoneRepetition 0;
BA_ "GenSigStartValue" SG_ 1443 PLGAlert 1;
BA_ "GenSigSendType" SG_ 1443 PLGAlert 3;
BA_ "GenSigTimeoutTime_AGSM" SG_ 1443 PLGAlert 0;
BA_ "GenSigTimeoutTime_BSM" SG_ 1443 PLGAlert 0;
BA_ "GenSigTimeoutTime_CADM" SG_ 1443 PLGAlert 0;
BA_ "GenSigTimeoutTime_DMSM" SG_ 1443 PLGAlert 0;
BA_ "GenSigTimeoutTime_DTCM" SG_ 1443 PLGAlert 0;
BA_ "GenSigTimeoutTime_ECM" SG_ 1443 PLGAlert 0;
BA_ "GenSigTimeoutTime_EVCU2" SG_ 1443 PLGAlert 0;
BA_ "GenSigTimeoutTime_GNMM" SG_ 1443 PLGAlert 0;
BA_ "GenSigTimeoutTime_HCP" SG_ 1443 PLGAlert 0;
BA_ "GenSigTimeoutTime_IPC" SG_ 1443 PLGAlert 0;
BA_ "GenSigTimeoutTime_RFHM" SG_ 1443 PLGAlert 0;
BA_ "GenSigTimeoutTime_TCM" SG_ 1443 PLGAlert 0;
BA_ "GenSigSendType" SG_ 1443 Power_Side_Step 3;
BA_ "GenSigTimeoutTime_AGSM" SG_ 1443 Power_Side_Step 0;
BA_ "GenSigTimeoutTime_BSM" SG_ 1443 Power_Side_Step 0;
BA_ "GenSigTimeoutTime_CADM" SG_ 1443 Power_Side_Step 0;
BA_ "GenSigTimeoutTime_DMSM" SG_ 1443 Power_Side_Step 0;
BA_ "GenSigTimeoutTime_DTCM" SG_ 1443 Power_Side_Step 0;
BA_ "GenSigTimeoutTime_ECM" SG_ 1443 Power_Side_Step 0;
BA_ "GenSigTimeoutTime_EVCU2" SG_ 1443 Power_Side_Step 0;
BA_ "GenSigTimeoutTime_GNMM" SG_ 1443 Power_Side_Step 0;
BA_ "GenSigTimeoutTime_HCP" SG_ 1443 Power_Side_Step 0;
BA_ "GenSigTimeoutTime_IPC" SG_ 1443 Power_Side_Step 0;
BA_ "GenSigTimeoutTime_RFHM" SG_ 1443 Power_Side_Step 0;
BA_ "GenSigTimeoutTime_TCM" SG_ 1443 Power_Side_Step 0;
BA_ "GenSigSendType" SG_ 1443 Proximity_WU 3;
BA_ "GenSigTimeoutTime_AGSM" SG_ 1443 Proximity_WU 0;
BA_ "GenSigTimeoutTime_BSM" SG_ 1443 Proximity_WU 0;
BA_ "GenSigTimeoutTime_CADM" SG_ 1443 Proximity_WU 0;
BA_ "GenSigTimeoutTime_DMSM" SG_ 1443 Proximity_WU 0;
BA_ "GenSigTimeoutTime_DTCM" SG_ 1443 Proximity_WU 0;
BA_ "GenSigTimeoutTime_ECM" SG_ 1443 Proximity_WU 0;
BA_ "GenSigTimeoutTime_EVCU2" SG_ 1443 Proximity_WU 0;
BA_ "GenSigTimeoutTime_GNMM" SG_ 1443 Proximity_WU 0;
BA_ "GenSigTimeoutTime_HCP" SG_ 1443 Proximity_WU 0;
BA_ "GenSigTimeoutTime_IPC" SG_ 1443 Proximity_WU 0;
BA_ "GenSigTimeoutTime_TCM" SG_ 1443 Proximity_WU 0;
BA_ "GenSigStartValue" SG_ 1443 PwrLev 2;
BA_ "GenSigSendType" SG_ 1443 PwrLev 3;
BA_ "GenSigTimeoutTime_AGSM" SG_ 1443 PwrLev 0;
BA_ "GenSigTimeoutTime_BSM" SG_ 1443 PwrLev 0;
BA_ "GenSigTimeoutTime_CADM" SG_ 1443 PwrLev 0;
BA_ "GenSigTimeoutTime_DMSM" SG_ 1443 PwrLev 0;
BA_ "GenSigTimeoutTime_DTCM" SG_ 1443 PwrLev 0;
BA_ "GenSigTimeoutTime_ECM" SG_ 1443 PwrLev 0;
BA_ "GenSigTimeoutTime_GNMM" SG_ 1443 PwrLev 0;
BA_ "GenSigTimeoutTime_HCP" SG_ 1443 PwrLev 0;
BA_ "GenSigTimeoutTime_IPC" SG_ 1443 PwrLev 0;
BA_ "GenSigTimeoutTime_RFHM" SG_ 1443 PwrLev 0;
BA_ "GenSigTimeoutTime_TCM" SG_ 1443 PwrLev 0;
BA_ "GenSigStartValue" SG_ 1443 RainSensorLevel 1;
BA_ "GenSigSendType" SG_ 1443 RainSensorLevel 3;
BA_ "GenSigTimeoutTime_AGSM" SG_ 1443 RainSensorLevel 0;
BA_ "GenSigTimeoutTime_BSM" SG_ 1443 RainSensorLevel 0;
BA_ "GenSigTimeoutTime_CADM" SG_ 1443 RainSensorLevel 0;
BA_ "GenSigTimeoutTime_DMSM" SG_ 1443 RainSensorLevel 0;
BA_ "GenSigTimeoutTime_DTCM" SG_ 1443 RainSensorLevel 0;
BA_ "GenSigTimeoutTime_ECM" SG_ 1443 RainSensorLevel 0;
BA_ "GenSigTimeoutTime_EVCU2" SG_ 1443 RainSensorLevel 0;
BA_ "GenSigTimeoutTime_GNMM" SG_ 1443 RainSensorLevel 0;
BA_ "GenSigTimeoutTime_HCP" SG_ 1443 RainSensorLevel 0;
BA_ "GenSigTimeoutTime_IPC" SG_ 1443 RainSensorLevel 0;
BA_ "GenSigTimeoutTime_RFHM" SG_ 1443 RainSensorLevel 0;
BA_ "GenSigTimeoutTime_TCM" SG_ 1443 RainSensorLevel 0;
BA_ "GenSigSendType" SG_ 1443 Rdy_To_Drive 3;
BA_ "GenSigTimeoutTime_AGSM" SG_ 1443 Rdy_To_Drive 0;
BA_ "GenSigTimeoutTime_BCM" SG_ 1443 Rdy_To_Drive 0;
BA_ "GenSigTimeoutTime_BSM" SG_ 1443 Rdy_To_Drive 0;
BA_ "GenSigTimeoutTime_CADM" SG_ 1443 Rdy_To_Drive 0;
BA_ "GenSigTimeoutTime_DMSM" SG_ 1443 Rdy_To_Drive 0;
BA_ "GenSigTimeoutTime_DTCM" SG_ 1443 Rdy_To_Drive 0;
BA_ "GenSigTimeoutTime_ECM" SG_ 1443 Rdy_To_Drive 0;
BA_ "GenSigTimeoutTime_EVCU2" SG_ 1443 Rdy_To_Drive 0;
BA_ "GenSigTimeoutTime_GNMM" SG_ 1443 Rdy_To_Drive 0;
BA_ "GenSigTimeoutTime_HCP" SG_ 1443 Rdy_To_Drive 0;
BA_ "GenSigTimeoutTime_IPC" SG_ 1443 Rdy_To_Drive 0;
BA_ "GenSigTimeoutTime_RFHM" SG_ 1443 Rdy_To_Drive 0;
BA_ "GenSigTimeoutTime_TCM" SG_ 1443 Rdy_To_Drive 0;
BA_ "GenSigSendType" SG_ 1443 Rear_Brk_Asst 3;
BA_ "GenSigTimeoutTime_AGSM" SG_ 1443 Rear_Brk_Asst 0;
BA_ "GenSigTimeoutTime_BSM" SG_ 1443 Rear_Brk_Asst 0;
BA_ "GenSigTimeoutTime_CADM" SG_ 1443 Rear_Brk_Asst 0;
BA_ "GenSigTimeoutTime_DMSM" SG_ 1443 Rear_Brk_Asst 0;
BA_ "GenSigTimeoutTime_DTCM" SG_ 1443 Rear_Brk_Asst 0;
BA_ "GenSigTimeoutTime_ECM" SG_ 1443 Rear_Brk_Asst 0;
BA_ "GenSigTimeoutTime_EVCU2" SG_ 1443 Rear_Brk_Asst 0;
BA_ "GenSigTimeoutTime_GNMM" SG_ 1443 Rear_Brk_Asst 0;
BA_ "GenSigTimeoutTime_HCP" SG_ 1443 Rear_Brk_Asst 0;
BA_ "GenSigTimeoutTime_IPC" SG_ 1443 Rear_Brk_Asst 0;
BA_ "GenSigTimeoutTime_RFHM" SG_ 1443 Rear_Brk_Asst 0;
BA_ "GenSigTimeoutTime_TCM" SG_ 1443 Rear_Brk_Asst 0;
BA_ "GenSigStartValue" SG_ 1443 RemoteDoorUnlock 1;
BA_ "GenSigSendType" SG_ 1443 RemoteDoorUnlock 3;
BA_ "GenSigTimeoutTime_AGSM" SG_ 1443 RemoteDoorUnlock 0;
BA_ "GenSigTimeoutTime_BSM" SG_ 1443 RemoteDoorUnlock 0;
BA_ "GenSigTimeoutTime_CADM" SG_ 1443 RemoteDoorUnlock 0;
BA_ "GenSigTimeoutTime_DMSM" SG_ 1443 RemoteDoorUnlock 0;
BA_ "GenSigTimeoutTime_DTCM" SG_ 1443 RemoteDoorUnlock 0;
BA_ "GenSigTimeoutTime_ECM" SG_ 1443 RemoteDoorUnlock 0;
BA_ "GenSigTimeoutTime_EVCU2" SG_ 1443 RemoteDoorUnlock 0;
BA_ "GenSigTimeoutTime_GNMM" SG_ 1443 RemoteDoorUnlock 0;
BA_ "GenSigTimeoutTime_HCP" SG_ 1443 RemoteDoorUnlock 0;
BA_ "GenSigTimeoutTime_IPC" SG_ 1443 RemoteDoorUnlock 0;
BA_ "GenSigTimeoutTime_RFHM" SG_ 1443 RemoteDoorUnlock 0;
BA_ "GenSigTimeoutTime_TCM" SG_ 1443 RemoteDoorUnlock 0;
BA_ "GenSigStartValue" SG_ 1443 RemStNrmlStEnbl 2;
BA_ "GenSigSendType" SG_ 1443 RemStNrmlStEnbl 3;
BA_ "GenSigTimeoutTime_AGSM" SG_ 1443 RemStNrmlStEnbl 0;
BA_ "GenSigTimeoutTime_BSM" SG_ 1443 RemStNrmlStEnbl 0;
BA_ "GenSigTimeoutTime_CADM" SG_ 1443 RemStNrmlStEnbl 0;
BA_ "GenSigTimeoutTime_DMSM" SG_ 1443 RemStNrmlStEnbl 0;
BA_ "GenSigTimeoutTime_DTCM" SG_ 1443 RemStNrmlStEnbl 0;
BA_ "GenSigTimeoutTime_ECM" SG_ 1443 RemStNrmlStEnbl 0;
BA_ "GenSigTimeoutTime_EVCU2" SG_ 1443 RemStNrmlStEnbl 0;
BA_ "GenSigTimeoutTime_GNMM" SG_ 1443 RemStNrmlStEnbl 0;
BA_ "GenSigTimeoutTime_HCP" SG_ 1443 RemStNrmlStEnbl 0;
BA_ "GenSigTimeoutTime_IPC" SG_ 1443 RemStNrmlStEnbl 0;
BA_ "GenSigTimeoutTime_RFHM" SG_ 1443 RemStNrmlStEnbl 0;
BA_ "GenSigTimeoutTime_TCM" SG_ 1443 RemStNrmlStEnbl 0;
BA_ "GenSigStartValue" SG_ 1443 RKEMemoryLinkEnable 1;
BA_ "GenSigSendType" SG_ 1443 RKEMemoryLinkEnable 3;
BA_ "GenSigTimeoutTime_AGSM" SG_ 1443 RKEMemoryLinkEnable 0;
BA_ "GenSigTimeoutTime_BSM" SG_ 1443 RKEMemoryLinkEnable 0;
BA_ "GenSigTimeoutTime_CADM" SG_ 1443 RKEMemoryLinkEnable 0;
BA_ "GenSigTimeoutTime_DMSM" SG_ 1443 RKEMemoryLinkEnable 0;
BA_ "GenSigTimeoutTime_DTCM" SG_ 1443 RKEMemoryLinkEnable 0;
BA_ "GenSigTimeoutTime_ECM" SG_ 1443 RKEMemoryLinkEnable 0;
BA_ "GenSigTimeoutTime_EVCU2" SG_ 1443 RKEMemoryLinkEnable 0;
BA_ "GenSigTimeoutTime_GNMM" SG_ 1443 RKEMemoryLinkEnable 0;
BA_ "GenSigTimeoutTime_HCP" SG_ 1443 RKEMemoryLinkEnable 0;
BA_ "GenSigTimeoutTime_IPC" SG_ 1443 RKEMemoryLinkEnable 0;
BA_ "GenSigTimeoutTime_RFHM" SG_ 1443 RKEMemoryLinkEnable 0;
BA_ "GenSigTimeoutTime_TCM" SG_ 1443 RKEMemoryLinkEnable 0;
BA_ "GenSigSendType" SG_ 1443 SOC_Max_Lev 3;
BA_ "GenSigTimeoutTime_AGSM" SG_ 1443 SOC_Max_Lev 0;
BA_ "GenSigTimeoutTime_BCM" SG_ 1443 SOC_Max_Lev 0;
BA_ "GenSigTimeoutTime_BSM" SG_ 1443 SOC_Max_Lev 0;
BA_ "GenSigTimeoutTime_CADM" SG_ 1443 SOC_Max_Lev 0;
BA_ "GenSigTimeoutTime_DMSM" SG_ 1443 SOC_Max_Lev 0;
BA_ "GenSigTimeoutTime_DTCM" SG_ 1443 SOC_Max_Lev 0;
BA_ "GenSigTimeoutTime_ECM" SG_ 1443 SOC_Max_Lev 0;
BA_ "GenSigTimeoutTime_GNMM" SG_ 1443 SOC_Max_Lev 0;
BA_ "GenSigTimeoutTime_HCP" SG_ 1443 SOC_Max_Lev 0;
BA_ "GenSigTimeoutTime_IPC" SG_ 1443 SOC_Max_Lev 0;
BA_ "GenSigTimeoutTime_RFHM" SG_ 1443 SOC_Max_Lev 0;
BA_ "GenSigTimeoutTime_SGW" SG_ 1443 SOC_Max_Lev 0;
BA_ "GenSigTimeoutTime_TCM" SG_ 1443 SOC_Max_Lev 0;
BA_ "GenSigStartValue" SG_ 1443 SoundHornLock 1;
BA_ "GenSigSendType" SG_ 1443 SoundHornLock 3;
BA_ "GenSigTimeoutTime_AGSM" SG_ 1443 SoundHornLock 0;
BA_ "GenSigTimeoutTime_BSM" SG_ 1443 SoundHornLock 0;
BA_ "GenSigTimeoutTime_CADM" SG_ 1443 SoundHornLock 0;
BA_ "GenSigTimeoutTime_DMSM" SG_ 1443 SoundHornLock 0;
BA_ "GenSigTimeoutTime_DTCM" SG_ 1443 SoundHornLock 0;
BA_ "GenSigTimeoutTime_ECM" SG_ 1443 SoundHornLock 0;
BA_ "GenSigTimeoutTime_EVCU2" SG_ 1443 SoundHornLock 0;
BA_ "GenSigTimeoutTime_GNMM" SG_ 1443 SoundHornLock 0;
BA_ "GenSigTimeoutTime_HCP" SG_ 1443 SoundHornLock 0;
BA_ "GenSigTimeoutTime_IPC" SG_ 1443 SoundHornLock 0;
BA_ "GenSigTimeoutTime_RFHM" SG_ 1443 SoundHornLock 0;
BA_ "GenSigTimeoutTime_TCM" SG_ 1443 SoundHornLock 0;
BA_ "GenSigSendType" SG_ 1443 SoundHornRemoteStart 3;
BA_ "GenSigTimeoutTime_AGSM" SG_ 1443 SoundHornRemoteStart 0;
BA_ "GenSigTimeoutTime_BSM" SG_ 1443 SoundHornRemoteStart 0;
BA_ "GenSigTimeoutTime_CADM" SG_ 1443 SoundHornRemoteStart 0;
BA_ "GenSigTimeoutTime_DMSM" SG_ 1443 SoundHornRemoteStart 0;
BA_ "GenSigTimeoutTime_DTCM" SG_ 1443 SoundHornRemoteStart 0;
BA_ "GenSigTimeoutTime_ECM" SG_ 1443 SoundHornRemoteStart 0;
BA_ "GenSigTimeoutTime_EVCU2" SG_ 1443 SoundHornRemoteStart 0;
BA_ "GenSigTimeoutTime_GNMM" SG_ 1443 SoundHornRemoteStart 0;
BA_ "GenSigTimeoutTime_HCP" SG_ 1443 SoundHornRemoteStart 0;
BA_ "GenSigTimeoutTime_IPC" SG_ 1443 SoundHornRemoteStart 0;
BA_ "GenSigTimeoutTime_RFHM" SG_ 1443 SoundHornRemoteStart 0;
BA_ "GenSigTimeoutTime_TCM" SG_ 1443 SoundHornRemoteStart 0;
BA_ "GenSigSendType" SG_ 1443 Spaak 3;
BA_ "GenSigTimeoutTime_AGSM" SG_ 1443 Spaak 0;
BA_ "GenSigTimeoutTime_BSM" SG_ 1443 Spaak 0;
BA_ "GenSigTimeoutTime_CADM" SG_ 1443 Spaak 0;
BA_ "GenSigTimeoutTime_DMSM" SG_ 1443 Spaak 0;
BA_ "GenSigTimeoutTime_DTCM" SG_ 1443 Spaak 0;
BA_ "GenSigTimeoutTime_ECM" SG_ 1443 Spaak 0;
BA_ "GenSigTimeoutTime_EVCU2" SG_ 1443 Spaak 0;
BA_ "GenSigTimeoutTime_GNMM" SG_ 1443 Spaak 0;
BA_ "GenSigTimeoutTime_HCP" SG_ 1443 Spaak 0;
BA_ "GenSigTimeoutTime_IPC" SG_ 1443 Spaak 0;
BA_ "GenSigTimeoutTime_TCM" SG_ 1443 Spaak 0;
BA_ "GenSigSendType" SG_ 1443 Speed_Unit 3;
BA_ "GenSigTimeoutTime_AGSM" SG_ 1443 Speed_Unit 0;
BA_ "GenSigTimeoutTime_BSM" SG_ 1443 Speed_Unit 0;
BA_ "GenSigTimeoutTime_DMSM" SG_ 1443 Speed_Unit 0;
BA_ "GenSigTimeoutTime_DTCM" SG_ 1443 Speed_Unit 0;
BA_ "GenSigTimeoutTime_ECM" SG_ 1443 Speed_Unit 0;
BA_ "GenSigTimeoutTime_EVCU2" SG_ 1443 Speed_Unit 0;
BA_ "GenSigTimeoutTime_GNMM" SG_ 1443 Speed_Unit 0;
BA_ "GenSigTimeoutTime_HCP" SG_ 1443 Speed_Unit 0;
BA_ "GenSigTimeoutTime_IPC" SG_ 1443 Speed_Unit 0;
BA_ "GenSigTimeoutTime_RFHM" SG_ 1443 Speed_Unit 0;
BA_ "GenSigTimeoutTime_TCM" SG_ 1443 Speed_Unit 0;
BA_ "GenSigSendType" SG_ 1443 SpeedLockDoorEnable 3;
BA_ "GenSigTimeoutTime_AGSM" SG_ 1443 SpeedLockDoorEnable 0;
BA_ "GenSigTimeoutTime_BSM" SG_ 1443 SpeedLockDoorEnable 0;
BA_ "GenSigTimeoutTime_CADM" SG_ 1443 SpeedLockDoorEnable 0;
BA_ "GenSigTimeoutTime_DMSM" SG_ 1443 SpeedLockDoorEnable 0;
BA_ "GenSigTimeoutTime_DTCM" SG_ 1443 SpeedLockDoorEnable 0;
BA_ "GenSigTimeoutTime_ECM" SG_ 1443 SpeedLockDoorEnable 0;
BA_ "GenSigTimeoutTime_EVCU2" SG_ 1443 SpeedLockDoorEnable 0;
BA_ "GenSigTimeoutTime_GNMM" SG_ 1443 SpeedLockDoorEnable 0;
BA_ "GenSigTimeoutTime_HCP" SG_ 1443 SpeedLockDoorEnable 0;
BA_ "GenSigTimeoutTime_IPC" SG_ 1443 SpeedLockDoorEnable 0;
BA_ "GenSigTimeoutTime_RFHM" SG_ 1443 SpeedLockDoorEnable 0;
BA_ "GenSigTimeoutTime_TCM" SG_ 1443 SpeedLockDoorEnable 0;
BA_ "GenSigSendType" SG_ 1443 StaticGrid 1;
BA_ "GenSigTimeoutTime_AGSM" SG_ 1443 StaticGrid 0;
BA_ "GenSigTimeoutTime_BSM" SG_ 1443 StaticGrid 0;
BA_ "GenSigTimeoutTime_CADM" SG_ 1443 StaticGrid 0;
BA_ "GenSigTimeoutTime_DMSM" SG_ 1443 StaticGrid 0;
BA_ "GenSigTimeoutTime_DTCM" SG_ 1443 StaticGrid 0;
BA_ "GenSigTimeoutTime_ECM" SG_ 1443 StaticGrid 0;
BA_ "GenSigTimeoutTime_EVCU2" SG_ 1443 StaticGrid 0;
BA_ "GenSigTimeoutTime_GNMM" SG_ 1443 StaticGrid 0;
BA_ "GenSigTimeoutTime_HCP" SG_ 1443 StaticGrid 0;
BA_ "GenSigTimeoutTime_IPC" SG_ 1443 StaticGrid 0;
BA_ "GenSigTimeoutTime_RFHM" SG_ 1443 StaticGrid 0;
BA_ "GenSigTimeoutTime_TCM" SG_ 1443 StaticGrid 0;
BA_ "GenSigSendType" SG_ 1443 Susp_Auto_Ent_Ext 3;
BA_ "GenSigTimeoutTime_AGSM" SG_ 1443 Susp_Auto_Ent_Ext 0;
BA_ "GenSigTimeoutTime_BSM" SG_ 1443 Susp_Auto_Ent_Ext 0;
BA_ "GenSigTimeoutTime_CADM" SG_ 1443 Susp_Auto_Ent_Ext 0;
BA_ "GenSigTimeoutTime_DMSM" SG_ 1443 Susp_Auto_Ent_Ext 0;
BA_ "GenSigTimeoutTime_DTCM" SG_ 1443 Susp_Auto_Ent_Ext 0;
BA_ "GenSigTimeoutTime_ECM" SG_ 1443 Susp_Auto_Ent_Ext 0;
BA_ "GenSigTimeoutTime_EVCU2" SG_ 1443 Susp_Auto_Ent_Ext 0;
BA_ "GenSigTimeoutTime_GNMM" SG_ 1443 Susp_Auto_Ent_Ext 0;
BA_ "GenSigTimeoutTime_HCP" SG_ 1443 Susp_Auto_Ent_Ext 0;
BA_ "GenSigTimeoutTime_IPC" SG_ 1443 Susp_Auto_Ent_Ext 0;
BA_ "GenSigTimeoutTime_RFHM" SG_ 1443 Susp_Auto_Ent_Ext 0;
BA_ "GenSigTimeoutTime_TCM" SG_ 1443 Susp_Auto_Ent_Ext 0;
BA_ "GenSigSendType" SG_ 1443 Susp_Aux_Mode 3;
BA_ "GenSigTimeoutTime_AGSM" SG_ 1443 Susp_Aux_Mode 0;
BA_ "GenSigTimeoutTime_BSM" SG_ 1443 Susp_Aux_Mode 0;
BA_ "GenSigTimeoutTime_CADM" SG_ 1443 Susp_Aux_Mode 0;
BA_ "GenSigTimeoutTime_DMSM" SG_ 1443 Susp_Aux_Mode 0;
BA_ "GenSigTimeoutTime_DTCM" SG_ 1443 Susp_Aux_Mode 0;
BA_ "GenSigTimeoutTime_ECM" SG_ 1443 Susp_Aux_Mode 0;
BA_ "GenSigTimeoutTime_EVCU2" SG_ 1443 Susp_Aux_Mode 0;
BA_ "GenSigTimeoutTime_GNMM" SG_ 1443 Susp_Aux_Mode 0;
BA_ "GenSigTimeoutTime_HCP" SG_ 1443 Susp_Aux_Mode 0;
BA_ "GenSigTimeoutTime_IPC" SG_ 1443 Susp_Aux_Mode 0;
BA_ "GenSigTimeoutTime_RFHM" SG_ 1443 Susp_Aux_Mode 0;
BA_ "GenSigTimeoutTime_TCM" SG_ 1443 Susp_Aux_Mode 0;
BA_ "GenSigSendType" SG_ 1443 Susp_Disp_Message 3;
BA_ "GenSigTimeoutTime_AGSM" SG_ 1443 Susp_Disp_Message 0;
BA_ "GenSigTimeoutTime_BSM" SG_ 1443 Susp_Disp_Message 0;
BA_ "GenSigTimeoutTime_CADM" SG_ 1443 Susp_Disp_Message 0;
BA_ "GenSigTimeoutTime_DMSM" SG_ 1443 Susp_Disp_Message 0;
BA_ "GenSigTimeoutTime_DTCM" SG_ 1443 Susp_Disp_Message 0;
BA_ "GenSigTimeoutTime_ECM" SG_ 1443 Susp_Disp_Message 0;
BA_ "GenSigTimeoutTime_EVCU2" SG_ 1443 Susp_Disp_Message 0;
BA_ "GenSigTimeoutTime_GNMM" SG_ 1443 Susp_Disp_Message 0;
BA_ "GenSigTimeoutTime_HCP" SG_ 1443 Susp_Disp_Message 0;
BA_ "GenSigTimeoutTime_IPC" SG_ 1443 Susp_Disp_Message 0;
BA_ "GenSigTimeoutTime_RFHM" SG_ 1443 Susp_Disp_Message 0;
BA_ "GenSigTimeoutTime_TCM" SG_ 1443 Susp_Disp_Message 0;
BA_ "GenSigSendType" SG_ 1443 Susp_Flsh_Lght_Low 3;
BA_ "GenSigTimeoutTime_AGSM" SG_ 1443 Susp_Flsh_Lght_Low 0;
BA_ "GenSigTimeoutTime_BSM" SG_ 1443 Susp_Flsh_Lght_Low 0;
BA_ "GenSigTimeoutTime_CADM" SG_ 1443 Susp_Flsh_Lght_Low 0;
BA_ "GenSigTimeoutTime_DMSM" SG_ 1443 Susp_Flsh_Lght_Low 0;
BA_ "GenSigTimeoutTime_DTCM" SG_ 1443 Susp_Flsh_Lght_Low 0;
BA_ "GenSigTimeoutTime_ECM" SG_ 1443 Susp_Flsh_Lght_Low 0;
BA_ "GenSigTimeoutTime_EVCU2" SG_ 1443 Susp_Flsh_Lght_Low 0;
BA_ "GenSigTimeoutTime_GNMM" SG_ 1443 Susp_Flsh_Lght_Low 0;
BA_ "GenSigTimeoutTime_HCP" SG_ 1443 Susp_Flsh_Lght_Low 0;
BA_ "GenSigTimeoutTime_IPC" SG_ 1443 Susp_Flsh_Lght_Low 0;
BA_ "GenSigTimeoutTime_RFHM" SG_ 1443 Susp_Flsh_Lght_Low 0;
BA_ "GenSigTimeoutTime_TCM" SG_ 1443 Susp_Flsh_Lght_Low 0;
BA_ "GenSigSendType" SG_ 1443 Susp_Sound_Hrn_Low 3;
BA_ "GenSigTimeoutTime_AGSM" SG_ 1443 Susp_Sound_Hrn_Low 0;
BA_ "GenSigTimeoutTime_BSM" SG_ 1443 Susp_Sound_Hrn_Low 0;
BA_ "GenSigTimeoutTime_CADM" SG_ 1443 Susp_Sound_Hrn_Low 0;
BA_ "GenSigTimeoutTime_DMSM" SG_ 1443 Susp_Sound_Hrn_Low 0;
BA_ "GenSigTimeoutTime_DTCM" SG_ 1443 Susp_Sound_Hrn_Low 0;
BA_ "GenSigTimeoutTime_ECM" SG_ 1443 Susp_Sound_Hrn_Low 0;
BA_ "GenSigTimeoutTime_EVCU2" SG_ 1443 Susp_Sound_Hrn_Low 0;
BA_ "GenSigTimeoutTime_GNMM" SG_ 1443 Susp_Sound_Hrn_Low 0;
BA_ "GenSigTimeoutTime_HCP" SG_ 1443 Susp_Sound_Hrn_Low 0;
BA_ "GenSigTimeoutTime_IPC" SG_ 1443 Susp_Sound_Hrn_Low 0;
BA_ "GenSigTimeoutTime_RFHM" SG_ 1443 Susp_Sound_Hrn_Low 0;
BA_ "GenSigTimeoutTime_TCM" SG_ 1443 Susp_Sound_Hrn_Low 0;
BA_ "GenSigSendType" SG_ 1443 Susp_Tire_Jack 3;
BA_ "GenSigTimeoutTime_AGSM" SG_ 1443 Susp_Tire_Jack 0;
BA_ "GenSigTimeoutTime_BSM" SG_ 1443 Susp_Tire_Jack 0;
BA_ "GenSigTimeoutTime_CADM" SG_ 1443 Susp_Tire_Jack 0;
BA_ "GenSigTimeoutTime_DMSM" SG_ 1443 Susp_Tire_Jack 0;
BA_ "GenSigTimeoutTime_DTCM" SG_ 1443 Susp_Tire_Jack 0;
BA_ "GenSigTimeoutTime_ECM" SG_ 1443 Susp_Tire_Jack 0;
BA_ "GenSigTimeoutTime_EVCU2" SG_ 1443 Susp_Tire_Jack 0;
BA_ "GenSigTimeoutTime_GNMM" SG_ 1443 Susp_Tire_Jack 0;
BA_ "GenSigTimeoutTime_HCP" SG_ 1443 Susp_Tire_Jack 0;
BA_ "GenSigTimeoutTime_IPC" SG_ 1443 Susp_Tire_Jack 0;
BA_ "GenSigTimeoutTime_RFHM" SG_ 1443 Susp_Tire_Jack 0;
BA_ "GenSigTimeoutTime_TCM" SG_ 1443 Susp_Tire_Jack 0;
BA_ "GenSigSendType" SG_ 1443 SVC_Delay 3;
BA_ "GenSigTimeoutTime_AGSM" SG_ 1443 SVC_Delay 0;
BA_ "GenSigTimeoutTime_BSM" SG_ 1443 SVC_Delay 0;
BA_ "GenSigTimeoutTime_CADM" SG_ 1443 SVC_Delay 0;
BA_ "GenSigTimeoutTime_DMSM" SG_ 1443 SVC_Delay 0;
BA_ "GenSigTimeoutTime_DTCM" SG_ 1443 SVC_Delay 0;
BA_ "GenSigTimeoutTime_ECM" SG_ 1443 SVC_Delay 0;
BA_ "GenSigTimeoutTime_EVCU2" SG_ 1443 SVC_Delay 0;
BA_ "GenSigTimeoutTime_GNMM" SG_ 1443 SVC_Delay 0;
BA_ "GenSigTimeoutTime_HCP" SG_ 1443 SVC_Delay 0;
BA_ "GenSigTimeoutTime_IPC" SG_ 1443 SVC_Delay 0;
BA_ "GenSigTimeoutTime_RFHM" SG_ 1443 SVC_Delay 0;
BA_ "GenSigTimeoutTime_TCM" SG_ 1443 SVC_Delay 0;
BA_ "GenSigSendType" SG_ 1443 SVC_Guidelines 3;
BA_ "GenSigTimeoutTime_AGSM" SG_ 1443 SVC_Guidelines 0;
BA_ "GenSigTimeoutTime_BSM" SG_ 1443 SVC_Guidelines 0;
BA_ "GenSigTimeoutTime_CADM" SG_ 1443 SVC_Guidelines 0;
BA_ "GenSigTimeoutTime_DMSM" SG_ 1443 SVC_Guidelines 0;
BA_ "GenSigTimeoutTime_DTCM" SG_ 1443 SVC_Guidelines 0;
BA_ "GenSigTimeoutTime_ECM" SG_ 1443 SVC_Guidelines 0;
BA_ "GenSigTimeoutTime_EVCU2" SG_ 1443 SVC_Guidelines 0;
BA_ "GenSigTimeoutTime_GNMM" SG_ 1443 SVC_Guidelines 0;
BA_ "GenSigTimeoutTime_HCP" SG_ 1443 SVC_Guidelines 0;
BA_ "GenSigTimeoutTime_IPC" SG_ 1443 SVC_Guidelines 0;
BA_ "GenSigTimeoutTime_RFHM" SG_ 1443 SVC_Guidelines 0;
BA_ "GenSigTimeoutTime_TCM" SG_ 1443 SVC_Guidelines 0;
BA_ "GenSigSendType" SG_ 1443 TelematicSetupACK 3;
BA_ "GenSigTimeoutTime_AGSM" SG_ 1443 TelematicSetupACK 0;
BA_ "GenSigTimeoutTime_BSM" SG_ 1443 TelematicSetupACK 0;
BA_ "GenSigTimeoutTime_CADM" SG_ 1443 TelematicSetupACK 0;
BA_ "GenSigTimeoutTime_DMSM" SG_ 1443 TelematicSetupACK 0;
BA_ "GenSigTimeoutTime_DTCM" SG_ 1443 TelematicSetupACK 0;
BA_ "GenSigTimeoutTime_ECM" SG_ 1443 TelematicSetupACK 0;
BA_ "GenSigTimeoutTime_EVCU2" SG_ 1443 TelematicSetupACK 0;
BA_ "GenSigTimeoutTime_GNMM" SG_ 1443 TelematicSetupACK 0;
BA_ "GenSigTimeoutTime_HCP" SG_ 1443 TelematicSetupACK 0;
BA_ "GenSigTimeoutTime_IPC" SG_ 1443 TelematicSetupACK 0;
BA_ "GenSigTimeoutTime_RFHM" SG_ 1443 TelematicSetupACK 0;
BA_ "GenSigTimeoutTime_TCM" SG_ 1443 TelematicSetupACK 0;
BA_ "GenSigSendType" SG_ 1443 Temp_Unit 3;
BA_ "GenSigTimeoutTime_AGSM" SG_ 1443 Temp_Unit 0;
BA_ "GenSigTimeoutTime_BSM" SG_ 1443 Temp_Unit 0;
BA_ "GenSigTimeoutTime_CADM" SG_ 1443 Temp_Unit 0;
BA_ "GenSigTimeoutTime_DMSM" SG_ 1443 Temp_Unit 0;
BA_ "GenSigTimeoutTime_DTCM" SG_ 1443 Temp_Unit 0;
BA_ "GenSigTimeoutTime_ECM" SG_ 1443 Temp_Unit 0;
BA_ "GenSigTimeoutTime_EVCU2" SG_ 1443 Temp_Unit 0;
BA_ "GenSigTimeoutTime_GNMM" SG_ 1443 Temp_Unit 0;
BA_ "GenSigTimeoutTime_HCP" SG_ 1443 Temp_Unit 0;
BA_ "GenSigTimeoutTime_IPC" SG_ 1443 Temp_Unit 0;
BA_ "GenSigTimeoutTime_RFHM" SG_ 1443 Temp_Unit 0;
BA_ "GenSigTimeoutTime_TCM" SG_ 1443 Temp_Unit 0;
BA_ "GenSigSendType" SG_ 1443 Tilt_Mirr_Rev 3;
BA_ "GenSigTimeoutTime_AGSM" SG_ 1443 Tilt_Mirr_Rev 0;
BA_ "GenSigTimeoutTime_BSM" SG_ 1443 Tilt_Mirr_Rev 0;
BA_ "GenSigTimeoutTime_CADM" SG_ 1443 Tilt_Mirr_Rev 0;
BA_ "GenSigTimeoutTime_DMSM" SG_ 1443 Tilt_Mirr_Rev 0;
BA_ "GenSigTimeoutTime_DTCM" SG_ 1443 Tilt_Mirr_Rev 0;
BA_ "GenSigTimeoutTime_ECM" SG_ 1443 Tilt_Mirr_Rev 0;
BA_ "GenSigTimeoutTime_EVCU2" SG_ 1443 Tilt_Mirr_Rev 0;
BA_ "GenSigTimeoutTime_GNMM" SG_ 1443 Tilt_Mirr_Rev 0;
BA_ "GenSigTimeoutTime_HCP" SG_ 1443 Tilt_Mirr_Rev 0;
BA_ "GenSigTimeoutTime_IPC" SG_ 1443 Tilt_Mirr_Rev 0;
BA_ "GenSigTimeoutTime_RFHM" SG_ 1443 Tilt_Mirr_Rev 0;
BA_ "GenSigTimeoutTime_TCM" SG_ 1443 Tilt_Mirr_Rev 0;
BA_ "GenSigSendType" SG_ 1443 Tire_Fill_Alert 3;
BA_ "GenSigTimeoutTime_AGSM" SG_ 1443 Tire_Fill_Alert 0;
BA_ "GenSigTimeoutTime_BSM" SG_ 1443 Tire_Fill_Alert 0;
BA_ "GenSigTimeoutTime_CADM" SG_ 1443 Tire_Fill_Alert 0;
BA_ "GenSigTimeoutTime_DMSM" SG_ 1443 Tire_Fill_Alert 0;
BA_ "GenSigTimeoutTime_DTCM" SG_ 1443 Tire_Fill_Alert 0;
BA_ "GenSigTimeoutTime_ECM" SG_ 1443 Tire_Fill_Alert 0;
BA_ "GenSigTimeoutTime_EVCU2" SG_ 1443 Tire_Fill_Alert 0;
BA_ "GenSigTimeoutTime_GNMM" SG_ 1443 Tire_Fill_Alert 0;
BA_ "GenSigTimeoutTime_HCP" SG_ 1443 Tire_Fill_Alert 0;
BA_ "GenSigTimeoutTime_IPC" SG_ 1443 Tire_Fill_Alert 0;
BA_ "GenSigTimeoutTime_TCM" SG_ 1443 Tire_Fill_Alert 0;
BA_ "GenSigSendType" SG_ 1443 Torque_Unit 3;
BA_ "GenSigTimeoutTime_AGSM" SG_ 1443 Torque_Unit 0;
BA_ "GenSigTimeoutTime_BSM" SG_ 1443 Torque_Unit 0;
BA_ "GenSigTimeoutTime_CADM" SG_ 1443 Torque_Unit 0;
BA_ "GenSigTimeoutTime_DMSM" SG_ 1443 Torque_Unit 0;
BA_ "GenSigTimeoutTime_DTCM" SG_ 1443 Torque_Unit 0;
BA_ "GenSigTimeoutTime_ECM" SG_ 1443 Torque_Unit 0;
BA_ "GenSigTimeoutTime_EVCU2" SG_ 1443 Torque_Unit 0;
BA_ "GenSigTimeoutTime_GNMM" SG_ 1443 Torque_Unit 0;
BA_ "GenSigTimeoutTime_HCP" SG_ 1443 Torque_Unit 0;
BA_ "GenSigTimeoutTime_IPC" SG_ 1443 Torque_Unit 0;
BA_ "GenSigTimeoutTime_RFHM" SG_ 1443 Torque_Unit 0;
BA_ "GenSigTimeoutTime_TCM" SG_ 1443 Torque_Unit 0;
BA_ "GenSigSendType" SG_ 1443 Traffic_Sign_Info 3;
BA_ "GenSigTimeoutTime_AGSM" SG_ 1443 Traffic_Sign_Info 0;
BA_ "GenSigTimeoutTime_BSM" SG_ 1443 Traffic_Sign_Info 0;
BA_ "GenSigTimeoutTime_DMSM" SG_ 1443 Traffic_Sign_Info 0;
BA_ "GenSigTimeoutTime_DTCM" SG_ 1443 Traffic_Sign_Info 0;
BA_ "GenSigTimeoutTime_ECM" SG_ 1443 Traffic_Sign_Info 0;
BA_ "GenSigTimeoutTime_EVCU2" SG_ 1443 Traffic_Sign_Info 0;
BA_ "GenSigTimeoutTime_GNMM" SG_ 1443 Traffic_Sign_Info 0;
BA_ "GenSigTimeoutTime_HCP" SG_ 1443 Traffic_Sign_Info 0;
BA_ "GenSigTimeoutTime_IPC" SG_ 1443 Traffic_Sign_Info 0;
BA_ "GenSigTimeoutTime_RFHM" SG_ 1443 Traffic_Sign_Info 0;
BA_ "GenSigTimeoutTime_TCM" SG_ 1443 Traffic_Sign_Info 0;
BA_ "GenSigSendType" SG_ 1443 Traffic_Sign_Warn 3;
BA_ "GenSigTimeoutTime_AGSM" SG_ 1443 Traffic_Sign_Warn 0;
BA_ "GenSigTimeoutTime_BSM" SG_ 1443 Traffic_Sign_Warn 0;
BA_ "GenSigTimeoutTime_CADM" SG_ 1443 Traffic_Sign_Warn 0;
BA_ "GenSigTimeoutTime_DMSM" SG_ 1443 Traffic_Sign_Warn 0;
BA_ "GenSigTimeoutTime_DTCM" SG_ 1443 Traffic_Sign_Warn 0;
BA_ "GenSigTimeoutTime_ECM" SG_ 1443 Traffic_Sign_Warn 0;
BA_ "GenSigTimeoutTime_EVCU2" SG_ 1443 Traffic_Sign_Warn 0;
BA_ "GenSigTimeoutTime_GNMM" SG_ 1443 Traffic_Sign_Warn 0;
BA_ "GenSigTimeoutTime_HCP" SG_ 1443 Traffic_Sign_Warn 0;
BA_ "GenSigTimeoutTime_IPC" SG_ 1443 Traffic_Sign_Warn 0;
BA_ "GenSigTimeoutTime_RFHM" SG_ 1443 Traffic_Sign_Warn 0;
BA_ "GenSigTimeoutTime_TCM" SG_ 1443 Traffic_Sign_Warn 0;
BA_ "GenSigSendType" SG_ 1443 Trail_Brk_Type 3;
BA_ "GenSigTimeoutTime_AGSM" SG_ 1443 Trail_Brk_Type 0;
BA_ "GenSigTimeoutTime_BSM" SG_ 1443 Trail_Brk_Type 0;
BA_ "GenSigTimeoutTime_CADM" SG_ 1443 Trail_Brk_Type 0;
BA_ "GenSigTimeoutTime_DMSM" SG_ 1443 Trail_Brk_Type 0;
BA_ "GenSigTimeoutTime_DTCM" SG_ 1443 Trail_Brk_Type 0;
BA_ "GenSigTimeoutTime_ECM" SG_ 1443 Trail_Brk_Type 0;
BA_ "GenSigTimeoutTime_EVCU2" SG_ 1443 Trail_Brk_Type 0;
BA_ "GenSigTimeoutTime_GNMM" SG_ 1443 Trail_Brk_Type 0;
BA_ "GenSigTimeoutTime_HCP" SG_ 1443 Trail_Brk_Type 0;
BA_ "GenSigTimeoutTime_IPC" SG_ 1443 Trail_Brk_Type 0;
BA_ "GenSigTimeoutTime_RFHM" SG_ 1443 Trail_Brk_Type 0;
BA_ "GenSigTimeoutTime_TCM" SG_ 1443 Trail_Brk_Type 0;
BA_ "GenSigSendType" SG_ 1443 Trail_Name 3;
BA_ "GenSigTimeoutTime_AGSM" SG_ 1443 Trail_Name 0;
BA_ "GenSigTimeoutTime_BSM" SG_ 1443 Trail_Name 0;
BA_ "GenSigTimeoutTime_CADM" SG_ 1443 Trail_Name 0;
BA_ "GenSigTimeoutTime_DMSM" SG_ 1443 Trail_Name 0;
BA_ "GenSigTimeoutTime_DTCM" SG_ 1443 Trail_Name 0;
BA_ "GenSigTimeoutTime_ECM" SG_ 1443 Trail_Name 0;
BA_ "GenSigTimeoutTime_EVCU2" SG_ 1443 Trail_Name 0;
BA_ "GenSigTimeoutTime_GNMM" SG_ 1443 Trail_Name 0;
BA_ "GenSigTimeoutTime_HCP" SG_ 1443 Trail_Name 0;
BA_ "GenSigTimeoutTime_IPC" SG_ 1443 Trail_Name 0;
BA_ "GenSigTimeoutTime_RFHM" SG_ 1443 Trail_Name 0;
BA_ "GenSigTimeoutTime_TCM" SG_ 1443 Trail_Name 0;
BA_ "GenSigSendType" SG_ 1443 Trail_Num 3;
BA_ "GenSigTimeoutTime_AGSM" SG_ 1443 Trail_Num 0;
BA_ "GenSigTimeoutTime_BSM" SG_ 1443 Trail_Num 0;
BA_ "GenSigTimeoutTime_CADM" SG_ 1443 Trail_Num 0;
BA_ "GenSigTimeoutTime_DMSM" SG_ 1443 Trail_Num 0;
BA_ "GenSigTimeoutTime_DTCM" SG_ 1443 Trail_Num 0;
BA_ "GenSigTimeoutTime_ECM" SG_ 1443 Trail_Num 0;
BA_ "GenSigTimeoutTime_EVCU2" SG_ 1443 Trail_Num 0;
BA_ "GenSigTimeoutTime_GNMM" SG_ 1443 Trail_Num 0;
BA_ "GenSigTimeoutTime_HCP" SG_ 1443 Trail_Num 0;
BA_ "GenSigTimeoutTime_IPC" SG_ 1443 Trail_Num 0;
BA_ "GenSigTimeoutTime_RFHM" SG_ 1443 Trail_Num 0;
BA_ "GenSigTimeoutTime_TCM" SG_ 1443 Trail_Num 0;
BA_ "GenSigSendType" SG_ 1443 Trailer_detection_blind_spot 3;
BA_ "GenSigTimeoutTime_AGSM" SG_ 1443 Trailer_detection_blind_spot 0;
BA_ "GenSigTimeoutTime_BSM" SG_ 1443 Trailer_detection_blind_spot 0;
BA_ "GenSigTimeoutTime_DMSM" SG_ 1443 Trailer_detection_blind_spot 0;
BA_ "GenSigTimeoutTime_DTCM" SG_ 1443 Trailer_detection_blind_spot 0;
BA_ "GenSigTimeoutTime_ECM" SG_ 1443 Trailer_detection_blind_spot 0;
BA_ "GenSigTimeoutTime_EVCU2" SG_ 1443 Trailer_detection_blind_spot 0;
BA_ "GenSigTimeoutTime_GNMM" SG_ 1443 Trailer_detection_blind_spot 0;
BA_ "GenSigTimeoutTime_HCP" SG_ 1443 Trailer_detection_blind_spot 0;
BA_ "GenSigTimeoutTime_IPC" SG_ 1443 Trailer_detection_blind_spot 0;
BA_ "GenSigTimeoutTime_RFHM" SG_ 1443 Trailer_detection_blind_spot 0;
BA_ "GenSigTimeoutTime_TCM" SG_ 1443 Trailer_detection_blind_spot 0;
BA_ "GenSigSendType" SG_ 1443 TyrePress_Unit 3;
BA_ "GenSigTimeoutTime_AGSM" SG_ 1443 TyrePress_Unit 0;
BA_ "GenSigTimeoutTime_BSM" SG_ 1443 TyrePress_Unit 0;
BA_ "GenSigTimeoutTime_CADM" SG_ 1443 TyrePress_Unit 0;
BA_ "GenSigTimeoutTime_DMSM" SG_ 1443 TyrePress_Unit 0;
BA_ "GenSigTimeoutTime_DTCM" SG_ 1443 TyrePress_Unit 0;
BA_ "GenSigTimeoutTime_ECM" SG_ 1443 TyrePress_Unit 0;
BA_ "GenSigTimeoutTime_EVCU2" SG_ 1443 TyrePress_Unit 0;
BA_ "GenSigTimeoutTime_GNMM" SG_ 1443 TyrePress_Unit 0;
BA_ "GenSigTimeoutTime_HCP" SG_ 1443 TyrePress_Unit 0;
BA_ "GenSigTimeoutTime_IPC" SG_ 1443 TyrePress_Unit 0;
BA_ "GenSigTimeoutTime_RFHM" SG_ 1443 TyrePress_Unit 0;
BA_ "GenSigTimeoutTime_TCM" SG_ 1443 TyrePress_Unit 0;
BA_ "GenSigSendType" SG_ 1474 AUX1_HLEnbl 3;
BA_ "GenSigTimeoutTime_AGSM" SG_ 1474 AUX1_HLEnbl 0;
BA_ "GenSigTimeoutTime_BSM" SG_ 1474 AUX1_HLEnbl 0;
BA_ "GenSigTimeoutTime_CADM" SG_ 1474 AUX1_HLEnbl 0;
BA_ "GenSigTimeoutTime_DMSM" SG_ 1474 AUX1_HLEnbl 0;
BA_ "GenSigTimeoutTime_DTCM" SG_ 1474 AUX1_HLEnbl 0;
BA_ "GenSigTimeoutTime_ECM" SG_ 1474 AUX1_HLEnbl 0;
BA_ "GenSigTimeoutTime_EVCU2" SG_ 1474 AUX1_HLEnbl 0;
BA_ "GenSigTimeoutTime_GNMM" SG_ 1474 AUX1_HLEnbl 0;
BA_ "GenSigTimeoutTime_HCP" SG_ 1474 AUX1_HLEnbl 0;
BA_ "GenSigTimeoutTime_IPC" SG_ 1474 AUX1_HLEnbl 0;
BA_ "GenSigTimeoutTime_RFHM" SG_ 1474 AUX1_HLEnbl 0;
BA_ "GenSigTimeoutTime_TCM" SG_ 1474 AUX1_HLEnbl 0;
BA_ "GenSigSendType" SG_ 1474 AUX1_PWRMD 3;
BA_ "GenSigTimeoutTime_AGSM" SG_ 1474 AUX1_PWRMD 0;
BA_ "GenSigTimeoutTime_BSM" SG_ 1474 AUX1_PWRMD 0;
BA_ "GenSigTimeoutTime_CADM" SG_ 1474 AUX1_PWRMD 0;
BA_ "GenSigTimeoutTime_DMSM" SG_ 1474 AUX1_PWRMD 0;
BA_ "GenSigTimeoutTime_DTCM" SG_ 1474 AUX1_PWRMD 0;
BA_ "GenSigTimeoutTime_ECM" SG_ 1474 AUX1_PWRMD 0;
BA_ "GenSigTimeoutTime_EVCU2" SG_ 1474 AUX1_PWRMD 0;
BA_ "GenSigTimeoutTime_GNMM" SG_ 1474 AUX1_PWRMD 0;
BA_ "GenSigTimeoutTime_HCP" SG_ 1474 AUX1_PWRMD 0;
BA_ "GenSigTimeoutTime_IPC" SG_ 1474 AUX1_PWRMD 0;
BA_ "GenSigTimeoutTime_RFHM" SG_ 1474 AUX1_PWRMD 0;
BA_ "GenSigTimeoutTime_TCM" SG_ 1474 AUX1_PWRMD 0;
BA_ "GenSigSendType" SG_ 1474 AUX1_TYPE 3;
BA_ "GenSigTimeoutTime_AGSM" SG_ 1474 AUX1_TYPE 0;
BA_ "GenSigTimeoutTime_BSM" SG_ 1474 AUX1_TYPE 0;
BA_ "GenSigTimeoutTime_CADM" SG_ 1474 AUX1_TYPE 0;
BA_ "GenSigTimeoutTime_DMSM" SG_ 1474 AUX1_TYPE 0;
BA_ "GenSigTimeoutTime_DTCM" SG_ 1474 AUX1_TYPE 0;
BA_ "GenSigTimeoutTime_ECM" SG_ 1474 AUX1_TYPE 0;
BA_ "GenSigTimeoutTime_EVCU2" SG_ 1474 AUX1_TYPE 0;
BA_ "GenSigTimeoutTime_GNMM" SG_ 1474 AUX1_TYPE 0;
BA_ "GenSigTimeoutTime_HCP" SG_ 1474 AUX1_TYPE 0;
BA_ "GenSigTimeoutTime_IPC" SG_ 1474 AUX1_TYPE 0;
BA_ "GenSigTimeoutTime_RFHM" SG_ 1474 AUX1_TYPE 0;
BA_ "GenSigTimeoutTime_TCM" SG_ 1474 AUX1_TYPE 0;
BA_ "GenSigSendType" SG_ 1474 AUX2_HLEnbl 3;
BA_ "GenSigTimeoutTime_AGSM" SG_ 1474 AUX2_HLEnbl 0;
BA_ "GenSigTimeoutTime_BSM" SG_ 1474 AUX2_HLEnbl 0;
BA_ "GenSigTimeoutTime_CADM" SG_ 1474 AUX2_HLEnbl 0;
BA_ "GenSigTimeoutTime_DMSM" SG_ 1474 AUX2_HLEnbl 0;
BA_ "GenSigTimeoutTime_DTCM" SG_ 1474 AUX2_HLEnbl 0;
BA_ "GenSigTimeoutTime_ECM" SG_ 1474 AUX2_HLEnbl 0;
BA_ "GenSigTimeoutTime_EVCU2" SG_ 1474 AUX2_HLEnbl 0;
BA_ "GenSigTimeoutTime_GNMM" SG_ 1474 AUX2_HLEnbl 0;
BA_ "GenSigTimeoutTime_HCP" SG_ 1474 AUX2_HLEnbl 0;
BA_ "GenSigTimeoutTime_IPC" SG_ 1474 AUX2_HLEnbl 0;
BA_ "GenSigTimeoutTime_RFHM" SG_ 1474 AUX2_HLEnbl 0;
BA_ "GenSigTimeoutTime_TCM" SG_ 1474 AUX2_HLEnbl 0;
BA_ "GenSigSendType" SG_ 1474 AUX2_PWRMD 3;
BA_ "GenSigTimeoutTime_AGSM" SG_ 1474 AUX2_PWRMD 0;
BA_ "GenSigTimeoutTime_BSM" SG_ 1474 AUX2_PWRMD 0;
BA_ "GenSigTimeoutTime_CADM" SG_ 1474 AUX2_PWRMD 0;
BA_ "GenSigTimeoutTime_DMSM" SG_ 1474 AUX2_PWRMD 0;
BA_ "GenSigTimeoutTime_DTCM" SG_ 1474 AUX2_PWRMD 0;
BA_ "GenSigTimeoutTime_ECM" SG_ 1474 AUX2_PWRMD 0;
BA_ "GenSigTimeoutTime_EVCU2" SG_ 1474 AUX2_PWRMD 0;
BA_ "GenSigTimeoutTime_GNMM" SG_ 1474 AUX2_PWRMD 0;
BA_ "GenSigTimeoutTime_HCP" SG_ 1474 AUX2_PWRMD 0;
BA_ "GenSigTimeoutTime_IPC" SG_ 1474 AUX2_PWRMD 0;
BA_ "GenSigTimeoutTime_RFHM" SG_ 1474 AUX2_PWRMD 0;
BA_ "GenSigTimeoutTime_TCM" SG_ 1474 AUX2_PWRMD 0;
BA_ "GenSigSendType" SG_ 1474 AUX2_TYPE 3;
BA_ "GenSigTimeoutTime_AGSM" SG_ 1474 AUX2_TYPE 0;
BA_ "GenSigTimeoutTime_BSM" SG_ 1474 AUX2_TYPE 0;
BA_ "GenSigTimeoutTime_CADM" SG_ 1474 AUX2_TYPE 0;
BA_ "GenSigTimeoutTime_DMSM" SG_ 1474 AUX2_TYPE 0;
BA_ "GenSigTimeoutTime_DTCM" SG_ 1474 AUX2_TYPE 0;
BA_ "GenSigTimeoutTime_ECM" SG_ 1474 AUX2_TYPE 0;
BA_ "GenSigTimeoutTime_EVCU2" SG_ 1474 AUX2_TYPE 0;
BA_ "GenSigTimeoutTime_GNMM" SG_ 1474 AUX2_TYPE 0;
BA_ "GenSigTimeoutTime_HCP" SG_ 1474 AUX2_TYPE 0;
BA_ "GenSigTimeoutTime_IPC" SG_ 1474 AUX2_TYPE 0;
BA_ "GenSigTimeoutTime_RFHM" SG_ 1474 AUX2_TYPE 0;
BA_ "GenSigTimeoutTime_TCM" SG_ 1474 AUX2_TYPE 0;
BA_ "GenSigSendType" SG_ 1474 AUX3_HLEnbl 3;
BA_ "GenSigTimeoutTime_AGSM" SG_ 1474 AUX3_HLEnbl 0;
BA_ "GenSigTimeoutTime_BSM" SG_ 1474 AUX3_HLEnbl 0;
BA_ "GenSigTimeoutTime_CADM" SG_ 1474 AUX3_HLEnbl 0;
BA_ "GenSigTimeoutTime_DMSM" SG_ 1474 AUX3_HLEnbl 0;
BA_ "GenSigTimeoutTime_DTCM" SG_ 1474 AUX3_HLEnbl 0;
BA_ "GenSigTimeoutTime_ECM" SG_ 1474 AUX3_HLEnbl 0;
BA_ "GenSigTimeoutTime_EVCU2" SG_ 1474 AUX3_HLEnbl 0;
BA_ "GenSigTimeoutTime_GNMM" SG_ 1474 AUX3_HLEnbl 0;
BA_ "GenSigTimeoutTime_HCP" SG_ 1474 AUX3_HLEnbl 0;
BA_ "GenSigTimeoutTime_IPC" SG_ 1474 AUX3_HLEnbl 0;
BA_ "GenSigTimeoutTime_RFHM" SG_ 1474 AUX3_HLEnbl 0;
BA_ "GenSigTimeoutTime_TCM" SG_ 1474 AUX3_HLEnbl 0;
BA_ "GenSigSendType" SG_ 1474 AUX3_PWRMD 3;
BA_ "GenSigTimeoutTime_AGSM" SG_ 1474 AUX3_PWRMD 0;
BA_ "GenSigTimeoutTime_BSM" SG_ 1474 AUX3_PWRMD 0;
BA_ "GenSigTimeoutTime_CADM" SG_ 1474 AUX3_PWRMD 0;
BA_ "GenSigTimeoutTime_DMSM" SG_ 1474 AUX3_PWRMD 0;
BA_ "GenSigTimeoutTime_DTCM" SG_ 1474 AUX3_PWRMD 0;
BA_ "GenSigTimeoutTime_ECM" SG_ 1474 AUX3_PWRMD 0;
BA_ "GenSigTimeoutTime_EVCU2" SG_ 1474 AUX3_PWRMD 0;
BA_ "GenSigTimeoutTime_GNMM" SG_ 1474 AUX3_PWRMD 0;
BA_ "GenSigTimeoutTime_HCP" SG_ 1474 AUX3_PWRMD 0;
BA_ "GenSigTimeoutTime_IPC" SG_ 1474 AUX3_PWRMD 0;
BA_ "GenSigTimeoutTime_RFHM" SG_ 1474 AUX3_PWRMD 0;
BA_ "GenSigTimeoutTime_TCM" SG_ 1474 AUX3_PWRMD 0;
BA_ "GenSigSendType" SG_ 1474 AUX3_TYPE 3;
BA_ "GenSigTimeoutTime_AGSM" SG_ 1474 AUX3_TYPE 0;
BA_ "GenSigTimeoutTime_BSM" SG_ 1474 AUX3_TYPE 0;
BA_ "GenSigTimeoutTime_CADM" SG_ 1474 AUX3_TYPE 0;
BA_ "GenSigTimeoutTime_DMSM" SG_ 1474 AUX3_TYPE 0;
BA_ "GenSigTimeoutTime_DTCM" SG_ 1474 AUX3_TYPE 0;
BA_ "GenSigTimeoutTime_ECM" SG_ 1474 AUX3_TYPE 0;
BA_ "GenSigTimeoutTime_EVCU2" SG_ 1474 AUX3_TYPE 0;
BA_ "GenSigTimeoutTime_GNMM" SG_ 1474 AUX3_TYPE 0;
BA_ "GenSigTimeoutTime_HCP" SG_ 1474 AUX3_TYPE 0;
BA_ "GenSigTimeoutTime_IPC" SG_ 1474 AUX3_TYPE 0;
BA_ "GenSigTimeoutTime_RFHM" SG_ 1474 AUX3_TYPE 0;
BA_ "GenSigTimeoutTime_TCM" SG_ 1474 AUX3_TYPE 0;
BA_ "GenSigSendType" SG_ 1474 AUX4_HLEnbl 3;
BA_ "GenSigTimeoutTime_AGSM" SG_ 1474 AUX4_HLEnbl 0;
BA_ "GenSigTimeoutTime_BSM" SG_ 1474 AUX4_HLEnbl 0;
BA_ "GenSigTimeoutTime_CADM" SG_ 1474 AUX4_HLEnbl 0;
BA_ "GenSigTimeoutTime_DMSM" SG_ 1474 AUX4_HLEnbl 0;
BA_ "GenSigTimeoutTime_DTCM" SG_ 1474 AUX4_HLEnbl 0;
BA_ "GenSigTimeoutTime_ECM" SG_ 1474 AUX4_HLEnbl 0;
BA_ "GenSigTimeoutTime_EVCU2" SG_ 1474 AUX4_HLEnbl 0;
BA_ "GenSigTimeoutTime_GNMM" SG_ 1474 AUX4_HLEnbl 0;
BA_ "GenSigTimeoutTime_HCP" SG_ 1474 AUX4_HLEnbl 0;
BA_ "GenSigTimeoutTime_IPC" SG_ 1474 AUX4_HLEnbl 0;
BA_ "GenSigTimeoutTime_RFHM" SG_ 1474 AUX4_HLEnbl 0;
BA_ "GenSigTimeoutTime_TCM" SG_ 1474 AUX4_HLEnbl 0;
BA_ "GenSigSendType" SG_ 1474 AUX4_PWRMD 3;
BA_ "GenSigTimeoutTime_AGSM" SG_ 1474 AUX4_PWRMD 0;
BA_ "GenSigTimeoutTime_BSM" SG_ 1474 AUX4_PWRMD 0;
BA_ "GenSigTimeoutTime_CADM" SG_ 1474 AUX4_PWRMD 0;
BA_ "GenSigTimeoutTime_DMSM" SG_ 1474 AUX4_PWRMD 0;
BA_ "GenSigTimeoutTime_DTCM" SG_ 1474 AUX4_PWRMD 0;
BA_ "GenSigTimeoutTime_ECM" SG_ 1474 AUX4_PWRMD 0;
BA_ "GenSigTimeoutTime_EVCU2" SG_ 1474 AUX4_PWRMD 0;
BA_ "GenSigTimeoutTime_GNMM" SG_ 1474 AUX4_PWRMD 0;
BA_ "GenSigTimeoutTime_HCP" SG_ 1474 AUX4_PWRMD 0;
BA_ "GenSigTimeoutTime_IPC" SG_ 1474 AUX4_PWRMD 0;
BA_ "GenSigTimeoutTime_RFHM" SG_ 1474 AUX4_PWRMD 0;
BA_ "GenSigTimeoutTime_TCM" SG_ 1474 AUX4_PWRMD 0;
BA_ "GenSigSendType" SG_ 1474 AUX4_TYPE 3;
BA_ "GenSigTimeoutTime_AGSM" SG_ 1474 AUX4_TYPE 0;
BA_ "GenSigTimeoutTime_BSM" SG_ 1474 AUX4_TYPE 0;
BA_ "GenSigTimeoutTime_CADM" SG_ 1474 AUX4_TYPE 0;
BA_ "GenSigTimeoutTime_DMSM" SG_ 1474 AUX4_TYPE 0;
BA_ "GenSigTimeoutTime_DTCM" SG_ 1474 AUX4_TYPE 0;
BA_ "GenSigTimeoutTime_ECM" SG_ 1474 AUX4_TYPE 0;
BA_ "GenSigTimeoutTime_EVCU2" SG_ 1474 AUX4_TYPE 0;
BA_ "GenSigTimeoutTime_GNMM" SG_ 1474 AUX4_TYPE 0;
BA_ "GenSigTimeoutTime_HCP" SG_ 1474 AUX4_TYPE 0;
BA_ "GenSigTimeoutTime_IPC" SG_ 1474 AUX4_TYPE 0;
BA_ "GenSigTimeoutTime_RFHM" SG_ 1474 AUX4_TYPE 0;
BA_ "GenSigTimeoutTime_TCM" SG_ 1474 AUX4_TYPE 0;
BA_ "GenSigSendType" SG_ 1474 AUX5_HLEnbl 4;
BA_ "GenSigTimeoutTime_AGSM" SG_ 1474 AUX5_HLEnbl 0;
BA_ "GenSigTimeoutTime_BSM" SG_ 1474 AUX5_HLEnbl 0;
BA_ "GenSigTimeoutTime_CADM" SG_ 1474 AUX5_HLEnbl 0;
BA_ "GenSigTimeoutTime_DMSM" SG_ 1474 AUX5_HLEnbl 0;
BA_ "GenSigTimeoutTime_DTCM" SG_ 1474 AUX5_HLEnbl 0;
BA_ "GenSigTimeoutTime_ECM" SG_ 1474 AUX5_HLEnbl 0;
BA_ "GenSigTimeoutTime_EVCU2" SG_ 1474 AUX5_HLEnbl 0;
BA_ "GenSigTimeoutTime_GNMM" SG_ 1474 AUX5_HLEnbl 0;
BA_ "GenSigTimeoutTime_HCP" SG_ 1474 AUX5_HLEnbl 0;
BA_ "GenSigTimeoutTime_IPC" SG_ 1474 AUX5_HLEnbl 0;
BA_ "GenSigTimeoutTime_RFHM" SG_ 1474 AUX5_HLEnbl 0;
BA_ "GenSigTimeoutTime_TCM" SG_ 1474 AUX5_HLEnbl 0;
BA_ "GenSigStartValue" SG_ 1474 AUX5_PWRMD 1;
BA_ "GenSigSendType" SG_ 1474 AUX5_PWRMD 4;
BA_ "GenSigTimeoutTime_AGSM" SG_ 1474 AUX5_PWRMD 0;
BA_ "GenSigTimeoutTime_BSM" SG_ 1474 AUX5_PWRMD 0;
BA_ "GenSigTimeoutTime_CADM" SG_ 1474 AUX5_PWRMD 0;
BA_ "GenSigTimeoutTime_DMSM" SG_ 1474 AUX5_PWRMD 0;
BA_ "GenSigTimeoutTime_DTCM" SG_ 1474 AUX5_PWRMD 0;
BA_ "GenSigTimeoutTime_ECM" SG_ 1474 AUX5_PWRMD 0;
BA_ "GenSigTimeoutTime_EVCU2" SG_ 1474 AUX5_PWRMD 0;
BA_ "GenSigTimeoutTime_GNMM" SG_ 1474 AUX5_PWRMD 0;
BA_ "GenSigTimeoutTime_HCP" SG_ 1474 AUX5_PWRMD 0;
BA_ "GenSigTimeoutTime_IPC" SG_ 1474 AUX5_PWRMD 0;
BA_ "GenSigTimeoutTime_RFHM" SG_ 1474 AUX5_PWRMD 0;
BA_ "GenSigTimeoutTime_TCM" SG_ 1474 AUX5_PWRMD 0;
BA_ "GenSigStartValue" SG_ 1474 AUX5_TYPE 1;
BA_ "GenSigSendType" SG_ 1474 AUX5_TYPE 4;
BA_ "GenSigTimeoutTime_AGSM" SG_ 1474 AUX5_TYPE 0;
BA_ "GenSigTimeoutTime_BSM" SG_ 1474 AUX5_TYPE 0;
BA_ "GenSigTimeoutTime_CADM" SG_ 1474 AUX5_TYPE 0;
BA_ "GenSigTimeoutTime_DMSM" SG_ 1474 AUX5_TYPE 0;
BA_ "GenSigTimeoutTime_DTCM" SG_ 1474 AUX5_TYPE 0;
BA_ "GenSigTimeoutTime_ECM" SG_ 1474 AUX5_TYPE 0;
BA_ "GenSigTimeoutTime_EVCU2" SG_ 1474 AUX5_TYPE 0;
BA_ "GenSigTimeoutTime_GNMM" SG_ 1474 AUX5_TYPE 0;
BA_ "GenSigTimeoutTime_HCP" SG_ 1474 AUX5_TYPE 0;
BA_ "GenSigTimeoutTime_IPC" SG_ 1474 AUX5_TYPE 0;
BA_ "GenSigTimeoutTime_RFHM" SG_ 1474 AUX5_TYPE 0;
BA_ "GenSigTimeoutTime_TCM" SG_ 1474 AUX5_TYPE 0;
BA_ "GenSigSendType" SG_ 1474 AUX6_HLEnbl 4;
BA_ "GenSigTimeoutTime_AGSM" SG_ 1474 AUX6_HLEnbl 0;
BA_ "GenSigTimeoutTime_BSM" SG_ 1474 AUX6_HLEnbl 0;
BA_ "GenSigTimeoutTime_CADM" SG_ 1474 AUX6_HLEnbl 0;
BA_ "GenSigTimeoutTime_DMSM" SG_ 1474 AUX6_HLEnbl 0;
BA_ "GenSigTimeoutTime_DTCM" SG_ 1474 AUX6_HLEnbl 0;
BA_ "GenSigTimeoutTime_ECM" SG_ 1474 AUX6_HLEnbl 0;
BA_ "GenSigTimeoutTime_EVCU2" SG_ 1474 AUX6_HLEnbl 0;
BA_ "GenSigTimeoutTime_GNMM" SG_ 1474 AUX6_HLEnbl 0;
BA_ "GenSigTimeoutTime_HCP" SG_ 1474 AUX6_HLEnbl 0;
BA_ "GenSigTimeoutTime_IPC" SG_ 1474 AUX6_HLEnbl 0;
BA_ "GenSigTimeoutTime_RFHM" SG_ 1474 AUX6_HLEnbl 0;
BA_ "GenSigTimeoutTime_TCM" SG_ 1474 AUX6_HLEnbl 0;
BA_ "GenSigStartValue" SG_ 1474 AUX6_PWRMD 1;
BA_ "GenSigSendType" SG_ 1474 AUX6_PWRMD 4;
BA_ "GenSigTimeoutTime_AGSM" SG_ 1474 AUX6_PWRMD 0;
BA_ "GenSigTimeoutTime_BSM" SG_ 1474 AUX6_PWRMD 0;
BA_ "GenSigTimeoutTime_CADM" SG_ 1474 AUX6_PWRMD 0;
BA_ "GenSigTimeoutTime_DMSM" SG_ 1474 AUX6_PWRMD 0;
BA_ "GenSigTimeoutTime_DTCM" SG_ 1474 AUX6_PWRMD 0;
BA_ "GenSigTimeoutTime_ECM" SG_ 1474 AUX6_PWRMD 0;
BA_ "GenSigTimeoutTime_EVCU2" SG_ 1474 AUX6_PWRMD 0;
BA_ "GenSigTimeoutTime_GNMM" SG_ 1474 AUX6_PWRMD 0;
BA_ "GenSigTimeoutTime_HCP" SG_ 1474 AUX6_PWRMD 0;
BA_ "GenSigTimeoutTime_IPC" SG_ 1474 AUX6_PWRMD 0;
BA_ "GenSigTimeoutTime_RFHM" SG_ 1474 AUX6_PWRMD 0;
BA_ "GenSigTimeoutTime_TCM" SG_ 1474 AUX6_PWRMD 0;
BA_ "GenSigStartValue" SG_ 1474 AUX6_TYPE 1;
BA_ "GenSigSendType" SG_ 1474 AUX6_TYPE 4;
BA_ "GenSigTimeoutTime_AGSM" SG_ 1474 AUX6_TYPE 0;
BA_ "GenSigTimeoutTime_BSM" SG_ 1474 AUX6_TYPE 0;
BA_ "GenSigTimeoutTime_CADM" SG_ 1474 AUX6_TYPE 0;
BA_ "GenSigTimeoutTime_DMSM" SG_ 1474 AUX6_TYPE 0;
BA_ "GenSigTimeoutTime_DTCM" SG_ 1474 AUX6_TYPE 0;
BA_ "GenSigTimeoutTime_ECM" SG_ 1474 AUX6_TYPE 0;
BA_ "GenSigTimeoutTime_EVCU2" SG_ 1474 AUX6_TYPE 0;
BA_ "GenSigTimeoutTime_GNMM" SG_ 1474 AUX6_TYPE 0;
BA_ "GenSigTimeoutTime_HCP" SG_ 1474 AUX6_TYPE 0;
BA_ "GenSigTimeoutTime_IPC" SG_ 1474 AUX6_TYPE 0;
BA_ "GenSigTimeoutTime_RFHM" SG_ 1474 AUX6_TYPE 0;
BA_ "GenSigTimeoutTime_TCM" SG_ 1474 AUX6_TYPE 0;
BA_ "GenSigSendType" SG_ 1474 Default_Ride_Height 4;
BA_ "GenSigTimeoutTime_AGSM" SG_ 1474 Default_Ride_Height 0;
BA_ "GenSigTimeoutTime_BSM" SG_ 1474 Default_Ride_Height 0;
BA_ "GenSigTimeoutTime_CADM" SG_ 1474 Default_Ride_Height 0;
BA_ "GenSigTimeoutTime_DMSM" SG_ 1474 Default_Ride_Height 0;
BA_ "GenSigTimeoutTime_DTCM" SG_ 1474 Default_Ride_Height 0;
BA_ "GenSigTimeoutTime_ECM" SG_ 1474 Default_Ride_Height 0;
BA_ "GenSigTimeoutTime_EVCU2" SG_ 1474 Default_Ride_Height 0;
BA_ "GenSigTimeoutTime_GNMM" SG_ 1474 Default_Ride_Height 0;
BA_ "GenSigTimeoutTime_HCP" SG_ 1474 Default_Ride_Height 0;
BA_ "GenSigTimeoutTime_IPC" SG_ 1474 Default_Ride_Height 0;
BA_ "GenSigTimeoutTime_RFHM" SG_ 1474 Default_Ride_Height 0;
BA_ "GenSigTimeoutTime_TCM" SG_ 1474 Default_Ride_Height 0;
BA_ "GenSigStartValue" SG_ 1474 Display_Synch 1;
BA_ "GenSigSendType" SG_ 1474 Display_Synch 4;
BA_ "GenSigTimeoutTime_AGSM" SG_ 1474 Display_Synch 0;
BA_ "GenSigTimeoutTime_BCM" SG_ 1474 Display_Synch 0;
BA_ "GenSigTimeoutTime_BSM" SG_ 1474 Display_Synch 0;
BA_ "GenSigTimeoutTime_CADM" SG_ 1474 Display_Synch 0;
BA_ "GenSigTimeoutTime_DMSM" SG_ 1474 Display_Synch 0;
BA_ "GenSigTimeoutTime_DTCM" SG_ 1474 Display_Synch 0;
BA_ "GenSigTimeoutTime_ECM" SG_ 1474 Display_Synch 0;
BA_ "GenSigTimeoutTime_EVCU2" SG_ 1474 Display_Synch 0;
BA_ "GenSigTimeoutTime_GNMM" SG_ 1474 Display_Synch 0;
BA_ "GenSigTimeoutTime_HCP" SG_ 1474 Display_Synch 0;
BA_ "GenSigTimeoutTime_IPC" SG_ 1474 Display_Synch 0;
BA_ "GenSigTimeoutTime_RFHM" SG_ 1474 Display_Synch 0;
BA_ "GenSigTimeoutTime_TCM" SG_ 1474 Display_Synch 0;
BA_ "GenSigSendType" SG_ 1474 EPB_Service_Mode 4;
BA_ "GenSigTimeoutTime_AGSM" SG_ 1474 EPB_Service_Mode 0;
BA_ "GenSigTimeoutTime_BSM" SG_ 1474 EPB_Service_Mode 0;
BA_ "GenSigTimeoutTime_CADM" SG_ 1474 EPB_Service_Mode 0;
BA_ "GenSigTimeoutTime_DMSM" SG_ 1474 EPB_Service_Mode 0;
BA_ "GenSigTimeoutTime_DTCM" SG_ 1474 EPB_Service_Mode 0;
BA_ "GenSigTimeoutTime_ECM" SG_ 1474 EPB_Service_Mode 0;
BA_ "GenSigTimeoutTime_EVCU2" SG_ 1474 EPB_Service_Mode 0;
BA_ "GenSigTimeoutTime_GNMM" SG_ 1474 EPB_Service_Mode 0;
BA_ "GenSigTimeoutTime_HCP" SG_ 1474 EPB_Service_Mode 0;
BA_ "GenSigTimeoutTime_IPC" SG_ 1474 EPB_Service_Mode 0;
BA_ "GenSigTimeoutTime_RFHM" SG_ 1474 EPB_Service_Mode 0;
BA_ "GenSigTimeoutTime_TCM" SG_ 1474 EPB_Service_Mode 0;
BA_ "GenSigStartValue" SG_ 1474 FOA_Alert_Type 1;
BA_ "GenSigSendType" SG_ 1474 FOA_Alert_Type 3;
BA_ "GenSigTimeoutTime_AGSM" SG_ 1474 FOA_Alert_Type 0;
BA_ "GenSigTimeoutTime_BSM" SG_ 1474 FOA_Alert_Type 0;
BA_ "GenSigTimeoutTime_CADM" SG_ 1474 FOA_Alert_Type 0;
BA_ "GenSigTimeoutTime_DMSM" SG_ 1474 FOA_Alert_Type 0;
BA_ "GenSigTimeoutTime_DTCM" SG_ 1474 FOA_Alert_Type 0;
BA_ "GenSigTimeoutTime_ECM" SG_ 1474 FOA_Alert_Type 0;
BA_ "GenSigTimeoutTime_EVCU2" SG_ 1474 FOA_Alert_Type 0;
BA_ "GenSigTimeoutTime_GNMM" SG_ 1474 FOA_Alert_Type 0;
BA_ "GenSigTimeoutTime_HCP" SG_ 1474 FOA_Alert_Type 0;
BA_ "GenSigTimeoutTime_IPC" SG_ 1474 FOA_Alert_Type 0;
BA_ "GenSigTimeoutTime_RFHM" SG_ 1474 FOA_Alert_Type 0;
BA_ "GenSigTimeoutTime_TCM" SG_ 1474 FOA_Alert_Type 0;
BA_ "GenSigSendType" SG_ 1474 Fuel_Saver_Display 4;
BA_ "GenSigTimeoutTime_AGSM" SG_ 1474 Fuel_Saver_Display 0;
BA_ "GenSigTimeoutTime_BSM" SG_ 1474 Fuel_Saver_Display 0;
BA_ "GenSigTimeoutTime_CADM" SG_ 1474 Fuel_Saver_Display 0;
BA_ "GenSigTimeoutTime_DMSM" SG_ 1474 Fuel_Saver_Display 0;
BA_ "GenSigTimeoutTime_DTCM" SG_ 1474 Fuel_Saver_Display 0;
BA_ "GenSigTimeoutTime_ECM" SG_ 1474 Fuel_Saver_Display 0;
BA_ "GenSigTimeoutTime_EVCU2" SG_ 1474 Fuel_Saver_Display 0;
BA_ "GenSigTimeoutTime_GNMM" SG_ 1474 Fuel_Saver_Display 0;
BA_ "GenSigTimeoutTime_HCP" SG_ 1474 Fuel_Saver_Display 0;
BA_ "GenSigTimeoutTime_IPC" SG_ 1474 Fuel_Saver_Display 0;
BA_ "GenSigTimeoutTime_RFHM" SG_ 1474 Fuel_Saver_Display 0;
BA_ "GenSigTimeoutTime_TCM" SG_ 1474 Fuel_Saver_Display 0;
BA_ "GenSigSendType" SG_ 1474 ParkSenseSignalView 4;
BA_ "GenSigTimeoutTime_AGSM" SG_ 1474 ParkSenseSignalView 0;
BA_ "GenSigTimeoutTime_BSM" SG_ 1474 ParkSenseSignalView 0;
BA_ "GenSigTimeoutTime_CADM" SG_ 1474 ParkSenseSignalView 0;
BA_ "GenSigTimeoutTime_DMSM" SG_ 1474 ParkSenseSignalView 0;
BA_ "GenSigTimeoutTime_DTCM" SG_ 1474 ParkSenseSignalView 0;
BA_ "GenSigTimeoutTime_ECM" SG_ 1474 ParkSenseSignalView 0;
BA_ "GenSigTimeoutTime_EVCU2" SG_ 1474 ParkSenseSignalView 0;
BA_ "GenSigTimeoutTime_GNMM" SG_ 1474 ParkSenseSignalView 0;
BA_ "GenSigTimeoutTime_HCP" SG_ 1474 ParkSenseSignalView 0;
BA_ "GenSigTimeoutTime_IPC" SG_ 1474 ParkSenseSignalView 0;
BA_ "GenSigTimeoutTime_RFHM" SG_ 1474 ParkSenseSignalView 0;
BA_ "GenSigTimeoutTime_TCM" SG_ 1474 ParkSenseSignalView 0;
BA_ "GenSigStartValue" SG_ 1474 PFTM_Alert 1;
BA_ "GenSigSendType" SG_ 1474 PFTM_Alert 4;
BA_ "GenSigTimeoutTime_AGSM" SG_ 1474 PFTM_Alert 0;
BA_ "GenSigTimeoutTime_BSM" SG_ 1474 PFTM_Alert 0;
BA_ "GenSigTimeoutTime_CADM" SG_ 1474 PFTM_Alert 0;
BA_ "GenSigTimeoutTime_DMSM" SG_ 1474 PFTM_Alert 0;
BA_ "GenSigTimeoutTime_DTCM" SG_ 1474 PFTM_Alert 0;
BA_ "GenSigTimeoutTime_ECM" SG_ 1474 PFTM_Alert 0;
BA_ "GenSigTimeoutTime_EVCU2" SG_ 1474 PFTM_Alert 0;
BA_ "GenSigTimeoutTime_GNMM" SG_ 1474 PFTM_Alert 0;
BA_ "GenSigTimeoutTime_HCP" SG_ 1474 PFTM_Alert 0;
BA_ "GenSigTimeoutTime_IPC" SG_ 1474 PFTM_Alert 0;
BA_ "GenSigTimeoutTime_RFHM" SG_ 1474 PFTM_Alert 0;
BA_ "GenSigTimeoutTime_TCM" SG_ 1474 PFTM_Alert 0;
BA_ "GenSigStartValue" SG_ 1474 PFTM_Enable 1;
BA_ "GenSigSendType" SG_ 1474 PFTM_Enable 4;
BA_ "GenSigTimeoutTime_AGSM" SG_ 1474 PFTM_Enable 0;
BA_ "GenSigTimeoutTime_BCM" SG_ 1474 PFTM_Enable 0;
BA_ "GenSigTimeoutTime_BSM" SG_ 1474 PFTM_Enable 0;
BA_ "GenSigTimeoutTime_CADM" SG_ 1474 PFTM_Enable 0;
BA_ "GenSigTimeoutTime_DMSM" SG_ 1474 PFTM_Enable 0;
BA_ "GenSigTimeoutTime_DTCM" SG_ 1474 PFTM_Enable 0;
BA_ "GenSigTimeoutTime_ECM" SG_ 1474 PFTM_Enable 0;
BA_ "GenSigTimeoutTime_EVCU2" SG_ 1474 PFTM_Enable 0;
BA_ "GenSigTimeoutTime_GNMM" SG_ 1474 PFTM_Enable 0;
BA_ "GenSigTimeoutTime_HCP" SG_ 1474 PFTM_Enable 0;
BA_ "GenSigTimeoutTime_IPC" SG_ 1474 PFTM_Enable 0;
BA_ "GenSigTimeoutTime_RFHM" SG_ 1474 PFTM_Enable 0;
BA_ "GenSigTimeoutTime_TCM" SG_ 1474 PFTM_Enable 0;
BA_ "GenSigStartValue" SG_ 1474 Power_Tailgate_Enable 1;
BA_ "GenSigSendType" SG_ 1474 Power_Tailgate_Enable 4;
BA_ "GenSigTimeoutTime_AGSM" SG_ 1474 Power_Tailgate_Enable 0;
BA_ "GenSigTimeoutTime_BSM" SG_ 1474 Power_Tailgate_Enable 0;
BA_ "GenSigTimeoutTime_CADM" SG_ 1474 Power_Tailgate_Enable 0;
BA_ "GenSigTimeoutTime_DMSM" SG_ 1474 Power_Tailgate_Enable 0;
BA_ "GenSigTimeoutTime_DTCM" SG_ 1474 Power_Tailgate_Enable 0;
BA_ "GenSigTimeoutTime_ECM" SG_ 1474 Power_Tailgate_Enable 0;
BA_ "GenSigTimeoutTime_EVCU2" SG_ 1474 Power_Tailgate_Enable 0;
BA_ "GenSigTimeoutTime_GNMM" SG_ 1474 Power_Tailgate_Enable 0;
BA_ "GenSigTimeoutTime_HCP" SG_ 1474 Power_Tailgate_Enable 0;
BA_ "GenSigTimeoutTime_IPC" SG_ 1474 Power_Tailgate_Enable 0;
BA_ "GenSigTimeoutTime_RFHM" SG_ 1474 Power_Tailgate_Enable 0;
BA_ "GenSigTimeoutTime_TCM" SG_ 1474 Power_Tailgate_Enable 0;
BA_ "GenSigStartValue" SG_ 1474 Rear_G_LGT_with_Cargo_Lights 1;
BA_ "GenSigSendType" SG_ 1474 Rear_G_LGT_with_Cargo_Lights 4;
BA_ "GenSigTimeoutTime_AGSM" SG_ 1474 Rear_G_LGT_with_Cargo_Lights 0;
BA_ "GenSigTimeoutTime_BSM" SG_ 1474 Rear_G_LGT_with_Cargo_Lights 0;
BA_ "GenSigTimeoutTime_CADM" SG_ 1474 Rear_G_LGT_with_Cargo_Lights 0;
BA_ "GenSigTimeoutTime_DMSM" SG_ 1474 Rear_G_LGT_with_Cargo_Lights 0;
BA_ "GenSigTimeoutTime_DTCM" SG_ 1474 Rear_G_LGT_with_Cargo_Lights 0;
BA_ "GenSigTimeoutTime_ECM" SG_ 1474 Rear_G_LGT_with_Cargo_Lights 0;
BA_ "GenSigTimeoutTime_EVCU2" SG_ 1474 Rear_G_LGT_with_Cargo_Lights 0;
BA_ "GenSigTimeoutTime_GNMM" SG_ 1474 Rear_G_LGT_with_Cargo_Lights 0;
BA_ "GenSigTimeoutTime_HCP" SG_ 1474 Rear_G_LGT_with_Cargo_Lights 0;
BA_ "GenSigTimeoutTime_IPC" SG_ 1474 Rear_G_LGT_with_Cargo_Lights 0;
BA_ "GenSigTimeoutTime_RFHM" SG_ 1474 Rear_G_LGT_with_Cargo_Lights 0;
BA_ "GenSigTimeoutTime_TCM" SG_ 1474 Rear_G_LGT_with_Cargo_Lights 0;
BA_ "GenSigSendType" SG_ 1474 Rear_Guidance_Light_Status 4;
BA_ "GenSigTimeoutTime_AGSM" SG_ 1474 Rear_Guidance_Light_Status 0;
BA_ "GenSigTimeoutTime_BSM" SG_ 1474 Rear_Guidance_Light_Status 0;
BA_ "GenSigTimeoutTime_CADM" SG_ 1474 Rear_Guidance_Light_Status 0;
BA_ "GenSigTimeoutTime_DMSM" SG_ 1474 Rear_Guidance_Light_Status 0;
BA_ "GenSigTimeoutTime_DTCM" SG_ 1474 Rear_Guidance_Light_Status 0;
BA_ "GenSigTimeoutTime_ECM" SG_ 1474 Rear_Guidance_Light_Status 0;
BA_ "GenSigTimeoutTime_EVCU2" SG_ 1474 Rear_Guidance_Light_Status 0;
BA_ "GenSigTimeoutTime_GNMM" SG_ 1474 Rear_Guidance_Light_Status 0;
BA_ "GenSigTimeoutTime_HCP" SG_ 1474 Rear_Guidance_Light_Status 0;
BA_ "GenSigTimeoutTime_IPC" SG_ 1474 Rear_Guidance_Light_Status 0;
BA_ "GenSigTimeoutTime_RFHM" SG_ 1474 Rear_Guidance_Light_Status 0;
BA_ "GenSigTimeoutTime_TCM" SG_ 1474 Rear_Guidance_Light_Status 0;
BA_ "GenSigSendType" SG_ 1474 Rear_Lights_with_Approach 4;
BA_ "GenSigTimeoutTime_AGSM" SG_ 1474 Rear_Lights_with_Approach 0;
BA_ "GenSigTimeoutTime_BSM" SG_ 1474 Rear_Lights_with_Approach 0;
BA_ "GenSigTimeoutTime_CADM" SG_ 1474 Rear_Lights_with_Approach 0;
BA_ "GenSigTimeoutTime_DMSM" SG_ 1474 Rear_Lights_with_Approach 0;
BA_ "GenSigTimeoutTime_DTCM" SG_ 1474 Rear_Lights_with_Approach 0;
BA_ "GenSigTimeoutTime_ECM" SG_ 1474 Rear_Lights_with_Approach 0;
BA_ "GenSigTimeoutTime_EVCU2" SG_ 1474 Rear_Lights_with_Approach 0;
BA_ "GenSigTimeoutTime_GNMM" SG_ 1474 Rear_Lights_with_Approach 0;
BA_ "GenSigTimeoutTime_HCP" SG_ 1474 Rear_Lights_with_Approach 0;
BA_ "GenSigTimeoutTime_IPC" SG_ 1474 Rear_Lights_with_Approach 0;
BA_ "GenSigTimeoutTime_RFHM" SG_ 1474 Rear_Lights_with_Approach 0;
BA_ "GenSigTimeoutTime_TCM" SG_ 1474 Rear_Lights_with_Approach 0;
BA_ "GenSigStartValue" SG_ 1474 SignatureLightingEnable 1;
BA_ "GenSigSendType" SG_ 1474 SignatureLightingEnable 4;
BA_ "GenSigTimeoutTime_AGSM" SG_ 1474 SignatureLightingEnable 0;
BA_ "GenSigTimeoutTime_BSM" SG_ 1474 SignatureLightingEnable 0;
BA_ "GenSigTimeoutTime_CADM" SG_ 1474 SignatureLightingEnable 0;
BA_ "GenSigTimeoutTime_DMSM" SG_ 1474 SignatureLightingEnable 0;
BA_ "GenSigTimeoutTime_DTCM" SG_ 1474 SignatureLightingEnable 0;
BA_ "GenSigTimeoutTime_ECM" SG_ 1474 SignatureLightingEnable 0;
BA_ "GenSigTimeoutTime_EVCU2" SG_ 1474 SignatureLightingEnable 0;
BA_ "GenSigTimeoutTime_GNMM" SG_ 1474 SignatureLightingEnable 0;
BA_ "GenSigTimeoutTime_HCP" SG_ 1474 SignatureLightingEnable 0;
BA_ "GenSigTimeoutTime_IPC" SG_ 1474 SignatureLightingEnable 0;
BA_ "GenSigTimeoutTime_RFHM" SG_ 1474 SignatureLightingEnable 0;
BA_ "GenSigTimeoutTime_TCM" SG_ 1474 SignatureLightingEnable 0;
BA_ "GenSigStartValue" SG_ 1474 Trailer_Light_Check 1;
BA_ "GenSigSendType" SG_ 1474 Trailer_Light_Check 3;
BA_ "GenSigTimeoutTime_AGSM" SG_ 1474 Trailer_Light_Check 0;
BA_ "GenSigTimeoutTime_BSM" SG_ 1474 Trailer_Light_Check 0;
BA_ "GenSigTimeoutTime_CADM" SG_ 1474 Trailer_Light_Check 0;
BA_ "GenSigTimeoutTime_DMSM" SG_ 1474 Trailer_Light_Check 0;
BA_ "GenSigTimeoutTime_DTCM" SG_ 1474 Trailer_Light_Check 0;
BA_ "GenSigTimeoutTime_ECM" SG_ 1474 Trailer_Light_Check 0;
BA_ "GenSigTimeoutTime_EVCU2" SG_ 1474 Trailer_Light_Check 0;
BA_ "GenSigTimeoutTime_GNMM" SG_ 1474 Trailer_Light_Check 0;
BA_ "GenSigTimeoutTime_HCP" SG_ 1474 Trailer_Light_Check 0;
BA_ "GenSigTimeoutTime_IPC" SG_ 1474 Trailer_Light_Check 0;
BA_ "GenSigTimeoutTime_RFHM" SG_ 1474 Trailer_Light_Check 0;
BA_ "GenSigTimeoutTime_TCM" SG_ 1474 Trailer_Light_Check 0;
BA_ "GenSigStartValue" SG_ 1474 TSI_Offset_Kph 1;
BA_ "GenSigSendType" SG_ 1474 TSI_Offset_Kph 3;
BA_ "GenSigTimeoutTime_AGSM" SG_ 1474 TSI_Offset_Kph 0;
BA_ "GenSigTimeoutTime_BSM" SG_ 1474 TSI_Offset_Kph 0;
BA_ "GenSigTimeoutTime_CADM" SG_ 1474 TSI_Offset_Kph 0;
BA_ "GenSigTimeoutTime_DMSM" SG_ 1474 TSI_Offset_Kph 0;
BA_ "GenSigTimeoutTime_DTCM" SG_ 1474 TSI_Offset_Kph 0;
BA_ "GenSigTimeoutTime_ECM" SG_ 1474 TSI_Offset_Kph 0;
BA_ "GenSigTimeoutTime_EVCU2" SG_ 1474 TSI_Offset_Kph 0;
BA_ "GenSigTimeoutTime_GNMM" SG_ 1474 TSI_Offset_Kph 0;
BA_ "GenSigTimeoutTime_HCP" SG_ 1474 TSI_Offset_Kph 0;
BA_ "GenSigTimeoutTime_RFHM" SG_ 1474 TSI_Offset_Kph 0;
BA_ "GenSigTimeoutTime_TCM" SG_ 1474 TSI_Offset_Kph 0;
BA_ "GenSigStartValue" SG_ 1474 TSI_Offset_Mph 1;
BA_ "GenSigSendType" SG_ 1474 TSI_Offset_Mph 3;
BA_ "GenSigTimeoutTime_AGSM" SG_ 1474 TSI_Offset_Mph 0;
BA_ "GenSigTimeoutTime_BSM" SG_ 1474 TSI_Offset_Mph 0;
BA_ "GenSigTimeoutTime_CADM" SG_ 1474 TSI_Offset_Mph 0;
BA_ "GenSigTimeoutTime_DMSM" SG_ 1474 TSI_Offset_Mph 0;
BA_ "GenSigTimeoutTime_DTCM" SG_ 1474 TSI_Offset_Mph 0;
BA_ "GenSigTimeoutTime_ECM" SG_ 1474 TSI_Offset_Mph 0;
BA_ "GenSigTimeoutTime_EVCU2" SG_ 1474 TSI_Offset_Mph 0;
BA_ "GenSigTimeoutTime_GNMM" SG_ 1474 TSI_Offset_Mph 0;
BA_ "GenSigTimeoutTime_HCP" SG_ 1474 TSI_Offset_Mph 0;
BA_ "GenSigTimeoutTime_RFHM" SG_ 1474 TSI_Offset_Mph 0;
BA_ "GenSigTimeoutTime_TCM" SG_ 1474 TSI_Offset_Mph 0;
BA_ "GenSigSendType" SG_ 1474 TurnSignalView 4;
BA_ "GenSigTimeoutTime_AGSM" SG_ 1474 TurnSignalView 0;
BA_ "GenSigTimeoutTime_BSM" SG_ 1474 TurnSignalView 0;
BA_ "GenSigTimeoutTime_CADM" SG_ 1474 TurnSignalView 0;
BA_ "GenSigTimeoutTime_DMSM" SG_ 1474 TurnSignalView 0;
BA_ "GenSigTimeoutTime_DTCM" SG_ 1474 TurnSignalView 0;
BA_ "GenSigTimeoutTime_ECM" SG_ 1474 TurnSignalView 0;
BA_ "GenSigTimeoutTime_EVCU2" SG_ 1474 TurnSignalView 0;
BA_ "GenSigTimeoutTime_GNMM" SG_ 1474 TurnSignalView 0;
BA_ "GenSigTimeoutTime_HCP" SG_ 1474 TurnSignalView 0;
BA_ "GenSigTimeoutTime_IPC" SG_ 1474 TurnSignalView 0;
BA_ "GenSigTimeoutTime_RFHM" SG_ 1474 TurnSignalView 0;
BA_ "GenSigTimeoutTime_TCM" SG_ 1474 TurnSignalView 0;
BA_ "GenSigStartValue" SG_ 1474 WorksiteINVM_Audible_LFW 1;
BA_ "GenSigSendType" SG_ 1474 WorksiteINVM_Audible_LFW 4;
BA_ "GenSigTimeoutTime_AGSM" SG_ 1474 WorksiteINVM_Audible_LFW 0;
BA_ "GenSigTimeoutTime_BSM" SG_ 1474 WorksiteINVM_Audible_LFW 0;
BA_ "GenSigTimeoutTime_CADM" SG_ 1474 WorksiteINVM_Audible_LFW 0;
BA_ "GenSigTimeoutTime_DMSM" SG_ 1474 WorksiteINVM_Audible_LFW 0;
BA_ "GenSigTimeoutTime_DTCM" SG_ 1474 WorksiteINVM_Audible_LFW 0;
BA_ "GenSigTimeoutTime_ECM" SG_ 1474 WorksiteINVM_Audible_LFW 0;
BA_ "GenSigTimeoutTime_EVCU2" SG_ 1474 WorksiteINVM_Audible_LFW 0;
BA_ "GenSigTimeoutTime_GNMM" SG_ 1474 WorksiteINVM_Audible_LFW 0;
BA_ "GenSigTimeoutTime_HCP" SG_ 1474 WorksiteINVM_Audible_LFW 0;
BA_ "GenSigTimeoutTime_IPC" SG_ 1474 WorksiteINVM_Audible_LFW 0;
BA_ "GenSigTimeoutTime_RFHM" SG_ 1474 WorksiteINVM_Audible_LFW 0;
BA_ "GenSigTimeoutTime_TCM" SG_ 1474 WorksiteINVM_Audible_LFW 0;
BA_ "GenSigStartValue" SG_ 1474 WorksiteINVM_Visual_LFW 1;
BA_ "GenSigSendType" SG_ 1474 WorksiteINVM_Visual_LFW 4;
BA_ "GenSigTimeoutTime_AGSM" SG_ 1474 WorksiteINVM_Visual_LFW 0;
BA_ "GenSigTimeoutTime_BSM" SG_ 1474 WorksiteINVM_Visual_LFW 0;
BA_ "GenSigTimeoutTime_CADM" SG_ 1474 WorksiteINVM_Visual_LFW 0;
BA_ "GenSigTimeoutTime_DMSM" SG_ 1474 WorksiteINVM_Visual_LFW 0;
BA_ "GenSigTimeoutTime_DTCM" SG_ 1474 WorksiteINVM_Visual_LFW 0;
BA_ "GenSigTimeoutTime_ECM" SG_ 1474 WorksiteINVM_Visual_LFW 0;
BA_ "GenSigTimeoutTime_EVCU2" SG_ 1474 WorksiteINVM_Visual_LFW 0;
BA_ "GenSigTimeoutTime_GNMM" SG_ 1474 WorksiteINVM_Visual_LFW 0;
BA_ "GenSigTimeoutTime_HCP" SG_ 1474 WorksiteINVM_Visual_LFW 0;
BA_ "GenSigTimeoutTime_IPC" SG_ 1474 WorksiteINVM_Visual_LFW 0;
BA_ "GenSigTimeoutTime_RFHM" SG_ 1474 WorksiteINVM_Visual_LFW 0;
BA_ "GenSigTimeoutTime_TCM" SG_ 1474 WorksiteINVM_Visual_LFW 0;
BA_ "GenSigTimeoutTime_AGSM" SG_ 753 CRC_LV_CHARGER1 0;
BA_ "GenSigTimeoutTime_BCM" SG_ 753 CRC_LV_CHARGER1 0;
BA_ "GenSigTimeoutTime_BSM" SG_ 753 CRC_LV_CHARGER1 0;
BA_ "GenSigTimeoutTime_CADM" SG_ 753 CRC_LV_CHARGER1 0;
BA_ "GenSigTimeoutTime_DMSM" SG_ 753 CRC_LV_CHARGER1 0;
BA_ "GenSigTimeoutTime_DTCM" SG_ 753 CRC_LV_CHARGER1 0;
BA_ "GenSigTimeoutTime_EVCU2" SG_ 753 CRC_LV_CHARGER1 0;
BA_ "GenSigTimeoutTime_GNMM" SG_ 753 CRC_LV_CHARGER1 0;
BA_ "GenSigTimeoutTime_HCP" SG_ 753 CRC_LV_CHARGER1 0;
BA_ "GenSigTimeoutTime_IPC" SG_ 753 CRC_LV_CHARGER1 0;
BA_ "GenSigTimeoutTime_RFHM" SG_ 753 CRC_LV_CHARGER1 0;
BA_ "GenSigTimeoutTime_SGW" SG_ 753 CRC_LV_CHARGER1 0;
BA_ "GenSigTimeoutTime_TCM" SG_ 753 CRC_LV_CHARGER1 0;
BA_ "GenSigTimeoutTime_AGSM" SG_ 753 DCDC_OperationModeSts 0;
BA_ "GenSigTimeoutTime_BCM" SG_ 753 DCDC_OperationModeSts 0;
BA_ "GenSigTimeoutTime_BSM" SG_ 753 DCDC_OperationModeSts 0;
BA_ "GenSigTimeoutTime_CADM" SG_ 753 DCDC_OperationModeSts 0;
BA_ "GenSigTimeoutTime_DMSM" SG_ 753 DCDC_OperationModeSts 0;
BA_ "GenSigTimeoutTime_DTCM" SG_ 753 DCDC_OperationModeSts 0;
BA_ "GenSigTimeoutTime_EVCU2" SG_ 753 DCDC_OperationModeSts 0;
BA_ "GenSigTimeoutTime_GNMM" SG_ 753 DCDC_OperationModeSts 0;
BA_ "GenSigTimeoutTime_HCP" SG_ 753 DCDC_OperationModeSts 0;
BA_ "GenSigTimeoutTime_IPC" SG_ 753 DCDC_OperationModeSts 0;
BA_ "GenSigTimeoutTime_RFHM" SG_ 753 DCDC_OperationModeSts 0;
BA_ "GenSigTimeoutTime_TCM" SG_ 753 DCDC_OperationModeSts 0;
BA_ "GenSigStartValue" SG_ 753 HVDC_CurrentFeedback 1021;
BA_ "GenSigTimeoutTime_AGSM" SG_ 753 HVDC_CurrentFeedback 0;
BA_ "GenSigTimeoutTime_BCM" SG_ 753 HVDC_CurrentFeedback 0;
BA_ "GenSigTimeoutTime_BSM" SG_ 753 HVDC_CurrentFeedback 0;
BA_ "GenSigTimeoutTime_CADM" SG_ 753 HVDC_CurrentFeedback 0;
BA_ "GenSigTimeoutTime_DMSM" SG_ 753 HVDC_CurrentFeedback 0;
BA_ "GenSigTimeoutTime_DTCM" SG_ 753 HVDC_CurrentFeedback 0;
BA_ "GenSigTimeoutTime_EVCU2" SG_ 753 HVDC_CurrentFeedback 0;
BA_ "GenSigTimeoutTime_GNMM" SG_ 753 HVDC_CurrentFeedback 0;
BA_ "GenSigTimeoutTime_HCP" SG_ 753 HVDC_CurrentFeedback 0;
BA_ "GenSigTimeoutTime_IPC" SG_ 753 HVDC_CurrentFeedback 0;
BA_ "GenSigTimeoutTime_RFHM" SG_ 753 HVDC_CurrentFeedback 0;
BA_ "GenSigTimeoutTime_SGW" SG_ 753 HVDC_CurrentFeedback 0;
BA_ "GenSigTimeoutTime_TCM" SG_ 753 HVDC_CurrentFeedback 0;
BA_ "GenSigTimeoutTime_AGSM" SG_ 753 HVDC_VoltageFeedback 0;
BA_ "GenSigTimeoutTime_BCM" SG_ 753 HVDC_VoltageFeedback 0;
BA_ "GenSigTimeoutTime_BSM" SG_ 753 HVDC_VoltageFeedback 0;
BA_ "GenSigTimeoutTime_CADM" SG_ 753 HVDC_VoltageFeedback 0;
BA_ "GenSigTimeoutTime_DMSM" SG_ 753 HVDC_VoltageFeedback 0;
BA_ "GenSigTimeoutTime_DTCM" SG_ 753 HVDC_VoltageFeedback 0;
BA_ "GenSigTimeoutTime_EVCU2" SG_ 753 HVDC_VoltageFeedback 0;
BA_ "GenSigTimeoutTime_GNMM" SG_ 753 HVDC_VoltageFeedback 0;
BA_ "GenSigTimeoutTime_HCP" SG_ 753 HVDC_VoltageFeedback 0;
BA_ "GenSigTimeoutTime_IPC" SG_ 753 HVDC_VoltageFeedback 0;
BA_ "GenSigTimeoutTime_RFHM" SG_ 753 HVDC_VoltageFeedback 0;
BA_ "GenSigTimeoutTime_SGW" SG_ 753 HVDC_VoltageFeedback 0;
BA_ "GenSigTimeoutTime_TCM" SG_ 753 HVDC_VoltageFeedback 0;
BA_ "GenSigStartValue" SG_ 753 LVDC_CurrentFeedback 4095;
BA_ "GenSigTimeoutTime_AGSM" SG_ 753 LVDC_CurrentFeedback 0;
BA_ "GenSigTimeoutTime_BCM" SG_ 753 LVDC_CurrentFeedback 0;
BA_ "GenSigTimeoutTime_BSM" SG_ 753 LVDC_CurrentFeedback 0;
BA_ "GenSigTimeoutTime_CADM" SG_ 753 LVDC_CurrentFeedback 0;
BA_ "GenSigTimeoutTime_DMSM" SG_ 753 LVDC_CurrentFeedback 0;
BA_ "GenSigTimeoutTime_DTCM" SG_ 753 LVDC_CurrentFeedback 0;
BA_ "GenSigTimeoutTime_EVCU2" SG_ 753 LVDC_CurrentFeedback 0;
BA_ "GenSigTimeoutTime_GNMM" SG_ 753 LVDC_CurrentFeedback 0;
BA_ "GenSigTimeoutTime_HCP" SG_ 753 LVDC_CurrentFeedback 0;
BA_ "GenSigTimeoutTime_IPC" SG_ 753 LVDC_CurrentFeedback 0;
BA_ "GenSigTimeoutTime_RFHM" SG_ 753 LVDC_CurrentFeedback 0;
BA_ "GenSigTimeoutTime_SGW" SG_ 753 LVDC_CurrentFeedback 0;
BA_ "GenSigTimeoutTime_TCM" SG_ 753 LVDC_CurrentFeedback 0;
BA_ "GenSigTimeoutTime_AGSM" SG_ 753 MessageCounter_LV_CHARGER1 0;
BA_ "GenSigTimeoutTime_BCM" SG_ 753 MessageCounter_LV_CHARGER1 0;
BA_ "GenSigTimeoutTime_BSM" SG_ 753 MessageCounter_LV_CHARGER1 0;
BA_ "GenSigTimeoutTime_CADM" SG_ 753 MessageCounter_LV_CHARGER1 0;
BA_ "GenSigTimeoutTime_DMSM" SG_ 753 MessageCounter_LV_CHARGER1 0;
BA_ "GenSigTimeoutTime_DTCM" SG_ 753 MessageCounter_LV_CHARGER1 0;
BA_ "GenSigTimeoutTime_EVCU2" SG_ 753 MessageCounter_LV_CHARGER1 0;
BA_ "GenSigTimeoutTime_GNMM" SG_ 753 MessageCounter_LV_CHARGER1 0;
BA_ "GenSigTimeoutTime_HCP" SG_ 753 MessageCounter_LV_CHARGER1 0;
BA_ "GenSigTimeoutTime_IPC" SG_ 753 MessageCounter_LV_CHARGER1 0;
BA_ "GenSigTimeoutTime_RFHM" SG_ 753 MessageCounter_LV_CHARGER1 0;
BA_ "GenSigTimeoutTime_SGW" SG_ 753 MessageCounter_LV_CHARGER1 0;
BA_ "GenSigTimeoutTime_TCM" SG_ 753 MessageCounter_LV_CHARGER1 0;
BA_ "GenSigSendType" SG_ 125 MESS_TTPM1 1;
BA_ "GenSigTimeoutTime_AGSM" SG_ 125 MESS_TTPM1 0;
BA_ "GenSigTimeoutTime_BCM" SG_ 125 MESS_TTPM1 0;
BA_ "GenSigTimeoutTime_BSM" SG_ 125 MESS_TTPM1 0;
BA_ "GenSigTimeoutTime_CADM" SG_ 125 MESS_TTPM1 0;
BA_ "GenSigTimeoutTime_DMSM" SG_ 125 MESS_TTPM1 0;
BA_ "GenSigTimeoutTime_DTCM" SG_ 125 MESS_TTPM1 0;
BA_ "GenSigTimeoutTime_ECM" SG_ 125 MESS_TTPM1 0;
BA_ "GenSigTimeoutTime_EVCU2" SG_ 125 MESS_TTPM1 0;
BA_ "GenSigTimeoutTime_GNMM" SG_ 125 MESS_TTPM1 0;
BA_ "GenSigTimeoutTime_HCP" SG_ 125 MESS_TTPM1 0;
BA_ "GenSigTimeoutTime_IPC" SG_ 125 MESS_TTPM1 0;
BA_ "GenSigTimeoutTime_RFHM" SG_ 125 MESS_TTPM1 0;
BA_ "GenSigTimeoutTime_TCM" SG_ 125 MESS_TTPM1 0;
BA_ "GenSigTimeoutTime_AGSM" SG_ 2654486550 CBV_bit0_RepeatMessageRequestBit 0;
BA_ "GenSigTimeoutTime_BCM" SG_ 2654486550 CBV_bit0_RepeatMessageRequestBit 0;
BA_ "GenSigTimeoutTime_BSM" SG_ 2654486550 CBV_bit0_RepeatMessageRequestBit 0;
BA_ "GenSigTimeoutTime_CADM" SG_ 2654486550 CBV_bit0_RepeatMessageRequestBit 0;
BA_ "GenSigTimeoutTime_DMSM" SG_ 2654486550 CBV_bit0_RepeatMessageRequestBit 0;
BA_ "GenSigTimeoutTime_DTCM" SG_ 2654486550 CBV_bit0_RepeatMessageRequestBit 0;
BA_ "GenSigTimeoutTime_ECM" SG_ 2654486550 CBV_bit0_RepeatMessageRequestBit 0;
BA_ "GenSigTimeoutTime_EVCU2" SG_ 2654486550 CBV_bit0_RepeatMessageRequestBit 0;
BA_ "GenSigTimeoutTime_GNMM" SG_ 2654486550 CBV_bit0_RepeatMessageRequestBit 0;
BA_ "GenSigTimeoutTime_HCP" SG_ 2654486550 CBV_bit0_RepeatMessageRequestBit 0;
BA_ "GenSigTimeoutTime_IPC" SG_ 2654486550 CBV_bit0_RepeatMessageRequestBit 0;
BA_ "GenSigTimeoutTime_RFHM" SG_ 2654486550 CBV_bit0_RepeatMessageRequestBit 0;
BA_ "GenSigTimeoutTime_SGW" SG_ 2654486550 CBV_bit0_RepeatMessageRequestBit 0;
BA_ "GenSigTimeoutTime_TCM" SG_ 2654486550 CBV_bit0_RepeatMessageRequestBit 0;
BA_ "GenSigTimeoutTime_AGSM" SG_ 2654486550 CBV_bit1 0;
BA_ "GenSigTimeoutTime_BCM" SG_ 2654486550 CBV_bit1 0;
BA_ "GenSigTimeoutTime_BSM" SG_ 2654486550 CBV_bit1 0;
BA_ "GenSigTimeoutTime_CADM" SG_ 2654486550 CBV_bit1 0;
BA_ "GenSigTimeoutTime_DMSM" SG_ 2654486550 CBV_bit1 0;
BA_ "GenSigTimeoutTime_DTCM" SG_ 2654486550 CBV_bit1 0;
BA_ "GenSigTimeoutTime_ECM" SG_ 2654486550 CBV_bit1 0;
BA_ "GenSigTimeoutTime_EVCU2" SG_ 2654486550 CBV_bit1 0;
BA_ "GenSigTimeoutTime_GNMM" SG_ 2654486550 CBV_bit1 0;
BA_ "GenSigTimeoutTime_HCP" SG_ 2654486550 CBV_bit1 0;
BA_ "GenSigTimeoutTime_IPC" SG_ 2654486550 CBV_bit1 0;
BA_ "GenSigTimeoutTime_RFHM" SG_ 2654486550 CBV_bit1 0;
BA_ "GenSigTimeoutTime_SGW" SG_ 2654486550 CBV_bit1 0;
BA_ "GenSigTimeoutTime_TCM" SG_ 2654486550 CBV_bit1 0;
BA_ "GenSigTimeoutTime_AGSM" SG_ 2654486550 CBV_bit2 0;
BA_ "GenSigTimeoutTime_BCM" SG_ 2654486550 CBV_bit2 0;
BA_ "GenSigTimeoutTime_BSM" SG_ 2654486550 CBV_bit2 0;
BA_ "GenSigTimeoutTime_CADM" SG_ 2654486550 CBV_bit2 0;
BA_ "GenSigTimeoutTime_DMSM" SG_ 2654486550 CBV_bit2 0;
BA_ "GenSigTimeoutTime_DTCM" SG_ 2654486550 CBV_bit2 0;
BA_ "GenSigTimeoutTime_ECM" SG_ 2654486550 CBV_bit2 0;
BA_ "GenSigTimeoutTime_EVCU2" SG_ 2654486550 CBV_bit2 0;
BA_ "GenSigTimeoutTime_GNMM" SG_ 2654486550 CBV_bit2 0;
BA_ "GenSigTimeoutTime_HCP" SG_ 2654486550 CBV_bit2 0;
BA_ "GenSigTimeoutTime_IPC" SG_ 2654486550 CBV_bit2 0;
BA_ "GenSigTimeoutTime_RFHM" SG_ 2654486550 CBV_bit2 0;
BA_ "GenSigTimeoutTime_SGW" SG_ 2654486550 CBV_bit2 0;
BA_ "GenSigTimeoutTime_TCM" SG_ 2654486550 CBV_bit2 0;
BA_ "GenSigTimeoutTime_AGSM" SG_ 2654486550 CBV_bit3_NMCoordinatorBit 0;
BA_ "GenSigTimeoutTime_BCM" SG_ 2654486550 CBV_bit3_NMCoordinatorBit 0;
BA_ "GenSigTimeoutTime_BSM" SG_ 2654486550 CBV_bit3_NMCoordinatorBit 0;
BA_ "GenSigTimeoutTime_CADM" SG_ 2654486550 CBV_bit3_NMCoordinatorBit 0;
BA_ "GenSigTimeoutTime_DMSM" SG_ 2654486550 CBV_bit3_NMCoordinatorBit 0;
BA_ "GenSigTimeoutTime_DTCM" SG_ 2654486550 CBV_bit3_NMCoordinatorBit 0;
BA_ "GenSigTimeoutTime_ECM" SG_ 2654486550 CBV_bit3_NMCoordinatorBit 0;
BA_ "GenSigTimeoutTime_EVCU2" SG_ 2654486550 CBV_bit3_NMCoordinatorBit 0;
BA_ "GenSigTimeoutTime_GNMM" SG_ 2654486550 CBV_bit3_NMCoordinatorBit 0;
BA_ "GenSigTimeoutTime_HCP" SG_ 2654486550 CBV_bit3_NMCoordinatorBit 0;
BA_ "GenSigTimeoutTime_IPC" SG_ 2654486550 CBV_bit3_NMCoordinatorBit 0;
BA_ "GenSigTimeoutTime_RFHM" SG_ 2654486550 CBV_bit3_NMCoordinatorBit 0;
BA_ "GenSigTimeoutTime_SGW" SG_ 2654486550 CBV_bit3_NMCoordinatorBit 0;
BA_ "GenSigTimeoutTime_TCM" SG_ 2654486550 CBV_bit3_NMCoordinatorBit 0;
BA_ "GenSigTimeoutTime_AGSM" SG_ 2654486550 CBV_bit4_ActiveWakeupBit 0;
BA_ "GenSigTimeoutTime_BCM" SG_ 2654486550 CBV_bit4_ActiveWakeupBit 0;
BA_ "GenSigTimeoutTime_BSM" SG_ 2654486550 CBV_bit4_ActiveWakeupBit 0;
BA_ "GenSigTimeoutTime_CADM" SG_ 2654486550 CBV_bit4_ActiveWakeupBit 0;
BA_ "GenSigTimeoutTime_DMSM" SG_ 2654486550 CBV_bit4_ActiveWakeupBit 0;
BA_ "GenSigTimeoutTime_DTCM" SG_ 2654486550 CBV_bit4_ActiveWakeupBit 0;
BA_ "GenSigTimeoutTime_ECM" SG_ 2654486550 CBV_bit4_ActiveWakeupBit 0;
BA_ "GenSigTimeoutTime_EVCU2" SG_ 2654486550 CBV_bit4_ActiveWakeupBit 0;
BA_ "GenSigTimeoutTime_GNMM" SG_ 2654486550 CBV_bit4_ActiveWakeupBit 0;
BA_ "GenSigTimeoutTime_HCP" SG_ 2654486550 CBV_bit4_ActiveWakeupBit 0;
BA_ "GenSigTimeoutTime_IPC" SG_ 2654486550 CBV_bit4_ActiveWakeupBit 0;
BA_ "GenSigTimeoutTime_RFHM" SG_ 2654486550 CBV_bit4_ActiveWakeupBit 0;
BA_ "GenSigTimeoutTime_SGW" SG_ 2654486550 CBV_bit4_ActiveWakeupBit 0;
BA_ "GenSigTimeoutTime_TCM" SG_ 2654486550 CBV_bit4_ActiveWakeupBit 0;
BA_ "GenSigTimeoutTime_AGSM" SG_ 2654486550 CBV_bit5 0;
BA_ "GenSigTimeoutTime_BCM" SG_ 2654486550 CBV_bit5 0;
BA_ "GenSigTimeoutTime_BSM" SG_ 2654486550 CBV_bit5 0;
BA_ "GenSigTimeoutTime_CADM" SG_ 2654486550 CBV_bit5 0;
BA_ "GenSigTimeoutTime_DMSM" SG_ 2654486550 CBV_bit5 0;
BA_ "GenSigTimeoutTime_DTCM" SG_ 2654486550 CBV_bit5 0;
BA_ "GenSigTimeoutTime_ECM" SG_ 2654486550 CBV_bit5 0;
BA_ "GenSigTimeoutTime_EVCU2" SG_ 2654486550 CBV_bit5 0;
BA_ "GenSigTimeoutTime_GNMM" SG_ 2654486550 CBV_bit5 0;
BA_ "GenSigTimeoutTime_HCP" SG_ 2654486550 CBV_bit5 0;
BA_ "GenSigTimeoutTime_IPC" SG_ 2654486550 CBV_bit5 0;
BA_ "GenSigTimeoutTime_RFHM" SG_ 2654486550 CBV_bit5 0;
BA_ "GenSigTimeoutTime_SGW" SG_ 2654486550 CBV_bit5 0;
BA_ "GenSigTimeoutTime_TCM" SG_ 2654486550 CBV_bit5 0;
BA_ "GenSigTimeoutTime_AGSM" SG_ 2654486550 CBV_bit6_PartialNtwInfBit 0;
BA_ "GenSigTimeoutTime_BCM" SG_ 2654486550 CBV_bit6_PartialNtwInfBit 0;
BA_ "GenSigTimeoutTime_BSM" SG_ 2654486550 CBV_bit6_PartialNtwInfBit 0;
BA_ "GenSigTimeoutTime_CADM" SG_ 2654486550 CBV_bit6_PartialNtwInfBit 0;
BA_ "GenSigTimeoutTime_DMSM" SG_ 2654486550 CBV_bit6_PartialNtwInfBit 0;
BA_ "GenSigTimeoutTime_DTCM" SG_ 2654486550 CBV_bit6_PartialNtwInfBit 0;
BA_ "GenSigTimeoutTime_ECM" SG_ 2654486550 CBV_bit6_PartialNtwInfBit 0;
BA_ "GenSigTimeoutTime_EVCU2" SG_ 2654486550 CBV_bit6_PartialNtwInfBit 0;
BA_ "GenSigTimeoutTime_GNMM" SG_ 2654486550 CBV_bit6_PartialNtwInfBit 0;
BA_ "GenSigTimeoutTime_HCP" SG_ 2654486550 CBV_bit6_PartialNtwInfBit 0;
BA_ "GenSigTimeoutTime_IPC" SG_ 2654486550 CBV_bit6_PartialNtwInfBit 0;
BA_ "GenSigTimeoutTime_RFHM" SG_ 2654486550 CBV_bit6_PartialNtwInfBit 0;
BA_ "GenSigTimeoutTime_SGW" SG_ 2654486550 CBV_bit6_PartialNtwInfBit 0;
BA_ "GenSigTimeoutTime_TCM" SG_ 2654486550 CBV_bit6_PartialNtwInfBit 0;
BA_ "GenSigTimeoutTime_AGSM" SG_ 2654486550 CBV_bit7 0;
BA_ "GenSigTimeoutTime_BCM" SG_ 2654486550 CBV_bit7 0;
BA_ "GenSigTimeoutTime_BSM" SG_ 2654486550 CBV_bit7 0;
BA_ "GenSigTimeoutTime_CADM" SG_ 2654486550 CBV_bit7 0;
BA_ "GenSigTimeoutTime_DMSM" SG_ 2654486550 CBV_bit7 0;
BA_ "GenSigTimeoutTime_DTCM" SG_ 2654486550 CBV_bit7 0;
BA_ "GenSigTimeoutTime_ECM" SG_ 2654486550 CBV_bit7 0;
BA_ "GenSigTimeoutTime_EVCU2" SG_ 2654486550 CBV_bit7 0;
BA_ "GenSigTimeoutTime_GNMM" SG_ 2654486550 CBV_bit7 0;
BA_ "GenSigTimeoutTime_HCP" SG_ 2654486550 CBV_bit7 0;
BA_ "GenSigTimeoutTime_IPC" SG_ 2654486550 CBV_bit7 0;
BA_ "GenSigTimeoutTime_RFHM" SG_ 2654486550 CBV_bit7 0;
BA_ "GenSigTimeoutTime_SGW" SG_ 2654486550 CBV_bit7 0;
BA_ "GenSigTimeoutTime_TCM" SG_ 2654486550 CBV_bit7 0;
BA_ "GenSigTimeoutTime_AGSM" SG_ 2654486550 SourceNodeIdentifier 0;
BA_ "GenSigTimeoutTime_BCM" SG_ 2654486550 SourceNodeIdentifier 0;
BA_ "GenSigTimeoutTime_BSM" SG_ 2654486550 SourceNodeIdentifier 0;
BA_ "GenSigTimeoutTime_CADM" SG_ 2654486550 SourceNodeIdentifier 0;
BA_ "GenSigTimeoutTime_DMSM" SG_ 2654486550 SourceNodeIdentifier 0;
BA_ "GenSigTimeoutTime_DTCM" SG_ 2654486550 SourceNodeIdentifier 0;
BA_ "GenSigTimeoutTime_ECM" SG_ 2654486550 SourceNodeIdentifier 0;
BA_ "GenSigTimeoutTime_EVCU2" SG_ 2654486550 SourceNodeIdentifier 0;
BA_ "GenSigTimeoutTime_GNMM" SG_ 2654486550 SourceNodeIdentifier 0;
BA_ "GenSigTimeoutTime_HCP" SG_ 2654486550 SourceNodeIdentifier 0;
BA_ "GenSigTimeoutTime_IPC" SG_ 2654486550 SourceNodeIdentifier 0;
BA_ "GenSigTimeoutTime_RFHM" SG_ 2654486550 SourceNodeIdentifier 0;
BA_ "GenSigTimeoutTime_SGW" SG_ 2654486550 SourceNodeIdentifier 0;
BA_ "GenSigTimeoutTime_TCM" SG_ 2654486550 SourceNodeIdentifier 0;
BA_ "GenSigTimeoutTime_AGSM" SG_ 2654486528 CBV_bit0_RepeatMessageRequestBit 0;
BA_ "GenSigTimeoutTime_BCM" SG_ 2654486528 CBV_bit0_RepeatMessageRequestBit 0;
BA_ "GenSigTimeoutTime_BSM" SG_ 2654486528 CBV_bit0_RepeatMessageRequestBit 0;
BA_ "GenSigTimeoutTime_CADM" SG_ 2654486528 CBV_bit0_RepeatMessageRequestBit 0;
BA_ "GenSigTimeoutTime_DMSM" SG_ 2654486528 CBV_bit0_RepeatMessageRequestBit 0;
BA_ "GenSigTimeoutTime_DTCM" SG_ 2654486528 CBV_bit0_RepeatMessageRequestBit 0;
BA_ "GenSigTimeoutTime_ECM" SG_ 2654486528 CBV_bit0_RepeatMessageRequestBit 0;
BA_ "GenSigTimeoutTime_EVCU2" SG_ 2654486528 CBV_bit0_RepeatMessageRequestBit 0;
BA_ "GenSigTimeoutTime_GNMM" SG_ 2654486528 CBV_bit0_RepeatMessageRequestBit 0;
BA_ "GenSigTimeoutTime_HCP" SG_ 2654486528 CBV_bit0_RepeatMessageRequestBit 0;
BA_ "GenSigTimeoutTime_IPC" SG_ 2654486528 CBV_bit0_RepeatMessageRequestBit 0;
BA_ "GenSigTimeoutTime_RFHM" SG_ 2654486528 CBV_bit0_RepeatMessageRequestBit 0;
BA_ "GenSigTimeoutTime_SGW" SG_ 2654486528 CBV_bit0_RepeatMessageRequestBit 0;
BA_ "GenSigTimeoutTime_TCM" SG_ 2654486528 CBV_bit0_RepeatMessageRequestBit 0;
BA_ "GenSigTimeoutTime_AGSM" SG_ 2654486528 CBV_bit1 0;
BA_ "GenSigTimeoutTime_BCM" SG_ 2654486528 CBV_bit1 0;
BA_ "GenSigTimeoutTime_BSM" SG_ 2654486528 CBV_bit1 0;
BA_ "GenSigTimeoutTime_CADM" SG_ 2654486528 CBV_bit1 0;
BA_ "GenSigTimeoutTime_DMSM" SG_ 2654486528 CBV_bit1 0;
BA_ "GenSigTimeoutTime_DTCM" SG_ 2654486528 CBV_bit1 0;
BA_ "GenSigTimeoutTime_ECM" SG_ 2654486528 CBV_bit1 0;
BA_ "GenSigTimeoutTime_EVCU2" SG_ 2654486528 CBV_bit1 0;
BA_ "GenSigTimeoutTime_GNMM" SG_ 2654486528 CBV_bit1 0;
BA_ "GenSigTimeoutTime_HCP" SG_ 2654486528 CBV_bit1 0;
BA_ "GenSigTimeoutTime_IPC" SG_ 2654486528 CBV_bit1 0;
BA_ "GenSigTimeoutTime_RFHM" SG_ 2654486528 CBV_bit1 0;
BA_ "GenSigTimeoutTime_SGW" SG_ 2654486528 CBV_bit1 0;
BA_ "GenSigTimeoutTime_TCM" SG_ 2654486528 CBV_bit1 0;
BA_ "GenSigTimeoutTime_AGSM" SG_ 2654486528 CBV_bit2 0;
BA_ "GenSigTimeoutTime_BCM" SG_ 2654486528 CBV_bit2 0;
BA_ "GenSigTimeoutTime_BSM" SG_ 2654486528 CBV_bit2 0;
BA_ "GenSigTimeoutTime_CADM" SG_ 2654486528 CBV_bit2 0;
BA_ "GenSigTimeoutTime_DMSM" SG_ 2654486528 CBV_bit2 0;
BA_ "GenSigTimeoutTime_DTCM" SG_ 2654486528 CBV_bit2 0;
BA_ "GenSigTimeoutTime_ECM" SG_ 2654486528 CBV_bit2 0;
BA_ "GenSigTimeoutTime_EVCU2" SG_ 2654486528 CBV_bit2 0;
BA_ "GenSigTimeoutTime_GNMM" SG_ 2654486528 CBV_bit2 0;
BA_ "GenSigTimeoutTime_HCP" SG_ 2654486528 CBV_bit2 0;
BA_ "GenSigTimeoutTime_IPC" SG_ 2654486528 CBV_bit2 0;
BA_ "GenSigTimeoutTime_RFHM" SG_ 2654486528 CBV_bit2 0;
BA_ "GenSigTimeoutTime_SGW" SG_ 2654486528 CBV_bit2 0;
BA_ "GenSigTimeoutTime_TCM" SG_ 2654486528 CBV_bit2 0;
BA_ "GenSigTimeoutTime_AGSM" SG_ 2654486528 CBV_bit3_NMCoordinatorBit 0;
BA_ "GenSigTimeoutTime_BCM" SG_ 2654486528 CBV_bit3_NMCoordinatorBit 0;
BA_ "GenSigTimeoutTime_BSM" SG_ 2654486528 CBV_bit3_NMCoordinatorBit 0;
BA_ "GenSigTimeoutTime_CADM" SG_ 2654486528 CBV_bit3_NMCoordinatorBit 0;
BA_ "GenSigTimeoutTime_DMSM" SG_ 2654486528 CBV_bit3_NMCoordinatorBit 0;
BA_ "GenSigTimeoutTime_DTCM" SG_ 2654486528 CBV_bit3_NMCoordinatorBit 0;
BA_ "GenSigTimeoutTime_ECM" SG_ 2654486528 CBV_bit3_NMCoordinatorBit 0;
BA_ "GenSigTimeoutTime_EVCU2" SG_ 2654486528 CBV_bit3_NMCoordinatorBit 0;
BA_ "GenSigTimeoutTime_GNMM" SG_ 2654486528 CBV_bit3_NMCoordinatorBit 0;
BA_ "GenSigTimeoutTime_HCP" SG_ 2654486528 CBV_bit3_NMCoordinatorBit 0;
BA_ "GenSigTimeoutTime_IPC" SG_ 2654486528 CBV_bit3_NMCoordinatorBit 0;
BA_ "GenSigTimeoutTime_RFHM" SG_ 2654486528 CBV_bit3_NMCoordinatorBit 0;
BA_ "GenSigTimeoutTime_SGW" SG_ 2654486528 CBV_bit3_NMCoordinatorBit 0;
BA_ "GenSigTimeoutTime_TCM" SG_ 2654486528 CBV_bit3_NMCoordinatorBit 0;
BA_ "GenSigTimeoutTime_AGSM" SG_ 2654486528 CBV_bit4_ActiveWakeupBit 0;
BA_ "GenSigTimeoutTime_BCM" SG_ 2654486528 CBV_bit4_ActiveWakeupBit 0;
BA_ "GenSigTimeoutTime_BSM" SG_ 2654486528 CBV_bit4_ActiveWakeupBit 0;
BA_ "GenSigTimeoutTime_CADM" SG_ 2654486528 CBV_bit4_ActiveWakeupBit 0;
BA_ "GenSigTimeoutTime_DMSM" SG_ 2654486528 CBV_bit4_ActiveWakeupBit 0;
BA_ "GenSigTimeoutTime_DTCM" SG_ 2654486528 CBV_bit4_ActiveWakeupBit 0;
BA_ "GenSigTimeoutTime_ECM" SG_ 2654486528 CBV_bit4_ActiveWakeupBit 0;
BA_ "GenSigTimeoutTime_EVCU2" SG_ 2654486528 CBV_bit4_ActiveWakeupBit 0;
BA_ "GenSigTimeoutTime_GNMM" SG_ 2654486528 CBV_bit4_ActiveWakeupBit 0;
BA_ "GenSigTimeoutTime_HCP" SG_ 2654486528 CBV_bit4_ActiveWakeupBit 0;
BA_ "GenSigTimeoutTime_IPC" SG_ 2654486528 CBV_bit4_ActiveWakeupBit 0;
BA_ "GenSigTimeoutTime_RFHM" SG_ 2654486528 CBV_bit4_ActiveWakeupBit 0;
BA_ "GenSigTimeoutTime_SGW" SG_ 2654486528 CBV_bit4_ActiveWakeupBit 0;
BA_ "GenSigTimeoutTime_TCM" SG_ 2654486528 CBV_bit4_ActiveWakeupBit 0;
BA_ "GenSigTimeoutTime_AGSM" SG_ 2654486528 CBV_bit5 0;
BA_ "GenSigTimeoutTime_BCM" SG_ 2654486528 CBV_bit5 0;
BA_ "GenSigTimeoutTime_BSM" SG_ 2654486528 CBV_bit5 0;
BA_ "GenSigTimeoutTime_CADM" SG_ 2654486528 CBV_bit5 0;
BA_ "GenSigTimeoutTime_DMSM" SG_ 2654486528 CBV_bit5 0;
BA_ "GenSigTimeoutTime_DTCM" SG_ 2654486528 CBV_bit5 0;
BA_ "GenSigTimeoutTime_ECM" SG_ 2654486528 CBV_bit5 0;
BA_ "GenSigTimeoutTime_EVCU2" SG_ 2654486528 CBV_bit5 0;
BA_ "GenSigTimeoutTime_GNMM" SG_ 2654486528 CBV_bit5 0;
BA_ "GenSigTimeoutTime_HCP" SG_ 2654486528 CBV_bit5 0;
BA_ "GenSigTimeoutTime_IPC" SG_ 2654486528 CBV_bit5 0;
BA_ "GenSigTimeoutTime_RFHM" SG_ 2654486528 CBV_bit5 0;
BA_ "GenSigTimeoutTime_SGW" SG_ 2654486528 CBV_bit5 0;
BA_ "GenSigTimeoutTime_TCM" SG_ 2654486528 CBV_bit5 0;
BA_ "GenSigTimeoutTime_AGSM" SG_ 2654486528 CBV_bit6_PartialNtwInfBit 0;
BA_ "GenSigTimeoutTime_BCM" SG_ 2654486528 CBV_bit6_PartialNtwInfBit 0;
BA_ "GenSigTimeoutTime_BSM" SG_ 2654486528 CBV_bit6_PartialNtwInfBit 0;
BA_ "GenSigTimeoutTime_CADM" SG_ 2654486528 CBV_bit6_PartialNtwInfBit 0;
BA_ "GenSigTimeoutTime_DMSM" SG_ 2654486528 CBV_bit6_PartialNtwInfBit 0;
BA_ "GenSigTimeoutTime_DTCM" SG_ 2654486528 CBV_bit6_PartialNtwInfBit 0;
BA_ "GenSigTimeoutTime_ECM" SG_ 2654486528 CBV_bit6_PartialNtwInfBit 0;
BA_ "GenSigTimeoutTime_EVCU2" SG_ 2654486528 CBV_bit6_PartialNtwInfBit 0;
BA_ "GenSigTimeoutTime_GNMM" SG_ 2654486528 CBV_bit6_PartialNtwInfBit 0;
BA_ "GenSigTimeoutTime_HCP" SG_ 2654486528 CBV_bit6_PartialNtwInfBit 0;
BA_ "GenSigTimeoutTime_IPC" SG_ 2654486528 CBV_bit6_PartialNtwInfBit 0;
BA_ "GenSigTimeoutTime_RFHM" SG_ 2654486528 CBV_bit6_PartialNtwInfBit 0;
BA_ "GenSigTimeoutTime_SGW" SG_ 2654486528 CBV_bit6_PartialNtwInfBit 0;
BA_ "GenSigTimeoutTime_TCM" SG_ 2654486528 CBV_bit6_PartialNtwInfBit 0;
BA_ "GenSigTimeoutTime_AGSM" SG_ 2654486528 CBV_bit7 0;
BA_ "GenSigTimeoutTime_BCM" SG_ 2654486528 CBV_bit7 0;
BA_ "GenSigTimeoutTime_BSM" SG_ 2654486528 CBV_bit7 0;
BA_ "GenSigTimeoutTime_CADM" SG_ 2654486528 CBV_bit7 0;
BA_ "GenSigTimeoutTime_DMSM" SG_ 2654486528 CBV_bit7 0;
BA_ "GenSigTimeoutTime_DTCM" SG_ 2654486528 CBV_bit7 0;
BA_ "GenSigTimeoutTime_ECM" SG_ 2654486528 CBV_bit7 0;
BA_ "GenSigTimeoutTime_EVCU2" SG_ 2654486528 CBV_bit7 0;
BA_ "GenSigTimeoutTime_GNMM" SG_ 2654486528 CBV_bit7 0;
BA_ "GenSigTimeoutTime_HCP" SG_ 2654486528 CBV_bit7 0;
BA_ "GenSigTimeoutTime_IPC" SG_ 2654486528 CBV_bit7 0;
BA_ "GenSigTimeoutTime_RFHM" SG_ 2654486528 CBV_bit7 0;
BA_ "GenSigTimeoutTime_SGW" SG_ 2654486528 CBV_bit7 0;
BA_ "GenSigTimeoutTime_TCM" SG_ 2654486528 CBV_bit7 0;
BA_ "GenSigTimeoutTime_AGSM" SG_ 2654486528 SourceNodeIdentifier 0;
BA_ "GenSigTimeoutTime_BCM" SG_ 2654486528 SourceNodeIdentifier 0;
BA_ "GenSigTimeoutTime_BSM" SG_ 2654486528 SourceNodeIdentifier 0;
BA_ "GenSigTimeoutTime_CADM" SG_ 2654486528 SourceNodeIdentifier 0;
BA_ "GenSigTimeoutTime_DMSM" SG_ 2654486528 SourceNodeIdentifier 0;
BA_ "GenSigTimeoutTime_DTCM" SG_ 2654486528 SourceNodeIdentifier 0;
BA_ "GenSigTimeoutTime_ECM" SG_ 2654486528 SourceNodeIdentifier 0;
BA_ "GenSigTimeoutTime_EVCU2" SG_ 2654486528 SourceNodeIdentifier 0;
BA_ "GenSigTimeoutTime_GNMM" SG_ 2654486528 SourceNodeIdentifier 0;
BA_ "GenSigTimeoutTime_HCP" SG_ 2654486528 SourceNodeIdentifier 0;
BA_ "GenSigTimeoutTime_IPC" SG_ 2654486528 SourceNodeIdentifier 0;
BA_ "GenSigTimeoutTime_RFHM" SG_ 2654486528 SourceNodeIdentifier 0;
BA_ "GenSigTimeoutTime_SGW" SG_ 2654486528 SourceNodeIdentifier 0;
BA_ "GenSigTimeoutTime_TCM" SG_ 2654486528 SourceNodeIdentifier 0;
BA_ "GenSigTimeoutTime_AGSM" SG_ 2654486534 CBV_bit0_RepeatMessageRequestBit 0;
BA_ "GenSigTimeoutTime_BCM" SG_ 2654486534 CBV_bit0_RepeatMessageRequestBit 0;
BA_ "GenSigTimeoutTime_BSM" SG_ 2654486534 CBV_bit0_RepeatMessageRequestBit 0;
BA_ "GenSigTimeoutTime_CADM" SG_ 2654486534 CBV_bit0_RepeatMessageRequestBit 0;
BA_ "GenSigTimeoutTime_DMSM" SG_ 2654486534 CBV_bit0_RepeatMessageRequestBit 0;
BA_ "GenSigTimeoutTime_DTCM" SG_ 2654486534 CBV_bit0_RepeatMessageRequestBit 0;
BA_ "GenSigTimeoutTime_ECM" SG_ 2654486534 CBV_bit0_RepeatMessageRequestBit 0;
BA_ "GenSigTimeoutTime_EVCU2" SG_ 2654486534 CBV_bit0_RepeatMessageRequestBit 0;
BA_ "GenSigTimeoutTime_GNMM" SG_ 2654486534 CBV_bit0_RepeatMessageRequestBit 0;
BA_ "GenSigTimeoutTime_HCP" SG_ 2654486534 CBV_bit0_RepeatMessageRequestBit 0;
BA_ "GenSigTimeoutTime_IPC" SG_ 2654486534 CBV_bit0_RepeatMessageRequestBit 0;
BA_ "GenSigTimeoutTime_RFHM" SG_ 2654486534 CBV_bit0_RepeatMessageRequestBit 0;
BA_ "GenSigTimeoutTime_SGW" SG_ 2654486534 CBV_bit0_RepeatMessageRequestBit 0;
BA_ "GenSigTimeoutTime_TCM" SG_ 2654486534 CBV_bit0_RepeatMessageRequestBit 0;
BA_ "GenSigTimeoutTime_AGSM" SG_ 2654486534 CBV_bit1 0;
BA_ "GenSigTimeoutTime_BCM" SG_ 2654486534 CBV_bit1 0;
BA_ "GenSigTimeoutTime_BSM" SG_ 2654486534 CBV_bit1 0;
BA_ "GenSigTimeoutTime_CADM" SG_ 2654486534 CBV_bit1 0;
BA_ "GenSigTimeoutTime_DMSM" SG_ 2654486534 CBV_bit1 0;
BA_ "GenSigTimeoutTime_DTCM" SG_ 2654486534 CBV_bit1 0;
BA_ "GenSigTimeoutTime_ECM" SG_ 2654486534 CBV_bit1 0;
BA_ "GenSigTimeoutTime_EVCU2" SG_ 2654486534 CBV_bit1 0;
BA_ "GenSigTimeoutTime_GNMM" SG_ 2654486534 CBV_bit1 0;
BA_ "GenSigTimeoutTime_HCP" SG_ 2654486534 CBV_bit1 0;
BA_ "GenSigTimeoutTime_IPC" SG_ 2654486534 CBV_bit1 0;
BA_ "GenSigTimeoutTime_RFHM" SG_ 2654486534 CBV_bit1 0;
BA_ "GenSigTimeoutTime_SGW" SG_ 2654486534 CBV_bit1 0;
BA_ "GenSigTimeoutTime_TCM" SG_ 2654486534 CBV_bit1 0;
BA_ "GenSigTimeoutTime_AGSM" SG_ 2654486534 CBV_bit2 0;
BA_ "GenSigTimeoutTime_BCM" SG_ 2654486534 CBV_bit2 0;
BA_ "GenSigTimeoutTime_BSM" SG_ 2654486534 CBV_bit2 0;
BA_ "GenSigTimeoutTime_CADM" SG_ 2654486534 CBV_bit2 0;
BA_ "GenSigTimeoutTime_DMSM" SG_ 2654486534 CBV_bit2 0;
BA_ "GenSigTimeoutTime_DTCM" SG_ 2654486534 CBV_bit2 0;
BA_ "GenSigTimeoutTime_ECM" SG_ 2654486534 CBV_bit2 0;
BA_ "GenSigTimeoutTime_EVCU2" SG_ 2654486534 CBV_bit2 0;
BA_ "GenSigTimeoutTime_GNMM" SG_ 2654486534 CBV_bit2 0;
BA_ "GenSigTimeoutTime_HCP" SG_ 2654486534 CBV_bit2 0;
BA_ "GenSigTimeoutTime_IPC" SG_ 2654486534 CBV_bit2 0;
BA_ "GenSigTimeoutTime_RFHM" SG_ 2654486534 CBV_bit2 0;
BA_ "GenSigTimeoutTime_SGW" SG_ 2654486534 CBV_bit2 0;
BA_ "GenSigTimeoutTime_TCM" SG_ 2654486534 CBV_bit2 0;
BA_ "GenSigTimeoutTime_AGSM" SG_ 2654486534 CBV_bit3_NMCoordinatorBit 0;
BA_ "GenSigTimeoutTime_BCM" SG_ 2654486534 CBV_bit3_NMCoordinatorBit 0;
BA_ "GenSigTimeoutTime_BSM" SG_ 2654486534 CBV_bit3_NMCoordinatorBit 0;
BA_ "GenSigTimeoutTime_CADM" SG_ 2654486534 CBV_bit3_NMCoordinatorBit 0;
BA_ "GenSigTimeoutTime_DMSM" SG_ 2654486534 CBV_bit3_NMCoordinatorBit 0;
BA_ "GenSigTimeoutTime_DTCM" SG_ 2654486534 CBV_bit3_NMCoordinatorBit 0;
BA_ "GenSigTimeoutTime_ECM" SG_ 2654486534 CBV_bit3_NMCoordinatorBit 0;
BA_ "GenSigTimeoutTime_EVCU2" SG_ 2654486534 CBV_bit3_NMCoordinatorBit 0;
BA_ "GenSigTimeoutTime_GNMM" SG_ 2654486534 CBV_bit3_NMCoordinatorBit 0;
BA_ "GenSigTimeoutTime_HCP" SG_ 2654486534 CBV_bit3_NMCoordinatorBit 0;
BA_ "GenSigTimeoutTime_IPC" SG_ 2654486534 CBV_bit3_NMCoordinatorBit 0;
BA_ "GenSigTimeoutTime_RFHM" SG_ 2654486534 CBV_bit3_NMCoordinatorBit 0;
BA_ "GenSigTimeoutTime_SGW" SG_ 2654486534 CBV_bit3_NMCoordinatorBit 0;
BA_ "GenSigTimeoutTime_TCM" SG_ 2654486534 CBV_bit3_NMCoordinatorBit 0;
BA_ "GenSigTimeoutTime_AGSM" SG_ 2654486534 CBV_bit4_ActiveWakeupBit 0;
BA_ "GenSigTimeoutTime_BCM" SG_ 2654486534 CBV_bit4_ActiveWakeupBit 0;
BA_ "GenSigTimeoutTime_BSM" SG_ 2654486534 CBV_bit4_ActiveWakeupBit 0;
BA_ "GenSigTimeoutTime_CADM" SG_ 2654486534 CBV_bit4_ActiveWakeupBit 0;
BA_ "GenSigTimeoutTime_DMSM" SG_ 2654486534 CBV_bit4_ActiveWakeupBit 0;
BA_ "GenSigTimeoutTime_DTCM" SG_ 2654486534 CBV_bit4_ActiveWakeupBit 0;
BA_ "GenSigTimeoutTime_ECM" SG_ 2654486534 CBV_bit4_ActiveWakeupBit 0;
BA_ "GenSigTimeoutTime_EVCU2" SG_ 2654486534 CBV_bit4_ActiveWakeupBit 0;
BA_ "GenSigTimeoutTime_GNMM" SG_ 2654486534 CBV_bit4_ActiveWakeupBit 0;
BA_ "GenSigTimeoutTime_HCP" SG_ 2654486534 CBV_bit4_ActiveWakeupBit 0;
BA_ "GenSigTimeoutTime_IPC" SG_ 2654486534 CBV_bit4_ActiveWakeupBit 0;
BA_ "GenSigTimeoutTime_RFHM" SG_ 2654486534 CBV_bit4_ActiveWakeupBit 0;
BA_ "GenSigTimeoutTime_SGW" SG_ 2654486534 CBV_bit4_ActiveWakeupBit 0;
BA_ "GenSigTimeoutTime_TCM" SG_ 2654486534 CBV_bit4_ActiveWakeupBit 0;
BA_ "GenSigTimeoutTime_AGSM" SG_ 2654486534 CBV_bit5 0;
BA_ "GenSigTimeoutTime_BCM" SG_ 2654486534 CBV_bit5 0;
BA_ "GenSigTimeoutTime_BSM" SG_ 2654486534 CBV_bit5 0;
BA_ "GenSigTimeoutTime_CADM" SG_ 2654486534 CBV_bit5 0;
BA_ "GenSigTimeoutTime_DMSM" SG_ 2654486534 CBV_bit5 0;
BA_ "GenSigTimeoutTime_DTCM" SG_ 2654486534 CBV_bit5 0;
BA_ "GenSigTimeoutTime_ECM" SG_ 2654486534 CBV_bit5 0;
BA_ "GenSigTimeoutTime_EVCU2" SG_ 2654486534 CBV_bit5 0;
BA_ "GenSigTimeoutTime_GNMM" SG_ 2654486534 CBV_bit5 0;
BA_ "GenSigTimeoutTime_HCP" SG_ 2654486534 CBV_bit5 0;
BA_ "GenSigTimeoutTime_IPC" SG_ 2654486534 CBV_bit5 0;
BA_ "GenSigTimeoutTime_RFHM" SG_ 2654486534 CBV_bit5 0;
BA_ "GenSigTimeoutTime_SGW" SG_ 2654486534 CBV_bit5 0;
BA_ "GenSigTimeoutTime_TCM" SG_ 2654486534 CBV_bit5 0;
BA_ "GenSigTimeoutTime_AGSM" SG_ 2654486534 CBV_bit6_PartialNtwInfBit 0;
BA_ "GenSigTimeoutTime_BCM" SG_ 2654486534 CBV_bit6_PartialNtwInfBit 0;
BA_ "GenSigTimeoutTime_BSM" SG_ 2654486534 CBV_bit6_PartialNtwInfBit 0;
BA_ "GenSigTimeoutTime_CADM" SG_ 2654486534 CBV_bit6_PartialNtwInfBit 0;
BA_ "GenSigTimeoutTime_DMSM" SG_ 2654486534 CBV_bit6_PartialNtwInfBit 0;
BA_ "GenSigTimeoutTime_DTCM" SG_ 2654486534 CBV_bit6_PartialNtwInfBit 0;
BA_ "GenSigTimeoutTime_ECM" SG_ 2654486534 CBV_bit6_PartialNtwInfBit 0;
BA_ "GenSigTimeoutTime_EVCU2" SG_ 2654486534 CBV_bit6_PartialNtwInfBit 0;
BA_ "GenSigTimeoutTime_GNMM" SG_ 2654486534 CBV_bit6_PartialNtwInfBit 0;
BA_ "GenSigTimeoutTime_HCP" SG_ 2654486534 CBV_bit6_PartialNtwInfBit 0;
BA_ "GenSigTimeoutTime_IPC" SG_ 2654486534 CBV_bit6_PartialNtwInfBit 0;
BA_ "GenSigTimeoutTime_RFHM" SG_ 2654486534 CBV_bit6_PartialNtwInfBit 0;
BA_ "GenSigTimeoutTime_SGW" SG_ 2654486534 CBV_bit6_PartialNtwInfBit 0;
BA_ "GenSigTimeoutTime_TCM" SG_ 2654486534 CBV_bit6_PartialNtwInfBit 0;
BA_ "GenSigTimeoutTime_AGSM" SG_ 2654486534 CBV_bit7 0;
BA_ "GenSigTimeoutTime_BCM" SG_ 2654486534 CBV_bit7 0;
BA_ "GenSigTimeoutTime_BSM" SG_ 2654486534 CBV_bit7 0;
BA_ "GenSigTimeoutTime_CADM" SG_ 2654486534 CBV_bit7 0;
BA_ "GenSigTimeoutTime_DMSM" SG_ 2654486534 CBV_bit7 0;
BA_ "GenSigTimeoutTime_DTCM" SG_ 2654486534 CBV_bit7 0;
BA_ "GenSigTimeoutTime_ECM" SG_ 2654486534 CBV_bit7 0;
BA_ "GenSigTimeoutTime_EVCU2" SG_ 2654486534 CBV_bit7 0;
BA_ "GenSigTimeoutTime_GNMM" SG_ 2654486534 CBV_bit7 0;
BA_ "GenSigTimeoutTime_HCP" SG_ 2654486534 CBV_bit7 0;
BA_ "GenSigTimeoutTime_IPC" SG_ 2654486534 CBV_bit7 0;
BA_ "GenSigTimeoutTime_RFHM" SG_ 2654486534 CBV_bit7 0;
BA_ "GenSigTimeoutTime_SGW" SG_ 2654486534 CBV_bit7 0;
BA_ "GenSigTimeoutTime_TCM" SG_ 2654486534 CBV_bit7 0;
BA_ "GenSigTimeoutTime_AGSM" SG_ 2654486534 SourceNodeIdentifier 0;
BA_ "GenSigTimeoutTime_BCM" SG_ 2654486534 SourceNodeIdentifier 0;
BA_ "GenSigTimeoutTime_BSM" SG_ 2654486534 SourceNodeIdentifier 0;
BA_ "GenSigTimeoutTime_CADM" SG_ 2654486534 SourceNodeIdentifier 0;
BA_ "GenSigTimeoutTime_DMSM" SG_ 2654486534 SourceNodeIdentifier 0;
BA_ "GenSigTimeoutTime_DTCM" SG_ 2654486534 SourceNodeIdentifier 0;
BA_ "GenSigTimeoutTime_ECM" SG_ 2654486534 SourceNodeIdentifier 0;
BA_ "GenSigTimeoutTime_EVCU2" SG_ 2654486534 SourceNodeIdentifier 0;
BA_ "GenSigTimeoutTime_GNMM" SG_ 2654486534 SourceNodeIdentifier 0;
BA_ "GenSigTimeoutTime_HCP" SG_ 2654486534 SourceNodeIdentifier 0;
BA_ "GenSigTimeoutTime_IPC" SG_ 2654486534 SourceNodeIdentifier 0;
BA_ "GenSigTimeoutTime_RFHM" SG_ 2654486534 SourceNodeIdentifier 0;
BA_ "GenSigTimeoutTime_SGW" SG_ 2654486534 SourceNodeIdentifier 0;
BA_ "GenSigTimeoutTime_TCM" SG_ 2654486534 SourceNodeIdentifier 0;
BA_ "GenSigTimeoutTime_AGSM" SG_ 2654486669 CBV_bit0_RepeatMessageRequestBit 0;
BA_ "GenSigTimeoutTime_BCM" SG_ 2654486669 CBV_bit0_RepeatMessageRequestBit 0;
BA_ "GenSigTimeoutTime_BSM" SG_ 2654486669 CBV_bit0_RepeatMessageRequestBit 0;
BA_ "GenSigTimeoutTime_CADM" SG_ 2654486669 CBV_bit0_RepeatMessageRequestBit 0;
BA_ "GenSigTimeoutTime_DMSM" SG_ 2654486669 CBV_bit0_RepeatMessageRequestBit 0;
BA_ "GenSigTimeoutTime_DTCM" SG_ 2654486669 CBV_bit0_RepeatMessageRequestBit 0;
BA_ "GenSigTimeoutTime_ECM" SG_ 2654486669 CBV_bit0_RepeatMessageRequestBit 0;
BA_ "GenSigTimeoutTime_EVCU2" SG_ 2654486669 CBV_bit0_RepeatMessageRequestBit 0;
BA_ "GenSigTimeoutTime_GNMM" SG_ 2654486669 CBV_bit0_RepeatMessageRequestBit 0;
BA_ "GenSigTimeoutTime_HCP" SG_ 2654486669 CBV_bit0_RepeatMessageRequestBit 0;
BA_ "GenSigTimeoutTime_IPC" SG_ 2654486669 CBV_bit0_RepeatMessageRequestBit 0;
BA_ "GenSigTimeoutTime_RFHM" SG_ 2654486669 CBV_bit0_RepeatMessageRequestBit 0;
BA_ "GenSigTimeoutTime_SGW" SG_ 2654486669 CBV_bit0_RepeatMessageRequestBit 0;
BA_ "GenSigTimeoutTime_TCM" SG_ 2654486669 CBV_bit0_RepeatMessageRequestBit 0;
BA_ "GenSigTimeoutTime_AGSM" SG_ 2654486669 CBV_bit1 0;
BA_ "GenSigTimeoutTime_BCM" SG_ 2654486669 CBV_bit1 0;
BA_ "GenSigTimeoutTime_BSM" SG_ 2654486669 CBV_bit1 0;
BA_ "GenSigTimeoutTime_CADM" SG_ 2654486669 CBV_bit1 0;
BA_ "GenSigTimeoutTime_DMSM" SG_ 2654486669 CBV_bit1 0;
BA_ "GenSigTimeoutTime_DTCM" SG_ 2654486669 CBV_bit1 0;
BA_ "GenSigTimeoutTime_ECM" SG_ 2654486669 CBV_bit1 0;
BA_ "GenSigTimeoutTime_EVCU2" SG_ 2654486669 CBV_bit1 0;
BA_ "GenSigTimeoutTime_GNMM" SG_ 2654486669 CBV_bit1 0;
BA_ "GenSigTimeoutTime_HCP" SG_ 2654486669 CBV_bit1 0;
BA_ "GenSigTimeoutTime_IPC" SG_ 2654486669 CBV_bit1 0;
BA_ "GenSigTimeoutTime_RFHM" SG_ 2654486669 CBV_bit1 0;
BA_ "GenSigTimeoutTime_SGW" SG_ 2654486669 CBV_bit1 0;
BA_ "GenSigTimeoutTime_TCM" SG_ 2654486669 CBV_bit1 0;
BA_ "GenSigTimeoutTime_AGSM" SG_ 2654486669 CBV_bit2 0;
BA_ "GenSigTimeoutTime_BCM" SG_ 2654486669 CBV_bit2 0;
BA_ "GenSigTimeoutTime_BSM" SG_ 2654486669 CBV_bit2 0;
BA_ "GenSigTimeoutTime_CADM" SG_ 2654486669 CBV_bit2 0;
BA_ "GenSigTimeoutTime_DMSM" SG_ 2654486669 CBV_bit2 0;
BA_ "GenSigTimeoutTime_DTCM" SG_ 2654486669 CBV_bit2 0;
BA_ "GenSigTimeoutTime_ECM" SG_ 2654486669 CBV_bit2 0;
BA_ "GenSigTimeoutTime_EVCU2" SG_ 2654486669 CBV_bit2 0;
BA_ "GenSigTimeoutTime_GNMM" SG_ 2654486669 CBV_bit2 0;
BA_ "GenSigTimeoutTime_HCP" SG_ 2654486669 CBV_bit2 0;
BA_ "GenSigTimeoutTime_IPC" SG_ 2654486669 CBV_bit2 0;
BA_ "GenSigTimeoutTime_RFHM" SG_ 2654486669 CBV_bit2 0;
BA_ "GenSigTimeoutTime_SGW" SG_ 2654486669 CBV_bit2 0;
BA_ "GenSigTimeoutTime_TCM" SG_ 2654486669 CBV_bit2 0;
BA_ "GenSigTimeoutTime_AGSM" SG_ 2654486669 CBV_bit3_NMCoordinatorBit 0;
BA_ "GenSigTimeoutTime_BCM" SG_ 2654486669 CBV_bit3_NMCoordinatorBit 0;
BA_ "GenSigTimeoutTime_BSM" SG_ 2654486669 CBV_bit3_NMCoordinatorBit 0;
BA_ "GenSigTimeoutTime_CADM" SG_ 2654486669 CBV_bit3_NMCoordinatorBit 0;
BA_ "GenSigTimeoutTime_DMSM" SG_ 2654486669 CBV_bit3_NMCoordinatorBit 0;
BA_ "GenSigTimeoutTime_DTCM" SG_ 2654486669 CBV_bit3_NMCoordinatorBit 0;
BA_ "GenSigTimeoutTime_ECM" SG_ 2654486669 CBV_bit3_NMCoordinatorBit 0;
BA_ "GenSigTimeoutTime_EVCU2" SG_ 2654486669 CBV_bit3_NMCoordinatorBit 0;
BA_ "GenSigTimeoutTime_GNMM" SG_ 2654486669 CBV_bit3_NMCoordinatorBit 0;
BA_ "GenSigTimeoutTime_HCP" SG_ 2654486669 CBV_bit3_NMCoordinatorBit 0;
BA_ "GenSigTimeoutTime_IPC" SG_ 2654486669 CBV_bit3_NMCoordinatorBit 0;
BA_ "GenSigTimeoutTime_RFHM" SG_ 2654486669 CBV_bit3_NMCoordinatorBit 0;
BA_ "GenSigTimeoutTime_SGW" SG_ 2654486669 CBV_bit3_NMCoordinatorBit 0;
BA_ "GenSigTimeoutTime_TCM" SG_ 2654486669 CBV_bit3_NMCoordinatorBit 0;
BA_ "GenSigTimeoutTime_AGSM" SG_ 2654486669 CBV_bit4_ActiveWakeupBit 0;
BA_ "GenSigTimeoutTime_BCM" SG_ 2654486669 CBV_bit4_ActiveWakeupBit 0;
BA_ "GenSigTimeoutTime_BSM" SG_ 2654486669 CBV_bit4_ActiveWakeupBit 0;
BA_ "GenSigTimeoutTime_CADM" SG_ 2654486669 CBV_bit4_ActiveWakeupBit 0;
BA_ "GenSigTimeoutTime_DMSM" SG_ 2654486669 CBV_bit4_ActiveWakeupBit 0;
BA_ "GenSigTimeoutTime_DTCM" SG_ 2654486669 CBV_bit4_ActiveWakeupBit 0;
BA_ "GenSigTimeoutTime_ECM" SG_ 2654486669 CBV_bit4_ActiveWakeupBit 0;
BA_ "GenSigTimeoutTime_EVCU2" SG_ 2654486669 CBV_bit4_ActiveWakeupBit 0;
BA_ "GenSigTimeoutTime_GNMM" SG_ 2654486669 CBV_bit4_ActiveWakeupBit 0;
BA_ "GenSigTimeoutTime_HCP" SG_ 2654486669 CBV_bit4_ActiveWakeupBit 0;
BA_ "GenSigTimeoutTime_IPC" SG_ 2654486669 CBV_bit4_ActiveWakeupBit 0;
BA_ "GenSigTimeoutTime_RFHM" SG_ 2654486669 CBV_bit4_ActiveWakeupBit 0;
BA_ "GenSigTimeoutTime_SGW" SG_ 2654486669 CBV_bit4_ActiveWakeupBit 0;
BA_ "GenSigTimeoutTime_TCM" SG_ 2654486669 CBV_bit4_ActiveWakeupBit 0;
BA_ "GenSigTimeoutTime_AGSM" SG_ 2654486669 CBV_bit5 0;
BA_ "GenSigTimeoutTime_BCM" SG_ 2654486669 CBV_bit5 0;
BA_ "GenSigTimeoutTime_BSM" SG_ 2654486669 CBV_bit5 0;
BA_ "GenSigTimeoutTime_CADM" SG_ 2654486669 CBV_bit5 0;
BA_ "GenSigTimeoutTime_DMSM" SG_ 2654486669 CBV_bit5 0;
BA_ "GenSigTimeoutTime_DTCM" SG_ 2654486669 CBV_bit5 0;
BA_ "GenSigTimeoutTime_ECM" SG_ 2654486669 CBV_bit5 0;
BA_ "GenSigTimeoutTime_EVCU2" SG_ 2654486669 CBV_bit5 0;
BA_ "GenSigTimeoutTime_GNMM" SG_ 2654486669 CBV_bit5 0;
BA_ "GenSigTimeoutTime_HCP" SG_ 2654486669 CBV_bit5 0;
BA_ "GenSigTimeoutTime_IPC" SG_ 2654486669 CBV_bit5 0;
BA_ "GenSigTimeoutTime_RFHM" SG_ 2654486669 CBV_bit5 0;
BA_ "GenSigTimeoutTime_SGW" SG_ 2654486669 CBV_bit5 0;
BA_ "GenSigTimeoutTime_TCM" SG_ 2654486669 CBV_bit5 0;
BA_ "GenSigTimeoutTime_AGSM" SG_ 2654486669 CBV_bit6_PartialNtwInfBit 0;
BA_ "GenSigTimeoutTime_BCM" SG_ 2654486669 CBV_bit6_PartialNtwInfBit 0;
BA_ "GenSigTimeoutTime_BSM" SG_ 2654486669 CBV_bit6_PartialNtwInfBit 0;
BA_ "GenSigTimeoutTime_CADM" SG_ 2654486669 CBV_bit6_PartialNtwInfBit 0;
BA_ "GenSigTimeoutTime_DMSM" SG_ 2654486669 CBV_bit6_PartialNtwInfBit 0;
BA_ "GenSigTimeoutTime_DTCM" SG_ 2654486669 CBV_bit6_PartialNtwInfBit 0;
BA_ "GenSigTimeoutTime_ECM" SG_ 2654486669 CBV_bit6_PartialNtwInfBit 0;
BA_ "GenSigTimeoutTime_EVCU2" SG_ 2654486669 CBV_bit6_PartialNtwInfBit 0;
BA_ "GenSigTimeoutTime_GNMM" SG_ 2654486669 CBV_bit6_PartialNtwInfBit 0;
BA_ "GenSigTimeoutTime_HCP" SG_ 2654486669 CBV_bit6_PartialNtwInfBit 0;
BA_ "GenSigTimeoutTime_IPC" SG_ 2654486669 CBV_bit6_PartialNtwInfBit 0;
BA_ "GenSigTimeoutTime_RFHM" SG_ 2654486669 CBV_bit6_PartialNtwInfBit 0;
BA_ "GenSigTimeoutTime_SGW" SG_ 2654486669 CBV_bit6_PartialNtwInfBit 0;
BA_ "GenSigTimeoutTime_TCM" SG_ 2654486669 CBV_bit6_PartialNtwInfBit 0;
BA_ "GenSigTimeoutTime_AGSM" SG_ 2654486669 CBV_bit7 0;
BA_ "GenSigTimeoutTime_BCM" SG_ 2654486669 CBV_bit7 0;
BA_ "GenSigTimeoutTime_BSM" SG_ 2654486669 CBV_bit7 0;
BA_ "GenSigTimeoutTime_CADM" SG_ 2654486669 CBV_bit7 0;
BA_ "GenSigTimeoutTime_DMSM" SG_ 2654486669 CBV_bit7 0;
BA_ "GenSigTimeoutTime_DTCM" SG_ 2654486669 CBV_bit7 0;
BA_ "GenSigTimeoutTime_ECM" SG_ 2654486669 CBV_bit7 0;
BA_ "GenSigTimeoutTime_EVCU2" SG_ 2654486669 CBV_bit7 0;
BA_ "GenSigTimeoutTime_GNMM" SG_ 2654486669 CBV_bit7 0;
BA_ "GenSigTimeoutTime_HCP" SG_ 2654486669 CBV_bit7 0;
BA_ "GenSigTimeoutTime_IPC" SG_ 2654486669 CBV_bit7 0;
BA_ "GenSigTimeoutTime_RFHM" SG_ 2654486669 CBV_bit7 0;
BA_ "GenSigTimeoutTime_SGW" SG_ 2654486669 CBV_bit7 0;
BA_ "GenSigTimeoutTime_TCM" SG_ 2654486669 CBV_bit7 0;
BA_ "GenSigTimeoutTime_AGSM" SG_ 2654486669 SourceNodeIdentifier 0;
BA_ "GenSigTimeoutTime_BCM" SG_ 2654486669 SourceNodeIdentifier 0;
BA_ "GenSigTimeoutTime_BSM" SG_ 2654486669 SourceNodeIdentifier 0;
BA_ "GenSigTimeoutTime_CADM" SG_ 2654486669 SourceNodeIdentifier 0;
BA_ "GenSigTimeoutTime_DMSM" SG_ 2654486669 SourceNodeIdentifier 0;
BA_ "GenSigTimeoutTime_DTCM" SG_ 2654486669 SourceNodeIdentifier 0;
BA_ "GenSigTimeoutTime_ECM" SG_ 2654486669 SourceNodeIdentifier 0;
BA_ "GenSigTimeoutTime_EVCU2" SG_ 2654486669 SourceNodeIdentifier 0;
BA_ "GenSigTimeoutTime_GNMM" SG_ 2654486669 SourceNodeIdentifier 0;
BA_ "GenSigTimeoutTime_HCP" SG_ 2654486669 SourceNodeIdentifier 0;
BA_ "GenSigTimeoutTime_IPC" SG_ 2654486669 SourceNodeIdentifier 0;
BA_ "GenSigTimeoutTime_RFHM" SG_ 2654486669 SourceNodeIdentifier 0;
BA_ "GenSigTimeoutTime_SGW" SG_ 2654486669 SourceNodeIdentifier 0;
BA_ "GenSigTimeoutTime_TCM" SG_ 2654486669 SourceNodeIdentifier 0;
BA_ "GenSigTimeoutTime_AGSM" SG_ 2654486595 CBV_bit0_RepeatMessageRequestBit 0;
BA_ "GenSigTimeoutTime_BCM" SG_ 2654486595 CBV_bit0_RepeatMessageRequestBit 0;
BA_ "GenSigTimeoutTime_BSM" SG_ 2654486595 CBV_bit0_RepeatMessageRequestBit 0;
BA_ "GenSigTimeoutTime_CADM" SG_ 2654486595 CBV_bit0_RepeatMessageRequestBit 0;
BA_ "GenSigTimeoutTime_DMSM" SG_ 2654486595 CBV_bit0_RepeatMessageRequestBit 0;
BA_ "GenSigTimeoutTime_DTCM" SG_ 2654486595 CBV_bit0_RepeatMessageRequestBit 0;
BA_ "GenSigTimeoutTime_ECM" SG_ 2654486595 CBV_bit0_RepeatMessageRequestBit 0;
BA_ "GenSigTimeoutTime_EVCU2" SG_ 2654486595 CBV_bit0_RepeatMessageRequestBit 0;
BA_ "GenSigTimeoutTime_GNMM" SG_ 2654486595 CBV_bit0_RepeatMessageRequestBit 0;
BA_ "GenSigTimeoutTime_HCP" SG_ 2654486595 CBV_bit0_RepeatMessageRequestBit 0;
BA_ "GenSigTimeoutTime_IPC" SG_ 2654486595 CBV_bit0_RepeatMessageRequestBit 0;
BA_ "GenSigTimeoutTime_RFHM" SG_ 2654486595 CBV_bit0_RepeatMessageRequestBit 0;
BA_ "GenSigTimeoutTime_SGW" SG_ 2654486595 CBV_bit0_RepeatMessageRequestBit 0;
BA_ "GenSigTimeoutTime_TCM" SG_ 2654486595 CBV_bit0_RepeatMessageRequestBit 0;
BA_ "GenSigTimeoutTime_AGSM" SG_ 2654486595 CBV_bit1 0;
BA_ "GenSigTimeoutTime_BCM" SG_ 2654486595 CBV_bit1 0;
BA_ "GenSigTimeoutTime_BSM" SG_ 2654486595 CBV_bit1 0;
BA_ "GenSigTimeoutTime_CADM" SG_ 2654486595 CBV_bit1 0;
BA_ "GenSigTimeoutTime_DMSM" SG_ 2654486595 CBV_bit1 0;
BA_ "GenSigTimeoutTime_DTCM" SG_ 2654486595 CBV_bit1 0;
BA_ "GenSigTimeoutTime_ECM" SG_ 2654486595 CBV_bit1 0;
BA_ "GenSigTimeoutTime_EVCU2" SG_ 2654486595 CBV_bit1 0;
BA_ "GenSigTimeoutTime_GNMM" SG_ 2654486595 CBV_bit1 0;
BA_ "GenSigTimeoutTime_HCP" SG_ 2654486595 CBV_bit1 0;
BA_ "GenSigTimeoutTime_IPC" SG_ 2654486595 CBV_bit1 0;
BA_ "GenSigTimeoutTime_RFHM" SG_ 2654486595 CBV_bit1 0;
BA_ "GenSigTimeoutTime_SGW" SG_ 2654486595 CBV_bit1 0;
BA_ "GenSigTimeoutTime_TCM" SG_ 2654486595 CBV_bit1 0;
BA_ "GenSigTimeoutTime_AGSM" SG_ 2654486595 CBV_bit2 0;
BA_ "GenSigTimeoutTime_BCM" SG_ 2654486595 CBV_bit2 0;
BA_ "GenSigTimeoutTime_BSM" SG_ 2654486595 CBV_bit2 0;
BA_ "GenSigTimeoutTime_CADM" SG_ 2654486595 CBV_bit2 0;
BA_ "GenSigTimeoutTime_DMSM" SG_ 2654486595 CBV_bit2 0;
BA_ "GenSigTimeoutTime_DTCM" SG_ 2654486595 CBV_bit2 0;
BA_ "GenSigTimeoutTime_ECM" SG_ 2654486595 CBV_bit2 0;
BA_ "GenSigTimeoutTime_EVCU2" SG_ 2654486595 CBV_bit2 0;
BA_ "GenSigTimeoutTime_GNMM" SG_ 2654486595 CBV_bit2 0;
BA_ "GenSigTimeoutTime_HCP" SG_ 2654486595 CBV_bit2 0;
BA_ "GenSigTimeoutTime_IPC" SG_ 2654486595 CBV_bit2 0;
BA_ "GenSigTimeoutTime_RFHM" SG_ 2654486595 CBV_bit2 0;
BA_ "GenSigTimeoutTime_SGW" SG_ 2654486595 CBV_bit2 0;
BA_ "GenSigTimeoutTime_TCM" SG_ 2654486595 CBV_bit2 0;
BA_ "GenSigTimeoutTime_AGSM" SG_ 2654486595 CBV_bit3_NMCoordinatorBit 0;
BA_ "GenSigTimeoutTime_BCM" SG_ 2654486595 CBV_bit3_NMCoordinatorBit 0;
BA_ "GenSigTimeoutTime_BSM" SG_ 2654486595 CBV_bit3_NMCoordinatorBit 0;
BA_ "GenSigTimeoutTime_CADM" SG_ 2654486595 CBV_bit3_NMCoordinatorBit 0;
BA_ "GenSigTimeoutTime_DMSM" SG_ 2654486595 CBV_bit3_NMCoordinatorBit 0;
BA_ "GenSigTimeoutTime_DTCM" SG_ 2654486595 CBV_bit3_NMCoordinatorBit 0;
BA_ "GenSigTimeoutTime_ECM" SG_ 2654486595 CBV_bit3_NMCoordinatorBit 0;
BA_ "GenSigTimeoutTime_EVCU2" SG_ 2654486595 CBV_bit3_NMCoordinatorBit 0;
BA_ "GenSigTimeoutTime_GNMM" SG_ 2654486595 CBV_bit3_NMCoordinatorBit 0;
BA_ "GenSigTimeoutTime_HCP" SG_ 2654486595 CBV_bit3_NMCoordinatorBit 0;
BA_ "GenSigTimeoutTime_IPC" SG_ 2654486595 CBV_bit3_NMCoordinatorBit 0;
BA_ "GenSigTimeoutTime_RFHM" SG_ 2654486595 CBV_bit3_NMCoordinatorBit 0;
BA_ "GenSigTimeoutTime_SGW" SG_ 2654486595 CBV_bit3_NMCoordinatorBit 0;
BA_ "GenSigTimeoutTime_TCM" SG_ 2654486595 CBV_bit3_NMCoordinatorBit 0;
BA_ "GenSigTimeoutTime_AGSM" SG_ 2654486595 CBV_bit4_ActiveWakeupBit 0;
BA_ "GenSigTimeoutTime_BCM" SG_ 2654486595 CBV_bit4_ActiveWakeupBit 0;
BA_ "GenSigTimeoutTime_BSM" SG_ 2654486595 CBV_bit4_ActiveWakeupBit 0;
BA_ "GenSigTimeoutTime_CADM" SG_ 2654486595 CBV_bit4_ActiveWakeupBit 0;
BA_ "GenSigTimeoutTime_DMSM" SG_ 2654486595 CBV_bit4_ActiveWakeupBit 0;
BA_ "GenSigTimeoutTime_DTCM" SG_ 2654486595 CBV_bit4_ActiveWakeupBit 0;
BA_ "GenSigTimeoutTime_ECM" SG_ 2654486595 CBV_bit4_ActiveWakeupBit 0;
BA_ "GenSigTimeoutTime_EVCU2" SG_ 2654486595 CBV_bit4_ActiveWakeupBit 0;
BA_ "GenSigTimeoutTime_GNMM" SG_ 2654486595 CBV_bit4_ActiveWakeupBit 0;
BA_ "GenSigTimeoutTime_HCP" SG_ 2654486595 CBV_bit4_ActiveWakeupBit 0;
BA_ "GenSigTimeoutTime_IPC" SG_ 2654486595 CBV_bit4_ActiveWakeupBit 0;
BA_ "GenSigTimeoutTime_RFHM" SG_ 2654486595 CBV_bit4_ActiveWakeupBit 0;
BA_ "GenSigTimeoutTime_SGW" SG_ 2654486595 CBV_bit4_ActiveWakeupBit 0;
BA_ "GenSigTimeoutTime_TCM" SG_ 2654486595 CBV_bit4_ActiveWakeupBit 0;
BA_ "GenSigTimeoutTime_AGSM" SG_ 2654486595 CBV_bit5 0;
BA_ "GenSigTimeoutTime_BCM" SG_ 2654486595 CBV_bit5 0;
BA_ "GenSigTimeoutTime_BSM" SG_ 2654486595 CBV_bit5 0;
BA_ "GenSigTimeoutTime_CADM" SG_ 2654486595 CBV_bit5 0;
BA_ "GenSigTimeoutTime_DMSM" SG_ 2654486595 CBV_bit5 0;
BA_ "GenSigTimeoutTime_DTCM" SG_ 2654486595 CBV_bit5 0;
BA_ "GenSigTimeoutTime_ECM" SG_ 2654486595 CBV_bit5 0;
BA_ "GenSigTimeoutTime_EVCU2" SG_ 2654486595 CBV_bit5 0;
BA_ "GenSigTimeoutTime_GNMM" SG_ 2654486595 CBV_bit5 0;
BA_ "GenSigTimeoutTime_HCP" SG_ 2654486595 CBV_bit5 0;
BA_ "GenSigTimeoutTime_IPC" SG_ 2654486595 CBV_bit5 0;
BA_ "GenSigTimeoutTime_RFHM" SG_ 2654486595 CBV_bit5 0;
BA_ "GenSigTimeoutTime_SGW" SG_ 2654486595 CBV_bit5 0;
BA_ "GenSigTimeoutTime_TCM" SG_ 2654486595 CBV_bit5 0;
BA_ "GenSigTimeoutTime_AGSM" SG_ 2654486595 CBV_bit6_PartialNtwInfBit 0;
BA_ "GenSigTimeoutTime_BCM" SG_ 2654486595 CBV_bit6_PartialNtwInfBit 0;
BA_ "GenSigTimeoutTime_BSM" SG_ 2654486595 CBV_bit6_PartialNtwInfBit 0;
BA_ "GenSigTimeoutTime_CADM" SG_ 2654486595 CBV_bit6_PartialNtwInfBit 0;
BA_ "GenSigTimeoutTime_DMSM" SG_ 2654486595 CBV_bit6_PartialNtwInfBit 0;
BA_ "GenSigTimeoutTime_DTCM" SG_ 2654486595 CBV_bit6_PartialNtwInfBit 0;
BA_ "GenSigTimeoutTime_ECM" SG_ 2654486595 CBV_bit6_PartialNtwInfBit 0;
BA_ "GenSigTimeoutTime_EVCU2" SG_ 2654486595 CBV_bit6_PartialNtwInfBit 0;
BA_ "GenSigTimeoutTime_GNMM" SG_ 2654486595 CBV_bit6_PartialNtwInfBit 0;
BA_ "GenSigTimeoutTime_HCP" SG_ 2654486595 CBV_bit6_PartialNtwInfBit 0;
BA_ "GenSigTimeoutTime_IPC" SG_ 2654486595 CBV_bit6_PartialNtwInfBit 0;
BA_ "GenSigTimeoutTime_RFHM" SG_ 2654486595 CBV_bit6_PartialNtwInfBit 0;
BA_ "GenSigTimeoutTime_SGW" SG_ 2654486595 CBV_bit6_PartialNtwInfBit 0;
BA_ "GenSigTimeoutTime_TCM" SG_ 2654486595 CBV_bit6_PartialNtwInfBit 0;
BA_ "GenSigTimeoutTime_AGSM" SG_ 2654486595 CBV_bit7 0;
BA_ "GenSigTimeoutTime_BCM" SG_ 2654486595 CBV_bit7 0;
BA_ "GenSigTimeoutTime_BSM" SG_ 2654486595 CBV_bit7 0;
BA_ "GenSigTimeoutTime_CADM" SG_ 2654486595 CBV_bit7 0;
BA_ "GenSigTimeoutTime_DMSM" SG_ 2654486595 CBV_bit7 0;
BA_ "GenSigTimeoutTime_DTCM" SG_ 2654486595 CBV_bit7 0;
BA_ "GenSigTimeoutTime_ECM" SG_ 2654486595 CBV_bit7 0;
BA_ "GenSigTimeoutTime_EVCU2" SG_ 2654486595 CBV_bit7 0;
BA_ "GenSigTimeoutTime_GNMM" SG_ 2654486595 CBV_bit7 0;
BA_ "GenSigTimeoutTime_HCP" SG_ 2654486595 CBV_bit7 0;
BA_ "GenSigTimeoutTime_IPC" SG_ 2654486595 CBV_bit7 0;
BA_ "GenSigTimeoutTime_RFHM" SG_ 2654486595 CBV_bit7 0;
BA_ "GenSigTimeoutTime_SGW" SG_ 2654486595 CBV_bit7 0;
BA_ "GenSigTimeoutTime_TCM" SG_ 2654486595 CBV_bit7 0;
BA_ "GenSigTimeoutTime_AGSM" SG_ 2654486595 SourceNodeIdentifier 0;
BA_ "GenSigTimeoutTime_BCM" SG_ 2654486595 SourceNodeIdentifier 0;
BA_ "GenSigTimeoutTime_BSM" SG_ 2654486595 SourceNodeIdentifier 0;
BA_ "GenSigTimeoutTime_CADM" SG_ 2654486595 SourceNodeIdentifier 0;
BA_ "GenSigTimeoutTime_DMSM" SG_ 2654486595 SourceNodeIdentifier 0;
BA_ "GenSigTimeoutTime_DTCM" SG_ 2654486595 SourceNodeIdentifier 0;
BA_ "GenSigTimeoutTime_ECM" SG_ 2654486595 SourceNodeIdentifier 0;
BA_ "GenSigTimeoutTime_EVCU2" SG_ 2654486595 SourceNodeIdentifier 0;
BA_ "GenSigTimeoutTime_GNMM" SG_ 2654486595 SourceNodeIdentifier 0;
BA_ "GenSigTimeoutTime_HCP" SG_ 2654486595 SourceNodeIdentifier 0;
BA_ "GenSigTimeoutTime_IPC" SG_ 2654486595 SourceNodeIdentifier 0;
BA_ "GenSigTimeoutTime_RFHM" SG_ 2654486595 SourceNodeIdentifier 0;
BA_ "GenSigTimeoutTime_SGW" SG_ 2654486595 SourceNodeIdentifier 0;
BA_ "GenSigTimeoutTime_TCM" SG_ 2654486595 SourceNodeIdentifier 0;
BA_ "GenSigTimeoutTime_AGSM" SG_ 2654486529 CBV_bit0_RepeatMessageRequestBit 0;
BA_ "GenSigTimeoutTime_BCM" SG_ 2654486529 CBV_bit0_RepeatMessageRequestBit 0;
BA_ "GenSigTimeoutTime_BSM" SG_ 2654486529 CBV_bit0_RepeatMessageRequestBit 0;
BA_ "GenSigTimeoutTime_CADM" SG_ 2654486529 CBV_bit0_RepeatMessageRequestBit 0;
BA_ "GenSigTimeoutTime_DMSM" SG_ 2654486529 CBV_bit0_RepeatMessageRequestBit 0;
BA_ "GenSigTimeoutTime_DTCM" SG_ 2654486529 CBV_bit0_RepeatMessageRequestBit 0;
BA_ "GenSigTimeoutTime_ECM" SG_ 2654486529 CBV_bit0_RepeatMessageRequestBit 0;
BA_ "GenSigTimeoutTime_EVCU2" SG_ 2654486529 CBV_bit0_RepeatMessageRequestBit 0;
BA_ "GenSigTimeoutTime_GNMM" SG_ 2654486529 CBV_bit0_RepeatMessageRequestBit 0;
BA_ "GenSigTimeoutTime_HCP" SG_ 2654486529 CBV_bit0_RepeatMessageRequestBit 0;
BA_ "GenSigTimeoutTime_IPC" SG_ 2654486529 CBV_bit0_RepeatMessageRequestBit 0;
BA_ "GenSigTimeoutTime_RFHM" SG_ 2654486529 CBV_bit0_RepeatMessageRequestBit 0;
BA_ "GenSigTimeoutTime_SGW" SG_ 2654486529 CBV_bit0_RepeatMessageRequestBit 0;
BA_ "GenSigTimeoutTime_TCM" SG_ 2654486529 CBV_bit0_RepeatMessageRequestBit 0;
BA_ "GenSigTimeoutTime_AGSM" SG_ 2654486529 CBV_bit1 0;
BA_ "GenSigTimeoutTime_BCM" SG_ 2654486529 CBV_bit1 0;
BA_ "GenSigTimeoutTime_BSM" SG_ 2654486529 CBV_bit1 0;
BA_ "GenSigTimeoutTime_CADM" SG_ 2654486529 CBV_bit1 0;
BA_ "GenSigTimeoutTime_DMSM" SG_ 2654486529 CBV_bit1 0;
BA_ "GenSigTimeoutTime_DTCM" SG_ 2654486529 CBV_bit1 0;
BA_ "GenSigTimeoutTime_ECM" SG_ 2654486529 CBV_bit1 0;
BA_ "GenSigTimeoutTime_EVCU2" SG_ 2654486529 CBV_bit1 0;
BA_ "GenSigTimeoutTime_GNMM" SG_ 2654486529 CBV_bit1 0;
BA_ "GenSigTimeoutTime_HCP" SG_ 2654486529 CBV_bit1 0;
BA_ "GenSigTimeoutTime_IPC" SG_ 2654486529 CBV_bit1 0;
BA_ "GenSigTimeoutTime_RFHM" SG_ 2654486529 CBV_bit1 0;
BA_ "GenSigTimeoutTime_SGW" SG_ 2654486529 CBV_bit1 0;
BA_ "GenSigTimeoutTime_TCM" SG_ 2654486529 CBV_bit1 0;
BA_ "GenSigTimeoutTime_AGSM" SG_ 2654486529 CBV_bit2 0;
BA_ "GenSigTimeoutTime_BCM" SG_ 2654486529 CBV_bit2 0;
BA_ "GenSigTimeoutTime_BSM" SG_ 2654486529 CBV_bit2 0;
BA_ "GenSigTimeoutTime_CADM" SG_ 2654486529 CBV_bit2 0;
BA_ "GenSigTimeoutTime_DMSM" SG_ 2654486529 CBV_bit2 0;
BA_ "GenSigTimeoutTime_DTCM" SG_ 2654486529 CBV_bit2 0;
BA_ "GenSigTimeoutTime_ECM" SG_ 2654486529 CBV_bit2 0;
BA_ "GenSigTimeoutTime_EVCU2" SG_ 2654486529 CBV_bit2 0;
BA_ "GenSigTimeoutTime_GNMM" SG_ 2654486529 CBV_bit2 0;
BA_ "GenSigTimeoutTime_HCP" SG_ 2654486529 CBV_bit2 0;
BA_ "GenSigTimeoutTime_IPC" SG_ 2654486529 CBV_bit2 0;
BA_ "GenSigTimeoutTime_RFHM" SG_ 2654486529 CBV_bit2 0;
BA_ "GenSigTimeoutTime_SGW" SG_ 2654486529 CBV_bit2 0;
BA_ "GenSigTimeoutTime_TCM" SG_ 2654486529 CBV_bit2 0;
BA_ "GenSigTimeoutTime_AGSM" SG_ 2654486529 CBV_bit3_NMCoordinatorBit 0;
BA_ "GenSigTimeoutTime_BCM" SG_ 2654486529 CBV_bit3_NMCoordinatorBit 0;
BA_ "GenSigTimeoutTime_BSM" SG_ 2654486529 CBV_bit3_NMCoordinatorBit 0;
BA_ "GenSigTimeoutTime_CADM" SG_ 2654486529 CBV_bit3_NMCoordinatorBit 0;
BA_ "GenSigTimeoutTime_DMSM" SG_ 2654486529 CBV_bit3_NMCoordinatorBit 0;
BA_ "GenSigTimeoutTime_DTCM" SG_ 2654486529 CBV_bit3_NMCoordinatorBit 0;
BA_ "GenSigTimeoutTime_ECM" SG_ 2654486529 CBV_bit3_NMCoordinatorBit 0;
BA_ "GenSigTimeoutTime_EVCU2" SG_ 2654486529 CBV_bit3_NMCoordinatorBit 0;
BA_ "GenSigTimeoutTime_GNMM" SG_ 2654486529 CBV_bit3_NMCoordinatorBit 0;
BA_ "GenSigTimeoutTime_HCP" SG_ 2654486529 CBV_bit3_NMCoordinatorBit 0;
BA_ "GenSigTimeoutTime_IPC" SG_ 2654486529 CBV_bit3_NMCoordinatorBit 0;
BA_ "GenSigTimeoutTime_RFHM" SG_ 2654486529 CBV_bit3_NMCoordinatorBit 0;
BA_ "GenSigTimeoutTime_SGW" SG_ 2654486529 CBV_bit3_NMCoordinatorBit 0;
BA_ "GenSigTimeoutTime_TCM" SG_ 2654486529 CBV_bit3_NMCoordinatorBit 0;
BA_ "GenSigTimeoutTime_AGSM" SG_ 2654486529 CBV_bit4_ActiveWakeupBit 0;
BA_ "GenSigTimeoutTime_BCM" SG_ 2654486529 CBV_bit4_ActiveWakeupBit 0;
BA_ "GenSigTimeoutTime_BSM" SG_ 2654486529 CBV_bit4_ActiveWakeupBit 0;
BA_ "GenSigTimeoutTime_CADM" SG_ 2654486529 CBV_bit4_ActiveWakeupBit 0;
BA_ "GenSigTimeoutTime_DMSM" SG_ 2654486529 CBV_bit4_ActiveWakeupBit 0;
BA_ "GenSigTimeoutTime_DTCM" SG_ 2654486529 CBV_bit4_ActiveWakeupBit 0;
BA_ "GenSigTimeoutTime_ECM" SG_ 2654486529 CBV_bit4_ActiveWakeupBit 0;
BA_ "GenSigTimeoutTime_EVCU2" SG_ 2654486529 CBV_bit4_ActiveWakeupBit 0;
BA_ "GenSigTimeoutTime_GNMM" SG_ 2654486529 CBV_bit4_ActiveWakeupBit 0;
BA_ "GenSigTimeoutTime_HCP" SG_ 2654486529 CBV_bit4_ActiveWakeupBit 0;
BA_ "GenSigTimeoutTime_IPC" SG_ 2654486529 CBV_bit4_ActiveWakeupBit 0;
BA_ "GenSigTimeoutTime_RFHM" SG_ 2654486529 CBV_bit4_ActiveWakeupBit 0;
BA_ "GenSigTimeoutTime_SGW" SG_ 2654486529 CBV_bit4_ActiveWakeupBit 0;
BA_ "GenSigTimeoutTime_TCM" SG_ 2654486529 CBV_bit4_ActiveWakeupBit 0;
BA_ "GenSigTimeoutTime_AGSM" SG_ 2654486529 CBV_bit5 0;
BA_ "GenSigTimeoutTime_BCM" SG_ 2654486529 CBV_bit5 0;
BA_ "GenSigTimeoutTime_BSM" SG_ 2654486529 CBV_bit5 0;
BA_ "GenSigTimeoutTime_CADM" SG_ 2654486529 CBV_bit5 0;
BA_ "GenSigTimeoutTime_DMSM" SG_ 2654486529 CBV_bit5 0;
BA_ "GenSigTimeoutTime_DTCM" SG_ 2654486529 CBV_bit5 0;
BA_ "GenSigTimeoutTime_ECM" SG_ 2654486529 CBV_bit5 0;
BA_ "GenSigTimeoutTime_EVCU2" SG_ 2654486529 CBV_bit5 0;
BA_ "GenSigTimeoutTime_GNMM" SG_ 2654486529 CBV_bit5 0;
BA_ "GenSigTimeoutTime_HCP" SG_ 2654486529 CBV_bit5 0;
BA_ "GenSigTimeoutTime_IPC" SG_ 2654486529 CBV_bit5 0;
BA_ "GenSigTimeoutTime_RFHM" SG_ 2654486529 CBV_bit5 0;
BA_ "GenSigTimeoutTime_SGW" SG_ 2654486529 CBV_bit5 0;
BA_ "GenSigTimeoutTime_TCM" SG_ 2654486529 CBV_bit5 0;
BA_ "GenSigTimeoutTime_AGSM" SG_ 2654486529 CBV_bit6_PartialNtwInfBit 0;
BA_ "GenSigTimeoutTime_BCM" SG_ 2654486529 CBV_bit6_PartialNtwInfBit 0;
BA_ "GenSigTimeoutTime_BSM" SG_ 2654486529 CBV_bit6_PartialNtwInfBit 0;
BA_ "GenSigTimeoutTime_CADM" SG_ 2654486529 CBV_bit6_PartialNtwInfBit 0;
BA_ "GenSigTimeoutTime_DMSM" SG_ 2654486529 CBV_bit6_PartialNtwInfBit 0;
BA_ "GenSigTimeoutTime_DTCM" SG_ 2654486529 CBV_bit6_PartialNtwInfBit 0;
BA_ "GenSigTimeoutTime_ECM" SG_ 2654486529 CBV_bit6_PartialNtwInfBit 0;
BA_ "GenSigTimeoutTime_EVCU2" SG_ 2654486529 CBV_bit6_PartialNtwInfBit 0;
BA_ "GenSigTimeoutTime_GNMM" SG_ 2654486529 CBV_bit6_PartialNtwInfBit 0;
BA_ "GenSigTimeoutTime_HCP" SG_ 2654486529 CBV_bit6_PartialNtwInfBit 0;
BA_ "GenSigTimeoutTime_IPC" SG_ 2654486529 CBV_bit6_PartialNtwInfBit 0;
BA_ "GenSigTimeoutTime_RFHM" SG_ 2654486529 CBV_bit6_PartialNtwInfBit 0;
BA_ "GenSigTimeoutTime_SGW" SG_ 2654486529 CBV_bit6_PartialNtwInfBit 0;
BA_ "GenSigTimeoutTime_TCM" SG_ 2654486529 CBV_bit6_PartialNtwInfBit 0;
BA_ "GenSigTimeoutTime_AGSM" SG_ 2654486529 CBV_bit7 0;
BA_ "GenSigTimeoutTime_BCM" SG_ 2654486529 CBV_bit7 0;
BA_ "GenSigTimeoutTime_BSM" SG_ 2654486529 CBV_bit7 0;
BA_ "GenSigTimeoutTime_CADM" SG_ 2654486529 CBV_bit7 0;
BA_ "GenSigTimeoutTime_DMSM" SG_ 2654486529 CBV_bit7 0;
BA_ "GenSigTimeoutTime_DTCM" SG_ 2654486529 CBV_bit7 0;
BA_ "GenSigTimeoutTime_ECM" SG_ 2654486529 CBV_bit7 0;
BA_ "GenSigTimeoutTime_EVCU2" SG_ 2654486529 CBV_bit7 0;
BA_ "GenSigTimeoutTime_GNMM" SG_ 2654486529 CBV_bit7 0;
BA_ "GenSigTimeoutTime_HCP" SG_ 2654486529 CBV_bit7 0;
BA_ "GenSigTimeoutTime_IPC" SG_ 2654486529 CBV_bit7 0;
BA_ "GenSigTimeoutTime_RFHM" SG_ 2654486529 CBV_bit7 0;
BA_ "GenSigTimeoutTime_SGW" SG_ 2654486529 CBV_bit7 0;
BA_ "GenSigTimeoutTime_TCM" SG_ 2654486529 CBV_bit7 0;
BA_ "GenSigTimeoutTime_AGSM" SG_ 2654486529 SourceNodeIdentifier 0;
BA_ "GenSigTimeoutTime_BCM" SG_ 2654486529 SourceNodeIdentifier 0;
BA_ "GenSigTimeoutTime_BSM" SG_ 2654486529 SourceNodeIdentifier 0;
BA_ "GenSigTimeoutTime_CADM" SG_ 2654486529 SourceNodeIdentifier 0;
BA_ "GenSigTimeoutTime_DMSM" SG_ 2654486529 SourceNodeIdentifier 0;
BA_ "GenSigTimeoutTime_DTCM" SG_ 2654486529 SourceNodeIdentifier 0;
BA_ "GenSigTimeoutTime_ECM" SG_ 2654486529 SourceNodeIdentifier 0;
BA_ "GenSigTimeoutTime_EVCU2" SG_ 2654486529 SourceNodeIdentifier 0;
BA_ "GenSigTimeoutTime_GNMM" SG_ 2654486529 SourceNodeIdentifier 0;
BA_ "GenSigTimeoutTime_HCP" SG_ 2654486529 SourceNodeIdentifier 0;
BA_ "GenSigTimeoutTime_IPC" SG_ 2654486529 SourceNodeIdentifier 0;
BA_ "GenSigTimeoutTime_RFHM" SG_ 2654486529 SourceNodeIdentifier 0;
BA_ "GenSigTimeoutTime_SGW" SG_ 2654486529 SourceNodeIdentifier 0;
BA_ "GenSigTimeoutTime_TCM" SG_ 2654486529 SourceNodeIdentifier 0;
BA_ "GenSigTimeoutTime_AGSM" SG_ 2654486592 CBV_bit0_RepeatMessageRequestBit 0;
BA_ "GenSigTimeoutTime_BCM" SG_ 2654486592 CBV_bit0_RepeatMessageRequestBit 0;
BA_ "GenSigTimeoutTime_BSM" SG_ 2654486592 CBV_bit0_RepeatMessageRequestBit 0;
BA_ "GenSigTimeoutTime_CADM" SG_ 2654486592 CBV_bit0_RepeatMessageRequestBit 0;
BA_ "GenSigTimeoutTime_DMSM" SG_ 2654486592 CBV_bit0_RepeatMessageRequestBit 0;
BA_ "GenSigTimeoutTime_DTCM" SG_ 2654486592 CBV_bit0_RepeatMessageRequestBit 0;
BA_ "GenSigTimeoutTime_ECM" SG_ 2654486592 CBV_bit0_RepeatMessageRequestBit 0;
BA_ "GenSigTimeoutTime_EVCU2" SG_ 2654486592 CBV_bit0_RepeatMessageRequestBit 0;
BA_ "GenSigTimeoutTime_GNMM" SG_ 2654486592 CBV_bit0_RepeatMessageRequestBit 0;
BA_ "GenSigTimeoutTime_HCP" SG_ 2654486592 CBV_bit0_RepeatMessageRequestBit 0;
BA_ "GenSigTimeoutTime_IPC" SG_ 2654486592 CBV_bit0_RepeatMessageRequestBit 0;
BA_ "GenSigTimeoutTime_RFHM" SG_ 2654486592 CBV_bit0_RepeatMessageRequestBit 0;
BA_ "GenSigTimeoutTime_SGW" SG_ 2654486592 CBV_bit0_RepeatMessageRequestBit 0;
BA_ "GenSigTimeoutTime_TCM" SG_ 2654486592 CBV_bit0_RepeatMessageRequestBit 0;
BA_ "GenSigTimeoutTime_AGSM" SG_ 2654486592 CBV_bit1 0;
BA_ "GenSigTimeoutTime_BCM" SG_ 2654486592 CBV_bit1 0;
BA_ "GenSigTimeoutTime_BSM" SG_ 2654486592 CBV_bit1 0;
BA_ "GenSigTimeoutTime_CADM" SG_ 2654486592 CBV_bit1 0;
BA_ "GenSigTimeoutTime_DMSM" SG_ 2654486592 CBV_bit1 0;
BA_ "GenSigTimeoutTime_DTCM" SG_ 2654486592 CBV_bit1 0;
BA_ "GenSigTimeoutTime_ECM" SG_ 2654486592 CBV_bit1 0;
BA_ "GenSigTimeoutTime_EVCU2" SG_ 2654486592 CBV_bit1 0;
BA_ "GenSigTimeoutTime_GNMM" SG_ 2654486592 CBV_bit1 0;
BA_ "GenSigTimeoutTime_HCP" SG_ 2654486592 CBV_bit1 0;
BA_ "GenSigTimeoutTime_IPC" SG_ 2654486592 CBV_bit1 0;
BA_ "GenSigTimeoutTime_RFHM" SG_ 2654486592 CBV_bit1 0;
BA_ "GenSigTimeoutTime_SGW" SG_ 2654486592 CBV_bit1 0;
BA_ "GenSigTimeoutTime_TCM" SG_ 2654486592 CBV_bit1 0;
BA_ "GenSigTimeoutTime_AGSM" SG_ 2654486592 CBV_bit2 0;
BA_ "GenSigTimeoutTime_BCM" SG_ 2654486592 CBV_bit2 0;
BA_ "GenSigTimeoutTime_BSM" SG_ 2654486592 CBV_bit2 0;
BA_ "GenSigTimeoutTime_CADM" SG_ 2654486592 CBV_bit2 0;
BA_ "GenSigTimeoutTime_DMSM" SG_ 2654486592 CBV_bit2 0;
BA_ "GenSigTimeoutTime_DTCM" SG_ 2654486592 CBV_bit2 0;
BA_ "GenSigTimeoutTime_ECM" SG_ 2654486592 CBV_bit2 0;
BA_ "GenSigTimeoutTime_EVCU2" SG_ 2654486592 CBV_bit2 0;
BA_ "GenSigTimeoutTime_GNMM" SG_ 2654486592 CBV_bit2 0;
BA_ "GenSigTimeoutTime_HCP" SG_ 2654486592 CBV_bit2 0;
BA_ "GenSigTimeoutTime_IPC" SG_ 2654486592 CBV_bit2 0;
BA_ "GenSigTimeoutTime_RFHM" SG_ 2654486592 CBV_bit2 0;
BA_ "GenSigTimeoutTime_SGW" SG_ 2654486592 CBV_bit2 0;
BA_ "GenSigTimeoutTime_TCM" SG_ 2654486592 CBV_bit2 0;
BA_ "GenSigTimeoutTime_AGSM" SG_ 2654486592 CBV_bit3_NMCoordinatorBit 0;
BA_ "GenSigTimeoutTime_BCM" SG_ 2654486592 CBV_bit3_NMCoordinatorBit 0;
BA_ "GenSigTimeoutTime_BSM" SG_ 2654486592 CBV_bit3_NMCoordinatorBit 0;
BA_ "GenSigTimeoutTime_CADM" SG_ 2654486592 CBV_bit3_NMCoordinatorBit 0;
BA_ "GenSigTimeoutTime_DMSM" SG_ 2654486592 CBV_bit3_NMCoordinatorBit 0;
BA_ "GenSigTimeoutTime_DTCM" SG_ 2654486592 CBV_bit3_NMCoordinatorBit 0;
BA_ "GenSigTimeoutTime_ECM" SG_ 2654486592 CBV_bit3_NMCoordinatorBit 0;
BA_ "GenSigTimeoutTime_EVCU2" SG_ 2654486592 CBV_bit3_NMCoordinatorBit 0;
BA_ "GenSigTimeoutTime_GNMM" SG_ 2654486592 CBV_bit3_NMCoordinatorBit 0;
BA_ "GenSigTimeoutTime_HCP" SG_ 2654486592 CBV_bit3_NMCoordinatorBit 0;
BA_ "GenSigTimeoutTime_IPC" SG_ 2654486592 CBV_bit3_NMCoordinatorBit 0;
BA_ "GenSigTimeoutTime_RFHM" SG_ 2654486592 CBV_bit3_NMCoordinatorBit 0;
BA_ "GenSigTimeoutTime_SGW" SG_ 2654486592 CBV_bit3_NMCoordinatorBit 0;
BA_ "GenSigTimeoutTime_TCM" SG_ 2654486592 CBV_bit3_NMCoordinatorBit 0;
BA_ "GenSigTimeoutTime_AGSM" SG_ 2654486592 CBV_bit4_ActiveWakeupBit 0;
BA_ "GenSigTimeoutTime_BCM" SG_ 2654486592 CBV_bit4_ActiveWakeupBit 0;
BA_ "GenSigTimeoutTime_BSM" SG_ 2654486592 CBV_bit4_ActiveWakeupBit 0;
BA_ "GenSigTimeoutTime_CADM" SG_ 2654486592 CBV_bit4_ActiveWakeupBit 0;
BA_ "GenSigTimeoutTime_DMSM" SG_ 2654486592 CBV_bit4_ActiveWakeupBit 0;
BA_ "GenSigTimeoutTime_DTCM" SG_ 2654486592 CBV_bit4_ActiveWakeupBit 0;
BA_ "GenSigTimeoutTime_ECM" SG_ 2654486592 CBV_bit4_ActiveWakeupBit 0;
BA_ "GenSigTimeoutTime_EVCU2" SG_ 2654486592 CBV_bit4_ActiveWakeupBit 0;
BA_ "GenSigTimeoutTime_GNMM" SG_ 2654486592 CBV_bit4_ActiveWakeupBit 0;
BA_ "GenSigTimeoutTime_HCP" SG_ 2654486592 CBV_bit4_ActiveWakeupBit 0;
BA_ "GenSigTimeoutTime_IPC" SG_ 2654486592 CBV_bit4_ActiveWakeupBit 0;
BA_ "GenSigTimeoutTime_RFHM" SG_ 2654486592 CBV_bit4_ActiveWakeupBit 0;
BA_ "GenSigTimeoutTime_SGW" SG_ 2654486592 CBV_bit4_ActiveWakeupBit 0;
BA_ "GenSigTimeoutTime_TCM" SG_ 2654486592 CBV_bit4_ActiveWakeupBit 0;
BA_ "GenSigTimeoutTime_AGSM" SG_ 2654486592 CBV_bit5 0;
BA_ "GenSigTimeoutTime_BCM" SG_ 2654486592 CBV_bit5 0;
BA_ "GenSigTimeoutTime_BSM" SG_ 2654486592 CBV_bit5 0;
BA_ "GenSigTimeoutTime_CADM" SG_ 2654486592 CBV_bit5 0;
BA_ "GenSigTimeoutTime_DMSM" SG_ 2654486592 CBV_bit5 0;
BA_ "GenSigTimeoutTime_DTCM" SG_ 2654486592 CBV_bit5 0;
BA_ "GenSigTimeoutTime_ECM" SG_ 2654486592 CBV_bit5 0;
BA_ "GenSigTimeoutTime_EVCU2" SG_ 2654486592 CBV_bit5 0;
BA_ "GenSigTimeoutTime_GNMM" SG_ 2654486592 CBV_bit5 0;
BA_ "GenSigTimeoutTime_HCP" SG_ 2654486592 CBV_bit5 0;
BA_ "GenSigTimeoutTime_IPC" SG_ 2654486592 CBV_bit5 0;
BA_ "GenSigTimeoutTime_RFHM" SG_ 2654486592 CBV_bit5 0;
BA_ "GenSigTimeoutTime_SGW" SG_ 2654486592 CBV_bit5 0;
BA_ "GenSigTimeoutTime_TCM" SG_ 2654486592 CBV_bit5 0;
BA_ "GenSigTimeoutTime_AGSM" SG_ 2654486592 CBV_bit6_PartialNtwInfBit 0;
BA_ "GenSigTimeoutTime_BCM" SG_ 2654486592 CBV_bit6_PartialNtwInfBit 0;
BA_ "GenSigTimeoutTime_BSM" SG_ 2654486592 CBV_bit6_PartialNtwInfBit 0;
BA_ "GenSigTimeoutTime_CADM" SG_ 2654486592 CBV_bit6_PartialNtwInfBit 0;
BA_ "GenSigTimeoutTime_DMSM" SG_ 2654486592 CBV_bit6_PartialNtwInfBit 0;
BA_ "GenSigTimeoutTime_DTCM" SG_ 2654486592 CBV_bit6_PartialNtwInfBit 0;
BA_ "GenSigTimeoutTime_ECM" SG_ 2654486592 CBV_bit6_PartialNtwInfBit 0;
BA_ "GenSigTimeoutTime_EVCU2" SG_ 2654486592 CBV_bit6_PartialNtwInfBit 0;
BA_ "GenSigTimeoutTime_GNMM" SG_ 2654486592 CBV_bit6_PartialNtwInfBit 0;
BA_ "GenSigTimeoutTime_HCP" SG_ 2654486592 CBV_bit6_PartialNtwInfBit 0;
BA_ "GenSigTimeoutTime_IPC" SG_ 2654486592 CBV_bit6_PartialNtwInfBit 0;
BA_ "GenSigTimeoutTime_RFHM" SG_ 2654486592 CBV_bit6_PartialNtwInfBit 0;
BA_ "GenSigTimeoutTime_SGW" SG_ 2654486592 CBV_bit6_PartialNtwInfBit 0;
BA_ "GenSigTimeoutTime_TCM" SG_ 2654486592 CBV_bit6_PartialNtwInfBit 0;
BA_ "GenSigTimeoutTime_AGSM" SG_ 2654486592 CBV_bit7 0;
BA_ "GenSigTimeoutTime_BCM" SG_ 2654486592 CBV_bit7 0;
BA_ "GenSigTimeoutTime_BSM" SG_ 2654486592 CBV_bit7 0;
BA_ "GenSigTimeoutTime_CADM" SG_ 2654486592 CBV_bit7 0;
BA_ "GenSigTimeoutTime_DMSM" SG_ 2654486592 CBV_bit7 0;
BA_ "GenSigTimeoutTime_DTCM" SG_ 2654486592 CBV_bit7 0;
BA_ "GenSigTimeoutTime_ECM" SG_ 2654486592 CBV_bit7 0;
BA_ "GenSigTimeoutTime_EVCU2" SG_ 2654486592 CBV_bit7 0;
BA_ "GenSigTimeoutTime_GNMM" SG_ 2654486592 CBV_bit7 0;
BA_ "GenSigTimeoutTime_HCP" SG_ 2654486592 CBV_bit7 0;
BA_ "GenSigTimeoutTime_IPC" SG_ 2654486592 CBV_bit7 0;
BA_ "GenSigTimeoutTime_RFHM" SG_ 2654486592 CBV_bit7 0;
BA_ "GenSigTimeoutTime_SGW" SG_ 2654486592 CBV_bit7 0;
BA_ "GenSigTimeoutTime_TCM" SG_ 2654486592 CBV_bit7 0;
BA_ "GenSigTimeoutTime_AGSM" SG_ 2654486592 SourceNodeIdentifier 0;
BA_ "GenSigTimeoutTime_BCM" SG_ 2654486592 SourceNodeIdentifier 0;
BA_ "GenSigTimeoutTime_BSM" SG_ 2654486592 SourceNodeIdentifier 0;
BA_ "GenSigTimeoutTime_CADM" SG_ 2654486592 SourceNodeIdentifier 0;
BA_ "GenSigTimeoutTime_DMSM" SG_ 2654486592 SourceNodeIdentifier 0;
BA_ "GenSigTimeoutTime_DTCM" SG_ 2654486592 SourceNodeIdentifier 0;
BA_ "GenSigTimeoutTime_ECM" SG_ 2654486592 SourceNodeIdentifier 0;
BA_ "GenSigTimeoutTime_EVCU2" SG_ 2654486592 SourceNodeIdentifier 0;
BA_ "GenSigTimeoutTime_GNMM" SG_ 2654486592 SourceNodeIdentifier 0;
BA_ "GenSigTimeoutTime_HCP" SG_ 2654486592 SourceNodeIdentifier 0;
BA_ "GenSigTimeoutTime_IPC" SG_ 2654486592 SourceNodeIdentifier 0;
BA_ "GenSigTimeoutTime_RFHM" SG_ 2654486592 SourceNodeIdentifier 0;
BA_ "GenSigTimeoutTime_SGW" SG_ 2654486592 SourceNodeIdentifier 0;
BA_ "GenSigTimeoutTime_TCM" SG_ 2654486592 SourceNodeIdentifier 0;
VAL_ 1443 Act_Lane_Mgt 0 "Vib_Only" 1 "Steer_Asst_Only" 2 "Vib_Steer_Asst";
VAL_ 1443 Act_Lane_Mgt_Strength 0 "Low" 1 "Medium" 2 "High";
VAL_ 1443 Active_Park_Mode 0 "Full_Auto" 1 "Steering_Only";
VAL_ 1443 Active_Park_Prox_Chime 0 "Off" 1 "On";
VAL_ 1443 AmbientLightingLevel 0 "Level_1" 1 "Level_2" 2 "Level_3" 3 "Level_4" 4 "Level_5" 5 "Level_6" 6 "Level_7" 7 "Level_8" 8 "Level_9" 9 "Level_10" 10 "Level_11" 11 "Level_12" 12 "Level_13" 13 "Level_14" 14 "Level_15" 15 "Level_16";
VAL_ 1443 Auto_Fold_Mirr 0 "Off" 1 "On";
VAL_ 1443 AutoHighBeamEnable 0 "Not_Enable" 1 "Enable";
VAL_ 1443 AutoParkBrake 0 "On" 1 "Off";
VAL_ 1443 AutoUnlockDoorExit 0 "Not_Enable" 1 "Enable";
VAL_ 1443 Backup_Cam_Delay 0 "Off" 1 "On";
VAL_ 1443 BSDEnable 0 "Not_Enable" 1 "Enable_LED" 2 "Enable_ LED_Chime";
VAL_ 1443 Consum_Unit 0 "Km_Per_Litre" 1 "Litres_Per_100Km" 2 "Miles_Per_Gallon_UK" 3 "Miles_Per_Gallon_US" 4 "km/kWh" 5 "kWh/100km" 6 "mi/kWh" 7 "kWh/mi";
VAL_ 1443 CorneringEnable 0 "True" 1 "False";
VAL_ 1443 Dist_Unit 0 "km" 1 "miles";
VAL_ 1443 DRLEnable 0 "True" 1 "False";
VAL_ 1443 Drowsy_Driver_Alert 0 "Off" 1 "On";
VAL_ 1443 DynamicGrid 0 "Dynamic Gridlines OFF" 1 "Dynamic Gridlines ON";
VAL_ 1443 Easy_Exit_D 0 "Off" 1 "On";
VAL_ 1443 Eng_Off_Pwr_Delay 0 "Zero" 1 "Fourty_Five_Sec" 2 "Five_Min" 3 "Ten_Min";
VAL_ 1443 EPB_MaintenanceMode 0 "Off" 1 "On";
VAL_ 1443 FlashLightWLock 0 "Off" 1 "On";
VAL_ 1443 FOA_AppAlert_Disable_UserReq 0 "Not_Active" 1 "Active";
VAL_ 1443 FSFCWPlusActivationMode 0 "Near" 1 "Med" 2 "Far";
VAL_ 1443 FSFCWPlusSetting 0 "Off" 1 "Audio" 2 "Brake" 3 "Audio_Brake" 4 "Not_Request";
VAL_ 1443 Fwrd_Cam_Guidelines 0 "Off" 1 "On";
VAL_ 1443 GreetingLightsEnable 0 "True" 1 "False";
VAL_ 1443 HeadlightsOffDelay 0 "0sec" 1 "30sec" 2 "60sec" 3 "90ec";
VAL_ 1443 HeadLightWipers 0 "Off" 1 "On";
VAL_ 1443 Hill_Start_Assist 0 "Off" 1 "On";
VAL_ 1443 HourMode 0 "0_24_h" 1 "0_12_h";
VAL_ 1443 HP_Unit 0 "HP" 1 "kW" 2 "PS";
VAL_ 1443 Illuminated_Approach 0 "Zero" 1 "Thirty" 2 "Sixty" 3 "Ninety";
VAL_ 1443 IPCProgrammed 0 "Not_Programmed" 1 "Programmed";
VAL_ 1443 LanguageSelection 0 "Italian" 1 "Deutsch" 2 "English" 3 "Espanol" 4 "Francais" 5 "Portugues" 6 "Polish" 7 "Dutch" 8 "Brazilian" 9 "Turkish" 10 "Mexican" 11 "English_US" 12 "Canadian" 13 "Russian" 14 "Chinese" 15 "Japanese" 16 "Korean" 17 "Arabic" 18 "Czech" 19 "Slovakian" 20 "Hungarian" 21 "Hindi";
VAL_ 1443 LDW_Intensity 0 "Low" 1 "Med" 2 "High";
VAL_ 1443 LDW_Sensibility 0 "Early" 1 "Med" 2 "Late";
VAL_ 1443 NavRepetition 0 "Absent" 1 "Present";
VAL_ 1443 New_Spd_Zone_Ind 0 "Off" 1 "Visual" 2 "Chime" 3 "Visual_Chime";
VAL_ 1443 Paddle_Shifter 0 "Off" 1 "On";
VAL_ 1443 PamChimeVolumeFront 0 "Low" 1 "Medium" 2 "High";
VAL_ 1443 PamChimeVolumeRear 0 "Low" 1 "Medium" 2 "High";
VAL_ 1443 PassiveEntry 0 "On" 1 "Off";
VAL_ 1443 Ped_EM_Brk_Warn_Act 0 "Off" 1 "On";
VAL_ 1443 PhoneRepetition 0 "Absent" 1 "Present";
VAL_ 1443 PLGAlert 0 "Off" 1 "On";
VAL_ 1443 Power_Side_Step 0 "Auto" 1 "Store";
VAL_ 1443 Proximity_WU 0 "Off" 1 "On";
VAL_ 1443 PwrLev 0 "Level1" 1 "Level2" 2 "Level3" 3 "Level4" 4 "Level5";
VAL_ 1443 RainSensorLevel 0 "Not_Enable" 1 "Enable";
VAL_ 1443 Rdy_To_Drive 0 "Off" 1 "On";
VAL_ 1443 Rear_Brk_Asst 0 "Warn" 1 "Warn_Braking";
VAL_ 1443 RemoteDoorUnlock 0 "Driver" 1 "All";
VAL_ 1443 RemStNrmlStEnbl 0 "Off" 1 "Remote_Start_Only" 2 "Remote_And_Normal_Start" 3 "Normal_Start_Only";
VAL_ 1443 RKEMemoryLinkEnable 0 "Off" 1 "On";
VAL_ 1443 SOC_Max_Lev 0 "Level1" 1 "Level2";
VAL_ 1443 SoundHornLock 0 "Off" 1 "1st Press" 2 "2nd Press";
VAL_ 1443 SoundHornRemoteStart 0 "On" 1 "Off";
VAL_ 1443 Spaak 0 "Off" 1 "On";
VAL_ 1443 Speed_Unit 0 "mph" 1 "kph";
VAL_ 1443 SpeedLockDoorEnable 0 "Not_Enable" 1 "Enable";
VAL_ 1443 StaticGrid 0 "Static Gridlines OFF" 1 "Static Gridlines ON";
VAL_ 1443 Susp_Auto_Ent_Ext 0 "Off" 1 "On";
VAL_ 1443 Susp_Aux_Mode 0 "Off" 1 "Transport" 2 "Wheel_Alignment" 3 "Bed_Lowering";
VAL_ 1443 Susp_Disp_Message 0 "All" 1 "Warnings_Only";
VAL_ 1443 Susp_Flsh_Lght_Low 0 "Off" 1 "On";
VAL_ 1443 Susp_Sound_Hrn_Low 0 "Off" 1 "On";
VAL_ 1443 Susp_Tire_Jack 0 "Off" 1 "On";
VAL_ 1443 SVC_Delay 0 "Off" 1 "On";
VAL_ 1443 SVC_Guidelines 0 "Off" 1 "On";
VAL_ 1443 TelematicSetupACK 0 "No_ACK_Required" 1 "ACK_KO" 3 "ACK_OK";
VAL_ 1443 Temp_Unit 0 "°C" 1 "°F";
VAL_ 1443 Tilt_Mirr_Rev 0 "Off" 1 "On";
VAL_ 1443 Tire_Fill_Alert 0 "Off" 1 "On";
VAL_ 1443 Torque_Unit 0 "Nm" 1 "lb_ft";
VAL_ 1443 Traffic_Sign_Info 0 "Off" 1 "On";
VAL_ 1443 Traffic_Sign_Warn 0 "Off" 1 "Visual" 2 "Visual_Chime";
VAL_ 1443 Trail_Brk_Type 0 "Light_Electric" 1 "Heavy_Electric" 2 "Light_Electric_Over_Hydraulic" 3 "Heavy_Electric_Over_Hydraulic";
VAL_ 1443 Trail_Name 0 "Trailer" 1 "Boat" 2 "Car" 3 "Cargo" 4 "Dump" 5 "Equipment" 6 "Flatbed" 7 "Gooseneck" 8 "Horse" 9 "Livestock" 10 "Motorcycle" 11 "Snow_Mobile" 12 "Travel" 13 "Utility" 14 "Fifth_Wheel";
VAL_ 1443 Trail_Num 0 "One" 1 "Two" 2 "Three" 3 "Four";
VAL_ 1443 Trailer_detection_blind_spot 0 "Auto" 1 "Max";
VAL_ 1443 TyrePress_Unit 0 "KPa" 1 "psi" 2 "bar";
VAL_ 1474 AUX1_HLEnbl 0 "Disable" 1 "Enable";
VAL_ 1474 AUX1_PWRMD 0 "Ignition" 1 "Battery";
VAL_ 1474 AUX1_TYPE 0 "Latching" 1 "Momentary";
VAL_ 1474 AUX2_HLEnbl 0 "Disable" 1 "Enable";
VAL_ 1474 AUX2_PWRMD 0 "Ignition" 1 "Battery";
VAL_ 1474 AUX2_TYPE 0 "Latching" 1 "Momentary";
VAL_ 1474 AUX3_HLEnbl 0 "Disable" 1 "Enable";
VAL_ 1474 AUX3_PWRMD 0 "Ignition" 1 "Battery";
VAL_ 1474 AUX3_TYPE 0 "Latching" 1 "Momentary";
VAL_ 1474 AUX4_HLEnbl 0 "Disable" 1 "Enable";
VAL_ 1474 AUX4_PWRMD 0 "Ignition" 1 "Battery";
VAL_ 1474 AUX4_TYPE 0 "Latching" 1 "Momentary";
VAL_ 1474 AUX5_HLEnbl 0 "Disable" 1 "Enable";
VAL_ 1474 AUX5_PWRMD 0 "IGNITION" 1 "BATTERY";
VAL_ 1474 AUX5_TYPE 0 "Latching" 1 "Momentary";
VAL_ 1474 AUX6_HLEnbl 0 "Disable" 1 "Enable";
VAL_ 1474 AUX6_PWRMD 0 "IGNITION" 1 "BATTERY";
VAL_ 1474 AUX6_TYPE 0 "Latching" 1 "Momentary";
VAL_ 1474 Default_Ride_Height 0 "Normal" 1 "Aerodynamic";
VAL_ 1474 Display_Synch 0 "OFF" 1 "ON";
VAL_ 1474 EPB_Service_Mode 0 "Disable" 1 "Enable";
VAL_ 1474 FOA_Alert_Type 0 "Off" 1 "Cluster_Warning" 2 "Cluster_SMS_Warning";
VAL_ 1474 Fuel_Saver_Display 0 "Disable" 1 "Enable";
VAL_ 1474 ParkSenseSignalView 0 "DISABLE" 1 "ENABLE";
VAL_ 1474 PFTM_Alert 0 "Disabled" 1 "Enabled";
VAL_ 1474 PFTM_Enable 0 "Disabled" 1 "Enabled";
VAL_ 1474 Power_Tailgate_Enable 0 "Disabled" 1 "Enabled";
VAL_ 1474 Rear_G_LGT_with_Cargo_Lights 0 "Disable" 1 "Enable";
VAL_ 1474 Rear_Guidance_Light_Status 0 "OFF" 1 "ON";
VAL_ 1474 Rear_Lights_with_Approach 0 "Off_with_Approach" 1 "On_with_Approach";
VAL_ 1474 SignatureLightingEnable 0 "DISABLE" 1 "ENABLE";
VAL_ 1474 Trailer_Light_Check 0 "Disable" 1 "Enable";
VAL_ 1474 TSI_Offset_Kph 0 "0" 1 "1" 2 "2" 3 "3" 4 "4" 5 "5" 6 "6" 7 "7" 8 "8" 9 "9" 10 "10" 11 "11" 12 "12" 13 "13" 14 "14" 15 "15";
VAL_ 1474 TSI_Offset_Mph 0 "0" 1 "1" 2 "2" 3 "3" 4 "4" 5 "5" 6 "6" 7 "7" 8 "8" 9 "9" 10 "10";
VAL_ 1474 TurnSignalView 0 "Disable" 1 "Enable" 2 "Only_with_Trailer";
VAL_ 1474 WorksiteINVM_Audible_LFW 0 "OFF" 1 "ON";
VAL_ 1474 WorksiteINVM_Visual_LFW 0 "OFF" 1 "ON";
VAL_ 753 DCDC_OperationModeSts 0 "IDLE" 1 "Buck_CV" 2 "Buck_CC" 3 "Buck_CP" 4 "Buck_Special" 5 "Boost" 6 "Precharge" 7 "Discharge" 8 "Failure" 15 "SNA";
VAL_ 753 HVDC_CurrentFeedback 4095 "SNA";
VAL_ 753 HVDC_VoltageFeedback 4095 "SNA";
VAL_ 753 LVDC_CurrentFeedback 4095 "SNA";
VAL_ 2654486550 CBV_bit0_RepeatMessageRequestBit 0 "Repeat_Message_State_not_requested" 1 "Repeat_Message_State_requested";
VAL_ 2654486550 CBV_bit3_NMCoordinatorBit 0 "Start_of_synchronized_shutdown_is_not_requested_by_main_coordinator" 1 "Start_of_synchronized_shutdown_is_requested_by_main_coordinator";
VAL_ 2654486550 CBV_bit4_ActiveWakeupBit 0 "PassiveWakeup" 1 "ActiveWakeup";
VAL_ 2654486550 CBV_bit6_PartialNtwInfBit 0 "NM_PDU_contains_no_Partial_Network_request_information" 1 "NM_PDU_contains_Partial_Network_request_information";
VAL_ 2654486528 CBV_bit0_RepeatMessageRequestBit 0 "Repeat_Message_State_not_requested" 1 "Repeat_Message_State_requested";
VAL_ 2654486528 CBV_bit3_NMCoordinatorBit 0 "Start_of_synchronized_shutdown_is_not_requested_by_main_coordinator" 1 "Start_of_synchronized_shutdown_is_requested_by_main_coordinator";
VAL_ 2654486528 CBV_bit4_ActiveWakeupBit 0 "PassiveWakeup" 1 "ActiveWakeup";
VAL_ 2654486528 CBV_bit6_PartialNtwInfBit 0 "NM_PDU_contains_no_Partial_Network_request_information" 1 "NM_PDU_contains_Partial_Network_request_information";
VAL_ 2654486534 CBV_bit0_RepeatMessageRequestBit 0 "Repeat_Message_State_not_requested" 1 "Repeat_Message_State_requested";
VAL_ 2654486534 CBV_bit3_NMCoordinatorBit 0 "Start_of_synchronized_shutdown_is_not_requested_by_main_coordinator" 1 "Start_of_synchronized_shutdown_is_requested_by_main_coordinator";
VAL_ 2654486534 CBV_bit4_ActiveWakeupBit 0 "PassiveWakeup" 1 "ActiveWakeup";
VAL_ 2654486534 CBV_bit6_PartialNtwInfBit 0 "NM_PDU_contains_no_Partial_Network_request_information" 1 "NM_PDU_contains_Partial_Network_request_information";
VAL_ 2654486669 CBV_bit0_RepeatMessageRequestBit 0 "Repeat_Message_State_not_requested" 1 "Repeat_Message_State_requested";
VAL_ 2654486669 CBV_bit3_NMCoordinatorBit 0 "Start_of_synchronized_shutdown_is_not_requested_by_main_coordinator" 1 "Start_of_synchronized_shutdown_is_requested_by_main_coordinator";
VAL_ 2654486669 CBV_bit4_ActiveWakeupBit 0 "PassiveWakeup" 1 "ActiveWakeup";
VAL_ 2654486669 CBV_bit6_PartialNtwInfBit 0 "NM_PDU_contains_no_Partial_Network_request_information" 1 "NM_PDU_contains_Partial_Network_request_information";
VAL_ 2654486595 CBV_bit0_RepeatMessageRequestBit 0 "Repeat_Message_State_not_requested" 1 "Repeat_Message_State_requested";
VAL_ 2654486595 CBV_bit3_NMCoordinatorBit 0 "Start_of_synchronized_shutdown_is_not_requested_by_main_coordinator" 1 "Start_of_synchronized_shutdown_is_requested_by_main_coordinator";
VAL_ 2654486595 CBV_bit4_ActiveWakeupBit 0 "PassiveWakeup" 1 "ActiveWakeup";
VAL_ 2654486595 CBV_bit6_PartialNtwInfBit 0 "NM_PDU_contains_no_Partial_Network_request_information" 1 "NM_PDU_contains_Partial_Network_request_information";
VAL_ 2654486529 CBV_bit0_RepeatMessageRequestBit 0 "Repeat_Message_State_not_requested" 1 "Repeat_Message_State_requested";
VAL_ 2654486529 CBV_bit3_NMCoordinatorBit 0 "Start_of_synchronized_shutdown_is_not_requested_by_main_coordinator" 1 "Start_of_synchronized_shutdown_is_requested_by_main_coordinator";
VAL_ 2654486529 CBV_bit4_ActiveWakeupBit 0 "PassiveWakeup" 1 "ActiveWakeup";
VAL_ 2654486529 CBV_bit6_PartialNtwInfBit 0 "NM_PDU_contains_no_Partial_Network_request_information" 1 "NM_PDU_contains_Partial_Network_request_information";
VAL_ 2654486592 CBV_bit4_ActiveWakeupBit 0 "PassiveWakeup" 1 "ActiveWakeup";
